VERSION "dbc-export 1 2025.20.8"

NS_ :

BS_:

BU_: ADSP APB APP APS APSB BB BMS CC CMP CMPD CP DAS DI DIF DIR DPB EPAS3P EPAS3S EPASTP EPASTS EPBL EPBR ESP EVSE FC GTW HCML HCMR HVP IBST ICR IDB LS OCS1P ODIN PARK PCS PLG PM PMF PMR PNCD PTC RADC RCM RCM2 RCM3 RCU SCCM SCM SCS SDCR TAS TCU TPMS TRCM UDS UI UIS UMC USM VC VCFRONT VCLEFT VCRIGHT VCSEC VEH

BO_ 1513 APP_alertLog: 8 APP
 SG_ APP_alertID M : 0|14@1+ (1,0) [0|16383] "" Vector__XXX
 SG_ APP_sw188_minTemperature m188 : 48|8@1+ (1,-60) [-60|194] "degC" Vector__XXX
 SG_ APP_sw188_maxTemperature m188 : 56|8@1+ (1,-60) [-60|194] "degC" Vector__XXX
 SG_ APP_sw189_exitStatus m189 : 16|1@1+ (1,0) [0|1] "" Vector__XXX
 SG_ APP_sw189_bufferError m189 : 17|1@1+ (1,0) [0|1] "" Vector__XXX
 SG_ APP_sw189_frameGrabFailure m189 : 18|1@1+ (1,0) [0|1] "" Vector__XXX
 SG_ APP_sw189_gainControlFailure m189 : 19|1@1+ (1,0) [0|1] "" Vector__XXX
 SG_ APP_sw189_tempMonitorFailure m189 : 20|2@1+ (1,0) [0|3] "" Vector__XXX
 SG_ APP_sw189_firstFrameGrabFailure m189 : 22|1@1+ (1,0) [0|1] "" Vector__XXX
 SG_ APP_sw189_deserParityError m189 : 23|1@1+ (1,0) [0|1] "" Vector__XXX
 SG_ APP_sw189_deserLockError m189 : 24|1@1+ (1,0) [0|1] "" Vector__XXX
 SG_ APP_sw189_deserCrcError m189 : 25|1@1+ (1,0) [0|1] "" Vector__XXX
 SG_ APP_sw189_imagerHeartbeat m189 : 26|2@1+ (1,0) [0|2] "" Vector__XXX
 SG_ APP_sw189_serializerCrcErrCount m189 : 28|8@1+ (1,0) [0|254] "" Vector__XXX
 SG_ APP_sw189_deserLineLengthError m189 : 36|1@1+ (1,0) [0|1] "" Vector__XXX
 SG_ APP_sw189_numCaptureRecoveries m189 : 37|3@1+ (1,0) [0|7] "" Vector__XXX
 SG_ APP_sw189_currentTemperature m189 : 40|8@1+ (1,-60) [-60|194] "degC" Vector__XXX
 SG_ APP_sw189_minTemperature m189 : 48|8@1+ (1,-60) [-60|194] "degC" Vector__XXX
 SG_ APP_sw189_maxTemperature m189 : 56|8@1+ (1,-60) [-60|194] "degC" Vector__XXX
 SG_ APP_sw190_exitStatus m190 : 16|1@1+ (1,0) [0|1] "" Vector__XXX
 SG_ APP_sw190_bufferError m190 : 17|1@1+ (1,0) [0|1] "" Vector__XXX
 SG_ APP_sw190_frameGrabFailure m190 : 18|1@1+ (1,0) [0|1] "" Vector__XXX
 SG_ APP_sw190_gainControlFailure m190 : 19|1@1+ (1,0) [0|1] "" Vector__XXX
 SG_ APP_sw190_tempMonitorFailure m190 : 20|2@1+ (1,0) [0|3] "" Vector__XXX
 SG_ APP_sw190_firstFrameGrabFailure m190 : 22|1@1+ (1,0) [0|1] "" Vector__XXX
 SG_ APP_sw190_deserParityError m190 : 23|1@1+ (1,0) [0|1] "" Vector__XXX
 SG_ APP_sw190_deserLockError m190 : 24|1@1+ (1,0) [0|1] "" Vector__XXX
 SG_ APP_sw190_deserCrcError m190 : 25|1@1+ (1,0) [0|1] "" Vector__XXX
 SG_ APP_sw190_imagerHeartbeat m190 : 26|2@1+ (1,0) [0|2] "" Vector__XXX
 SG_ APP_sw190_serializerCrcErrCount m190 : 28|8@1+ (1,0) [0|254] "" Vector__XXX
 SG_ APP_sw190_deserLineLengthError m190 : 36|1@1+ (1,0) [0|1] "" Vector__XXX
 SG_ APP_sw190_numCaptureRecoveries m190 : 37|3@1+ (1,0) [0|7] "" Vector__XXX
 SG_ APP_sw190_currentTemperature m190 : 40|8@1+ (1,-60) [-60|194] "degC" Vector__XXX
 SG_ APP_sw190_minTemperature m190 : 48|8@1+ (1,-60) [-60|194] "degC" Vector__XXX
 SG_ APP_sw190_maxTemperature m190 : 56|8@1+ (1,-60) [-60|194] "degC" Vector__XXX
 SG_ APP_sw191_abortReason m191 : 16|8@1+ (1,0) [0|255] "" Vector__XXX
 SG_ APP_sw191_handsOnState m191 : 24|4@1+ (1,0) [0|14] "" Vector__XXX
 SG_ APP_sw191_cruiseState m191 : 28|3@1+ (1,0) [0|7] "" Vector__XXX
 SG_ APP_sw191_epasErrorCode m191 : 32|4@1+ (1,0) [0|14] "" Vector__XXX
 SG_ APP_sw191_viewRange m191 : 40|8@1+ (1,0) [0|255] "m" Vector__XXX
 SG_ APP_sw191_roadClass m191 : 48|3@1+ (1,0) [1|7] "" Vector__XXX
 SG_ APP_sw191_referenceHealth m191 : 51|2@1+ (1,0) [0|3] "" Vector__XXX
 SG_ APP_sw191_solverHealth m191 : 53|2@1+ (1,0) [0|3] "" Vector__XXX
 SG_ APP_sw191_roadEstHealth m191 : 55|2@1+ (1,0) [0|3] "" Vector__XXX
 SG_ APP_sw191_roadEstMode m191 : 57|2@1+ (1,0) [0|3] "" Vector__XXX
 SG_ APP_sw191_radarFault m191 : 59|1@1+ (1,0) [0|1] "" Vector__XXX
 SG_ APP_sw191_radarBlind m191 : 60|1@1+ (1,0) [0|1] "" Vector__XXX
 SG_ APP_sw191_cameraFailsafes m191 : 61|3@1+ (1,0) [0|7] "" Vector__XXX
 SG_ APP_sw192_speakerFailureType m192 : 16|2@1+ (1,0) [0|3] "" Vector__XXX
 SG_ APP_sw192_chassisType m192 : 18|3@1+ (1,0) [0|7] "" Vector__XXX
 SG_ APP_sw192_hardwareType m192 : 21|2@1+ (1,0) [0|3] "" Vector__XXX
 SG_ APP_sw194_leadAx m194 : 16|6@1- (0.2,0) [-6.4|6.2] "m/s^2" Vector__XXX
 SG_ APP_sw194_leadDx m194 : 22|8@1+ (0.1,0) [0|25.5] "m" Vector__XXX
 SG_ APP_sw194_leadVx m194 : 30|6@1- (0.2,0) [-6.4|6.2] "m/s" Vector__XXX
 SG_ APP_sw194_numObstacles m194 : 36|4@1+ (1,0) [0|15] "" Vector__XXX
 SG_ APP_sw194_numPedstrian m194 : 40|4@1+ (1,0) [0|15] "" Vector__XXX
 SG_ APP_sw194_reasonForHold m194 : 44|4@1+ (1,0) [0|14] "" Vector__XXX
 SG_ APP_sw194_timeInHold m194 : 48|16@1+ (1,0) [0|65535] "" Vector__XXX
 SG_ APP_sw195_s1Blocked m195 : 16|1@1+ (1,0) [0|1] "" Vector__XXX
 SG_ APP_sw195_s6Blocked m195 : 17|1@1+ (1,0) [0|1] "" Vector__XXX
 SG_ APP_sw195_s7Blocked m195 : 18|1@1+ (1,0) [0|1] "" Vector__XXX
 SG_ APP_sw195_s8Blocked m195 : 19|1@1+ (1,0) [0|1] "" Vector__XXX
 SG_ APP_sw195_s11Blocked m195 : 20|1@1+ (1,0) [0|1] "" Vector__XXX
 SG_ APP_sw195_s12Blocked m195 : 21|1@1+ (1,0) [0|1] "" Vector__XXX
 SG_ APP_sw195_sdiFrontCC m195 : 24|5@1+ (1,0) [0|31] "" Vector__XXX
 SG_ APP_sw195_sdiRearCC m195 : 32|5@1+ (1,0) [0|31] "" Vector__XXX
 SG_ APP_sw195_sdiSystemNoise m195 : 37|2@1+ (1,0) [0|3] "" Vector__XXX
 SG_ APP_sw195_sdiSystemStatus m195 : 39|1@1+ (1,0) [0|1] "" Vector__XXX
 SG_ APP_sw195_vehicleSpeed m195 : 40|12@1+ (0.1,0) [0|409.5] "kph" Vector__XXX
 SG_ APP_sw199_abortCodeDas m199 : 16|6@1+ (1,0) [0|63] "" Vector__XXX
 SG_ APP_sw199_abortCodePARK m199 : 22|5@1+ (1,0) [0|30] "" Vector__XXX
 SG_ APP_sw199_currentSTW m199 : 27|14@1+ (0.1,-819.2) [-819.2|819.1] "deg" Vector__XXX
 SG_ APP_sw199_currentSpeed m199 : 41|8@1+ (0.1,-12.2) [-12.2|13.3] "mph" Vector__XXX
 SG_ APP_sw199_internalState m199 : 49|4@1+ (1,0) [0|15] "" Vector__XXX
 SG_ APP_sw199_maxSpeed m199 : 53|7@1+ (0.2,-12.2) [-12.2|13.2] "mph" Vector__XXX
 SG_ APP_sw199_numShifts m199 : 60|4@1+ (1,0) [0|15] "" Vector__XXX
 SG_ APP_sw203_controlType m203 : 16|4@1+ (1,0) [0|14] "" Vector__XXX
 SG_ APP_sw203_curbType m203 : 20|2@1+ (1,0) [0|3] "" Vector__XXX
 SG_ APP_sw203_roadClass m203 : 22|3@1+ (1,0) [0|7] "" Vector__XXX
 SG_ APP_sw203_slotSizeX m203 : 25|8@1+ (4,0) [0|1020] "cm" Vector__XXX
 SG_ APP_sw203_slotSizeY m203 : 33|8@1+ (4,0) [0|1020] "cm" Vector__XXX
 SG_ APP_sw203_startDistance m203 : 41|11@1+ (1,0) [0|2047] "cm" Vector__XXX
 SG_ APP_sw203_vehicleSkew m203 : 52|12@1+ (0.002,0) [0|8.19] "radians" Vector__XXX
 SG_ APP_sw204_frLeft m204 : 16|8@1+ (1,0) [0|255] "cm" Vector__XXX
 SG_ APP_sw204_frLeftMiddle m204 : 24|8@1+ (1,0) [0|255] "cm" Vector__XXX
 SG_ APP_sw204_frMiddle m204 : 32|8@1+ (1,0) [0|255] "cm" Vector__XXX
 SG_ APP_sw204_frRight m204 : 40|8@1+ (1,0) [0|255] "cm" Vector__XXX
 SG_ APP_sw204_frRightMiddle m204 : 48|8@1+ (1,0) [0|255] "cm" Vector__XXX
 SG_ APP_sw204_maxSpeed m204 : 56|8@1+ (0.1,-12.2) [-12.2|13.3] "mph" Vector__XXX
 SG_ APP_sw205_oocDistance m205 : 16|8@1+ (1,0) [0|255] "cm" Vector__XXX
 SG_ APP_sw205_rrLeft m205 : 24|8@1+ (1,0) [0|255] "cm" Vector__XXX
 SG_ APP_sw205_rrLeftMiddle m205 : 32|8@1+ (1,0) [0|255] "cm" Vector__XXX
 SG_ APP_sw205_rrMiddle m205 : 40|8@1+ (1,0) [0|255] "cm" Vector__XXX
 SG_ APP_sw205_rrRight m205 : 48|8@1+ (1,0) [0|255] "cm" Vector__XXX
 SG_ APP_sw205_rrRightMiddle m205 : 56|8@1+ (1,0) [0|255] "cm" Vector__XXX
 SG_ APP_sw207_appMobileyeStatus m207 : 16|8@1+ (1,0) [0|255] "" Vector__XXX
 SG_ APP_sw207_eyeq3MainState m207 : 24|8@1+ (1,0) [0|255] "" Vector__XXX
 SG_ APP_sw207_lcUnavailableReason m207 : 32|8@1+ (1,0) [0|255] "" Vector__XXX
 SG_ APP_sw213_autopilotIntState m213 : 16|4@1+ (1,0) [0|15] "" Vector__XXX
 SG_ APP_sw213_autopilotRestricted m213 : 20|1@1+ (1,0) [0|1] "" Vector__XXX
 SG_ APP_sw213_endSpeed m213 : 21|10@1+ (0.1,-10) [-10|92.3] "m/s" Vector__XXX
 SG_ APP_sw213_epasHandsOnDetected m213 : 31|1@1+ (1,0) [0|1] "" Vector__XXX
 SG_ APP_sw213_startSpeed m213 : 32|10@1+ (0.1,-10) [-10|92.3] "m/s" Vector__XXX
 SG_ APP_sw213_apIntStateAtTrigger m213 : 42|4@1+ (1,0) [0|15] "" Vector__XXX
 SG_ APP_sw213_takeoverDuration m213 : 48|8@1+ (0.5,0) [0|127.5] "s" Vector__XXX
 SG_ APP_sw218_cipvDist m218 : 16|8@1+ (0.2,0) [0|51] "m" Vector__XXX
 SG_ APP_sw218_drivingOnHighway m218 : 24|1@1+ (1,0) [0|1] "" Vector__XXX
 SG_ APP_sw218_handsOnState m218 : 25|4@1+ (1,0) [0|15] "" Vector__XXX
 SG_ APP_sw218_mcuAutosteerRestricted m218 : 29|1@1+ (1,0) [0|1] "" Vector__XXX
 SG_ APP_sw218_pedalPosition m218 : 32|7@1+ (1,0) [0|127] "%" Vector__XXX
 SG_ APP_sw219_controlledAccess m219 : 16|1@1+ (1,0) [0|1] "" Vector__XXX
 SG_ APP_sw219_roadClass m219 : 17|3@1+ (1,0) [0|7] "" Vector__XXX
 SG_ APP_sw219_vehicleSpeed m219 : 20|12@1+ (0.05,-25) [-25|179.75] "mph" Vector__XXX
 SG_ APP_sw230_sensor1Blocked m230 : 16|1@1+ (1,0) [0|1] "" Vector__XXX
 SG_ APP_sw230_sensor2Blocked m230 : 17|1@1+ (1,0) [0|1] "" Vector__XXX
 SG_ APP_sw230_sensor3Blocked m230 : 18|1@1+ (1,0) [0|1] "" Vector__XXX
 SG_ APP_sw230_sensor4Blocked m230 : 19|1@1+ (1,0) [0|1] "" Vector__XXX
 SG_ APP_sw230_sensor5Blocked m230 : 20|1@1+ (1,0) [0|1] "" Vector__XXX
 SG_ APP_sw230_sensor6Blocked m230 : 21|1@1+ (1,0) [0|1] "" Vector__XXX
 SG_ APP_sw230_sensor7Blocked m230 : 22|1@1+ (1,0) [0|1] "" Vector__XXX
 SG_ APP_sw230_sensor8Blocked m230 : 23|1@1+ (1,0) [0|1] "" Vector__XXX
 SG_ APP_sw230_sensor9Blocked m230 : 24|1@1+ (1,0) [0|1] "" Vector__XXX
 SG_ APP_sw230_sensor10Blocked m230 : 25|1@1+ (1,0) [0|1] "" Vector__XXX
 SG_ APP_sw230_sensor11Blocked m230 : 26|1@1+ (1,0) [0|1] "" Vector__XXX
 SG_ APP_sw230_sensor12Blocked m230 : 27|1@1+ (1,0) [0|1] "" Vector__XXX
 SG_ APP_sw260_target_dx m260 : 16|8@1+ (0.5,0) [0|127.5] "m" Vector__XXX
 SG_ APP_sw260_target_vx m260 : 24|8@1+ (0.2,-51) [-51|0] "m/s" Vector__XXX
 SG_ APP_sw260_target_ax m260 : 32|8@1+ (0.1,-15.5) [-15.5|10] "m/s2" Vector__XXX
 SG_ APP_sw260_ego_speed m260 : 40|8@1+ (0.2,0) [0|51] "m/s" Vector__XXX
 SG_ APP_sw260_driver_reaction_time m260 : 48|8@1+ (0.02,0) [0|5.1] "s" Vector__XXX
 SG_ APP_sw260_driver_reqd_accel m260 : 56|6@1+ (0.2,-12.6) [-12.6|1.7763568394e-15] "m/s2" Vector__XXX
 SG_ APP_sw260_user_sensitivity m260 : 62|2@1+ (1,0) [0|2] "" Vector__XXX
 SG_ APP_sw261_correctableErrors m261 : 16|8@1+ (1,0) [0|255] "" Vector__XXX
 SG_ APP_sw261_nonFatalUncorrErrors m261 : 24|8@1+ (1,0) [0|255] "" Vector__XXX
 SG_ APP_sw261_fatalUncorrErrors m261 : 32|8@1+ (1,0) [0|255] "" Vector__XXX
 SG_ APP_sw263_torsionThreshold m263 : 16|1@1+ (1,0) [0|1] "" Vector__XXX
 SG_ APP_sw263_eacStatusNotOk m263 : 17|1@1+ (1,0) [0|1] "" Vector__XXX
 SG_ APP_sw263_timerExpired m263 : 18|1@1+ (1,0) [0|1] "" Vector__XXX
 SG_ APP_sw263_notStableInLane m263 : 19|1@1+ (1,0) [0|1] "" Vector__XXX
 SG_ APP_sw263_outOfSpeedRegion m263 : 20|1@1+ (1,0) [0|1] "" Vector__XXX
 SG_ APP_sw263_laneTooNarrow m263 : 21|1@1+ (1,0) [0|1] "" Vector__XXX
 SG_ APP_sw263_elkConditionsMet m263 : 22|1@1+ (1,0) [0|1] "" Vector__XXX
 SG_ APP_sw263_lkaConditionsMet m263 : 23|1@1+ (1,0) [0|1] "" Vector__XXX
 SG_ APP_sw263_ldwConditionsMet m263 : 24|1@1+ (1,0) [0|1] "" Vector__XXX
 SG_ APP_sw263_multiLane m263 : 25|1@1+ (1,0) [0|1] "" Vector__XXX
 SG_ APP_sw263_noCollisionImminent m263 : 26|1@1+ (1,0) [0|1] "" Vector__XXX
 SG_ APP_sw263_blinkerActive m263 : 27|1@1+ (1,0) [0|1] "" Vector__XXX
 SG_ APP_sw263_notEncroaching m263 : 28|1@1+ (1,0) [0|1] "" Vector__XXX
 SG_ APP_sw263_dtleAboveThresholdLdw m263 : 29|1@1+ (1,0) [0|1] "" Vector__XXX
 SG_ APP_sw263_markerType m263 : 32|3@1+ (1,0) [0|7] "" Vector__XXX
 SG_ APP_sw263_side m263 : 35|1@1+ (1,0) [0|1] "" Vector__XXX
 SG_ APP_sw263_speed m263 : 36|8@1+ (1,0) [0|255] "m/s" Vector__XXX
 SG_ APP_sw263_laneWidth m263 : 44|7@1+ (0.05,0) [0|6.35] "m" Vector__XXX
 SG_ APP_sw263_vdcActive m263 : 51|1@1+ (1,0) [0|1] "" Vector__XXX
 SG_ APP_sw263_construction m263 : 52|1@1+ (1,0) [0|1] "" Vector__XXX
 SG_ APP_sw263_snowyRoad m263 : 53|1@1+ (1,0) [0|1] "" Vector__XXX
 SG_ APP_sw263_sideObstacle m263 : 54|1@1+ (1,0) [0|1] "" Vector__XXX
 SG_ APP_sw263_frontObstacle m263 : 55|1@1+ (1,0) [0|1] "" Vector__XXX
 SG_ APP_sw263_turnIndicatorOn m263 : 56|1@1+ (1,0) [0|1] "" Vector__XXX
 SG_ APP_sw263_vehicleMuLow m263 : 57|1@1+ (1,0) [0|1] "" Vector__XXX
 SG_ APP_sw263_lssAbortReason m263 : 58|5@1+ (1,0) [0|31] "" Vector__XXX
 SG_ APP_sw264_faultReason m264 : 16|5@1+ (1,0) [0|31] "" Vector__XXX
 SG_ APP_sw265_mpHasRoute m265 : 16|1@1+ (1,0) [0|1] "" Vector__XXX
 SG_ APP_sw265_mpLocalizedWay m265 : 17|1@1+ (1,0) [0|1] "" Vector__XXX
 SG_ APP_sw265_mmHasRoute m265 : 18|1@1+ (1,0) [0|1] "" Vector__XXX
 SG_ APP_sw265_mmLocalizedEdge m265 : 19|1@1+ (1,0) [0|1] "" Vector__XXX
 SG_ APP_sw265_surroundCameraStatus m265 : 20|2@1+ (1,0) [0|3] "" Vector__XXX
 SG_ APP_sw265_unavailableReason m265 : 24|5@1+ (1,0) [0|31] "" Vector__XXX
 SG_ APP_sw265_leftPillarBlocked m265 : 29|1@1+ (1,0) [0|1] "" Vector__XXX
 SG_ APP_sw265_rightPillarBlocked m265 : 30|1@1+ (1,0) [0|1] "" Vector__XXX
 SG_ APP_sw265_leftRepeaterBlocked m265 : 31|1@1+ (1,0) [0|1] "" Vector__XXX
 SG_ APP_sw265_rightRepeaterBlocked m265 : 32|1@1+ (1,0) [0|1] "" Vector__XXX
 SG_ APP_sw265_backupBlocked m265 : 33|1@1+ (1,0) [0|1] "" Vector__XXX
 SG_ APP_sw265_exceptionListInvalid m265 : 34|1@1+ (1,0) [0|1] "" Vector__XXX
 SG_ APP_sw265_lPillarLanesFailsafe m265 : 35|1@1+ (1,0) [0|1] "" Vector__XXX
 SG_ APP_sw265_rPillarLanesFailsafe m265 : 36|1@1+ (1,0) [0|1] "" Vector__XXX
 SG_ APP_sw265_lRepeaterLanesFailsafe m265 : 37|1@1+ (1,0) [0|1] "" Vector__XXX
 SG_ APP_sw265_rRepeaterLanesFailsafe m265 : 38|1@1+ (1,0) [0|1] "" Vector__XXX
 SG_ APP_sw266_lPillarStreamStatus m266 : 16|3@1+ (1,0) [0|7] "" Vector__XXX
 SG_ APP_sw266_rPillarStreamStatus m266 : 19|3@1+ (1,0) [0|7] "" Vector__XXX
 SG_ APP_sw266_lRepeaterStreamStatus m266 : 24|3@1+ (1,0) [0|7] "" Vector__XXX
 SG_ APP_sw266_rRepeaterStreamStatus m266 : 27|3@1+ (1,0) [0|7] "" Vector__XXX
 SG_ APP_sw266_backupStreamStatus m266 : 32|3@1+ (1,0) [0|7] "" Vector__XXX
 SG_ APP_sw269_mainStreamExit m269 : 16|1@1+ (1,0) [0|1] "" Vector__XXX
 SG_ APP_sw269_narrowStreamExit m269 : 17|1@1+ (1,0) [0|1] "" Vector__XXX
 SG_ APP_sw269_fisheyeStreamExit m269 : 18|1@1+ (1,0) [0|1] "" Vector__XXX
 SG_ APP_sw269_lPillarStreamExit m269 : 19|1@1+ (1,0) [0|1] "" Vector__XXX
 SG_ APP_sw269_rPillarStreamExit m269 : 20|1@1+ (1,0) [0|1] "" Vector__XXX
 SG_ APP_sw269_lRepeaterStreamExit m269 : 21|1@1+ (1,0) [0|1] "" Vector__XXX
 SG_ APP_sw269_rRepeaterStreamExit m269 : 22|1@1+ (1,0) [0|1] "" Vector__XXX
 SG_ APP_sw269_mainBlocked m269 : 23|1@1+ (1,0) [0|1] "" Vector__XXX
 SG_ APP_sw269_narrowBlocked m269 : 24|1@1+ (1,0) [0|1] "" Vector__XXX
 SG_ APP_sw269_fisheyeBlocked m269 : 25|1@1+ (1,0) [0|1] "" Vector__XXX
 SG_ APP_sw269_lPillarBlocked m269 : 26|1@1+ (1,0) [0|1] "" Vector__XXX
 SG_ APP_sw269_rPillarBlocked m269 : 27|1@1+ (1,0) [0|1] "" Vector__XXX
 SG_ APP_sw269_lRepeaterBlocked m269 : 28|1@1+ (1,0) [0|1] "" Vector__XXX
 SG_ APP_sw269_rRepeaterBlocked m269 : 29|1@1+ (1,0) [0|1] "" Vector__XXX
 SG_ APP_sw269_lPillarLanesFailsafe m269 : 30|1@1+ (1,0) [0|1] "" Vector__XXX
 SG_ APP_sw269_rPillarLanesFailsafe m269 : 31|1@1+ (1,0) [0|1] "" Vector__XXX
 SG_ APP_sw269_lRepeaterLanesFailsafe m269 : 32|1@1+ (1,0) [0|1] "" Vector__XXX
 SG_ APP_sw269_rRepeaterLanesFailsafe m269 : 33|1@1+ (1,0) [0|1] "" Vector__XXX
 SG_ APP_sw269_aebOffInOffRoadMode m269 : 34|1@1+ (1,0) [0|1] "" Vector__XXX
 SG_ APP_sw269_emergencyLaneKeep m269 : 35|5@1+ (1,0) [0|30] "" Vector__XXX
 SG_ APP_sw269_laneKeepAssist m269 : 40|5@1+ (1,0) [0|30] "" Vector__XXX
 SG_ APP_sw269_blindspot m269 : 48|5@1+ (1,0) [0|30] "" Vector__XXX
 SG_ APP_sw269_laneDepartureWarning m269 : 56|5@1+ (1,0) [0|30] "" Vector__XXX
 SG_ APP_sw270_mainStreamExit m270 : 16|1@1+ (1,0) [0|1] "" Vector__XXX
 SG_ APP_sw270_lPillarStreamExit m270 : 17|1@1+ (1,0) [0|1] "" Vector__XXX
 SG_ APP_sw270_rPillarStreamExit m270 : 18|1@1+ (1,0) [0|1] "" Vector__XXX
 SG_ APP_sw270_lRepeaterStreamExit m270 : 19|1@1+ (1,0) [0|1] "" Vector__XXX
 SG_ APP_sw270_rRepeaterStreamExit m270 : 20|1@1+ (1,0) [0|1] "" Vector__XXX
 SG_ APP_sw270_lPillarBlocked m270 : 21|1@1+ (1,0) [0|1] "" Vector__XXX
 SG_ APP_sw270_rPillarBlocked m270 : 22|1@1+ (1,0) [0|1] "" Vector__XXX
 SG_ APP_sw270_lRepeaterBlocked m270 : 23|1@1+ (1,0) [0|1] "" Vector__XXX
 SG_ APP_sw270_rRepeaterBlocked m270 : 24|1@1+ (1,0) [0|1] "" Vector__XXX
 SG_ APP_sw270_lPillarLanesFailsafe m270 : 25|1@1+ (1,0) [0|1] "" Vector__XXX
 SG_ APP_sw270_rPillarLanesFailsafe m270 : 26|1@1+ (1,0) [0|1] "" Vector__XXX
 SG_ APP_sw270_lRepeaterLanesFailsafe m270 : 27|1@1+ (1,0) [0|1] "" Vector__XXX
 SG_ APP_sw270_rRepeaterLanesFailsafe m270 : 28|1@1+ (1,0) [0|1] "" Vector__XXX
 SG_ APP_sw270_mainBlocked m270 : 29|1@1+ (1,0) [0|1] "" Vector__XXX
 SG_ APP_sw270_narrowBlocked m270 : 30|1@1+ (1,0) [0|1] "" Vector__XXX
 SG_ APP_sw270_fisheyeBlocked m270 : 31|1@1+ (1,0) [0|1] "" Vector__XXX
 SG_ APP_sw270_aebOffInOffRoadMode m270 : 32|1@1+ (1,0) [0|1] "" Vector__XXX
 SG_ APP_sw270_emergencyLaneKeep m270 : 33|5@1+ (1,0) [0|30] "" Vector__XXX
 SG_ APP_sw270_laneKeepAssist m270 : 40|5@1+ (1,0) [0|30] "" Vector__XXX
 SG_ APP_sw270_blindspot m270 : 48|5@1+ (1,0) [0|30] "" Vector__XXX
 SG_ APP_sw270_laneDepartureWarning m270 : 56|5@1+ (1,0) [0|30] "" Vector__XXX
 SG_ APP_sw271_abortReason m271 : 16|5@1+ (1,0) [0|31] "" Vector__XXX
 SG_ APP_sw271_direction m271 : 21|1@1+ (1,0) [0|1] "" Vector__XXX
 SG_ APP_sw271_progress m271 : 24|8@1+ (0.0039215,0) [0|0.9999825] "%" Vector__XXX
 SG_ APP_sw271_egoSpeed m271 : 32|8@1+ (0.2,0) [0|51] "m/s" Vector__XXX
 SG_ APP_sw272_unavailableReason m272 : 16|4@1+ (1,0) [0|15] "" Vector__XXX
 SG_ APP_sw272_lPillarStreamExit m272 : 20|1@1+ (1,0) [0|1] "" Vector__XXX
 SG_ APP_sw272_rPillarStreamExit m272 : 21|1@1+ (1,0) [0|1] "" Vector__XXX
 SG_ APP_sw272_lRepeaterStreamExit m272 : 22|1@1+ (1,0) [0|1] "" Vector__XXX
 SG_ APP_sw272_rRepeaterStreamExit m272 : 23|1@1+ (1,0) [0|1] "" Vector__XXX
 SG_ APP_sw272_lPillarBlocked m272 : 24|1@1+ (1,0) [0|1] "" Vector__XXX
 SG_ APP_sw272_rPillarBlocked m272 : 25|1@1+ (1,0) [0|1] "" Vector__XXX
 SG_ APP_sw272_lRepeaterBlocked m272 : 26|1@1+ (1,0) [0|1] "" Vector__XXX
 SG_ APP_sw272_rRepeaterBlocked m272 : 27|1@1+ (1,0) [0|1] "" Vector__XXX
 SG_ APP_sw273_eventType m273 : 16|1@1+ (1,0) [0|1] "" Vector__XXX
 SG_ APP_sw273_collisionType m273 : 17|3@1+ (1,0) [0|7] "" Vector__XXX
 SG_ APP_sw273_side m273 : 20|1@1+ (1,0) [0|1] "" Vector__XXX
 SG_ APP_sw273_alarmStrikes m273 : 21|3@1+ (1,0) [0|7] "" Vector__XXX
 SG_ APP_sw273_handsOn m273 : 24|1@1+ (1,0) [0|1] "" Vector__XXX
 SG_ APP_sw273_timeToCollision m273 : 25|8@1+ (0.02,0) [0|5.1] "seconds" Vector__XXX
 SG_ APP_sw273_lngDistanceToVehicle m273 : 33|8@1+ (0.02,0) [0|5.1] "meters" Vector__XXX
 SG_ APP_sw273_latDistanceToVehicle m273 : 41|8@1+ (0.02,0) [0|5.1] "meters" Vector__XXX
 SG_ APP_sw273_timeToLaneExit m273 : 49|7@1+ (0.02,0) [0|2.54] "seconds" Vector__XXX
 SG_ APP_sw273_distanceToLaneExit m273 : 56|8@1- (0.02,0) [-2.56|2.54] "meters" Vector__XXX
 SG_ APP_sw283_appAbortReason m283 : 16|5@1+ (1,0) [0|31] "" Vector__XXX
 SG_ APP_sw283_apsAbortReason m283 : 21|6@1+ (1,0) [0|63] "" Vector__XXX
 SG_ APP_sw283_distanceTravelled m283 : 27|10@1+ (0.1,0) [0|102.3] "m" Vector__XXX
 SG_ APP_sw283_phoneDistance m283 : 37|9@1+ (0.2,0) [0|102.2] "m" Vector__XXX
 SG_ APP_sw283_goalDistance m283 : 46|10@1+ (0.1,0) [0|102.3] "m" Vector__XXX
 SG_ APP_sw283_mainCam m283 : 56|1@1+ (1,0) [0|1] "" Vector__XXX
 SG_ APP_sw283_narrowCam m283 : 57|1@1+ (1,0) [0|1] "" Vector__XXX
 SG_ APP_sw283_fisheyeCam m283 : 58|1@1+ (1,0) [0|1] "" Vector__XXX
 SG_ APP_sw283_leftRepeaterCam m283 : 59|1@1+ (1,0) [0|1] "" Vector__XXX
 SG_ APP_sw283_rightRepeaterCam m283 : 60|1@1+ (1,0) [0|1] "" Vector__XXX
 SG_ APP_sw283_leftPillarCam m283 : 61|1@1+ (1,0) [0|1] "" Vector__XXX
 SG_ APP_sw283_rightPillarCam m283 : 62|1@1+ (1,0) [0|1] "" Vector__XXX
 SG_ APP_sw283_bucCam m283 : 63|1@1+ (1,0) [0|1] "" Vector__XXX
 SG_ APP_sw284_antennaDisconnected m284 : 16|1@1+ (1,0) [0|1] "" Vector__XXX
 SG_ APP_sw285_gpsCommMissing m285 : 16|1@1+ (1,0) [0|1] "" Vector__XXX
 SG_ APP_sw285_gpsJunkData m285 : 17|1@1+ (1,0) [0|1] "" Vector__XXX
 SG_ APP_sw285_gpsNMEAmissing m285 : 18|1@1+ (1,0) [0|1] "" Vector__XXX
 SG_ APP_sw285_gpsUBXmissing m285 : 19|1@1+ (1,0) [0|1] "" Vector__XXX
 SG_ APP_sw285_fusionModeDisabled m285 : 20|1@1+ (1,0) [0|1] "" Vector__XXX
 SG_ APP_sw285_gpsCfgFail m285 : 21|1@1+ (1,0) [0|1] "" Vector__XXX
 SG_ APP_sw285_esfStatusMsgMIA m285 : 22|1@1+ (1,0) [0|1] "" Vector__XXX
 SG_ APP_sw285_wheelTickCfgMissmatch m285 : 23|1@1+ (1,0) [0|1] "" Vector__XXX
 SG_ APP_sw285_exitTransportMode m285 : 24|1@1+ (1,0) [0|1] "" Vector__XXX
 SG_ APP_sw285_satRejectionTimeout m285 : 25|1@1+ (1,0) [0|1] "" Vector__XXX
 SG_ APP_sw285_gpsPPSMissing m285 : 26|1@1+ (1,0) [0|1] "" Vector__XXX
 SG_ APP_sw286_cfgBufNull m286 : 16|1@1+ (1,0) [0|1] "" Vector__XXX
 SG_ APP_sw286_invalidID m286 : 17|1@1+ (1,0) [0|1] "" Vector__XXX
 SG_ APP_sw286_gpsBufferOverflow m286 : 18|1@1+ (1,0) [0|1] "" Vector__XXX
 SG_ APP_sw286_navx5CfgFailed m286 : 19|1@1+ (1,0) [0|1] "" Vector__XXX
 SG_ APP_sw286_mcuNMEAmsgUDPinvalid m286 : 20|1@1+ (1,0) [0|1] "" Vector__XXX
 SG_ APP_sw286_mcuDbgMsgInvalid m286 : 21|1@1+ (1,0) [0|1] "" Vector__XXX
 SG_ APP_sw286_mcuDbgMsgTooBig m286 : 22|1@1+ (1,0) [0|1] "" Vector__XXX
 SG_ APP_sw286_mcuFwdNMEAfail m286 : 23|1@1+ (1,0) [0|1] "" Vector__XXX
 SG_ APP_sw286_NMEAinvalidChecksum m286 : 24|1@1+ (1,0) [0|1] "" Vector__XXX
 SG_ APP_sw286_unexpectedNMEAmsg m286 : 25|1@1+ (1,0) [0|1] "" Vector__XXX
 SG_ APP_sw286_UARTbusFull m286 : 26|1@1+ (1,0) [0|1] "" Vector__XXX
 SG_ APP_sw286_UARTframeError m286 : 27|1@1+ (1,0) [0|1] "" Vector__XXX
 SG_ APP_sw286_UBXrxFrameTooBig m286 : 28|1@1+ (1,0) [0|1] "" Vector__XXX
 SG_ APP_sw286_emptyValidNMEA m286 : 29|1@1+ (1,0) [0|1] "" Vector__XXX
 SG_ APP_sw286_invalidAsciiNMEA m286 : 30|1@1+ (1,0) [0|1] "" Vector__XXX
 SG_ APP_sw286_wheeltickUARTfault m286 : 31|1@1+ (1,0) [0|1] "" Vector__XXX
 SG_ APP_sw286_baudrateMismatch m286 : 32|1@1+ (1,0) [0|1] "" Vector__XXX
 SG_ APP_sw286_wheelTickInvalidSrc m286 : 33|1@1+ (1,0) [0|1] "" Vector__XXX
 SG_ APP_sw286_UARTparityError m286 : 34|1@1+ (1,0) [0|1] "" Vector__XXX
 SG_ APP_sw286_UARTrxFifoOverflow m286 : 35|1@1+ (1,0) [0|1] "" Vector__XXX
 SG_ APP_sw286_UARTrxFifoUnderflow m286 : 36|1@1+ (1,0) [0|1] "" Vector__XXX
 SG_ APP_sw286_UARTtxFifoOverflow m286 : 37|1@1+ (1,0) [0|1] "" Vector__XXX
 SG_ APP_sw286_esfWtMsgTimeout m286 : 38|1@1+ (1,0) [0|1] "" Vector__XXX
 SG_ APP_sw286_PFLASHReadError m286 : 39|1@1+ (1,0) [0|1] "" Vector__XXX
 SG_ APP_sw286_PFLASHWriteError m286 : 40|1@1+ (1,0) [0|1] "" Vector__XXX
 SG_ APP_sw286_gpsCfgNack m286 : 41|1@1+ (1,0) [0|1] "" Vector__XXX
 SG_ APP_sw286_gpsCfgIdFail m286 : 42|6@1+ (1,0) [0|63] "" Vector__XXX
 SG_ APP_sw286_gpsSetCfgNoAck m286 : 48|1@1+ (1,0) [0|1] "" Vector__XXX
 SG_ APP_sw286_gpsReadCfgNoResponse m286 : 49|1@1+ (1,0) [0|1] "" Vector__XXX
 SG_ APP_sw286_ubxErrorReported m286 : 50|1@1+ (1,0) [0|1] "" Vector__XXX
 SG_ APP_sw288_dist_to_stop m288 : 16|8@1+ (0.5,0) [0|127.5] "m" Vector__XXX
 SG_ APP_sw288_ego_speed m288 : 24|8@1+ (0.2,0) [0|51] "m/s" Vector__XXX
 SG_ APP_sw288_ego_acceleration m288 : 32|8@1+ (0.1,-15.5) [-15.5|10] "m/s2" Vector__XXX
 SG_ APP_sw291_dist_to_stop m291 : 16|8@1+ (0.5,0) [0|127.5] "m" Vector__XXX
 SG_ APP_sw291_ego_speed m291 : 24|8@1+ (0.2,0) [0|51] "m/s" Vector__XXX
 SG_ APP_sw291_ego_acceleration m291 : 32|8@1+ (0.1,-15.5) [-15.5|10] "m/s2" Vector__XXX
 SG_ APP_sw293_clockFrequencyDrift m293 : 16|16@1- (0.0005,0) [-16.384|16.3835] "%" Vector__XXX
 SG_ APP_sw294_clockFrequencyDrift m294 : 16|16@1- (0.0005,0) [-16.384|16.3835] "%" Vector__XXX
 SG_ APP_sw295_clockFrequencyDrift m295 : 16|16@1- (0.0005,0) [-16.384|16.3835] "%" Vector__XXX
 SG_ APP_sw296_clockFrequencyDrift m296 : 16|16@1- (0.0005,0) [-16.384|16.3835] "%" Vector__XXX
 SG_ APP_sw297_clockFrequencyDrift m297 : 16|16@1- (0.0005,0) [-16.384|16.3835] "%" Vector__XXX
 SG_ APP_sw298_clockFrequencyDrift m298 : 16|16@1- (0.0005,0) [-16.384|16.3835] "%" Vector__XXX
 SG_ APP_sw299_clockFrequencyDrift m299 : 16|16@1- (0.0005,0) [-16.384|16.3835] "%" Vector__XXX
 SG_ APP_sw300_clockFrequencyDrift m300 : 16|16@1- (0.0005,0) [-16.384|16.3835] "%" Vector__XXX
 SG_ APP_sw301_clockFrequencyDrift m301 : 16|16@1- (0.0005,0) [-16.384|16.3835] "%" Vector__XXX
 SG_ APP_sw302_AP_vehicleState10Hz m302 : 16|1@1+ (1,0) [0|1] "" Vector__XXX
 SG_ APP_sw304_lssLPillarBlocked m304 : 16|1@1+ (1,0) [0|1] "" Vector__XXX
 SG_ APP_sw304_lssRPillarBlocked m304 : 17|1@1+ (1,0) [0|1] "" Vector__XXX
 SG_ APP_sw304_lssLRepeaterBlocked m304 : 18|1@1+ (1,0) [0|1] "" Vector__XXX
 SG_ APP_sw304_lssRRepeaterBlocked m304 : 19|1@1+ (1,0) [0|1] "" Vector__XXX
 SG_ APP_sw304_lssMainBlocked m304 : 20|1@1+ (1,0) [0|1] "" Vector__XXX
 SG_ APP_sw305_lssLPillarStreamExit m305 : 16|1@1+ (1,0) [0|1] "" Vector__XXX
 SG_ APP_sw305_lssRPillarStreamExit m305 : 17|1@1+ (1,0) [0|1] "" Vector__XXX
 SG_ APP_sw305_lssLRepeaterStreamExit m305 : 18|1@1+ (1,0) [0|1] "" Vector__XXX
 SG_ APP_sw305_lssRRepeaterStreamExit m305 : 19|1@1+ (1,0) [0|1] "" Vector__XXX
 SG_ APP_sw306_lssUssS1Blocked m306 : 16|1@1+ (1,0) [0|1] "" Vector__XXX
 SG_ APP_sw306_lssUssS2Blocked m306 : 17|1@1+ (1,0) [0|1] "" Vector__XXX
 SG_ APP_sw306_lssUssS3Blocked m306 : 18|1@1+ (1,0) [0|1] "" Vector__XXX
 SG_ APP_sw306_lssUssS4Blocked m306 : 19|1@1+ (1,0) [0|1] "" Vector__XXX
 SG_ APP_sw306_lssUssS5Blocked m306 : 20|1@1+ (1,0) [0|1] "" Vector__XXX
 SG_ APP_sw306_lssUssS6Blocked m306 : 21|1@1+ (1,0) [0|1] "" Vector__XXX
 SG_ APP_sw306_lssUssS7Blocked m306 : 22|1@1+ (1,0) [0|1] "" Vector__XXX
 SG_ APP_sw306_lssUssS8Blocked m306 : 23|1@1+ (1,0) [0|1] "" Vector__XXX
 SG_ APP_sw306_lssUssS9Blocked m306 : 24|1@1+ (1,0) [0|1] "" Vector__XXX
 SG_ APP_sw306_lssUssS10Blocked m306 : 25|1@1+ (1,0) [0|1] "" Vector__XXX
 SG_ APP_sw306_lssUssS11Blocked m306 : 26|1@1+ (1,0) [0|1] "" Vector__XXX
 SG_ APP_sw306_lssUssS12Blocked m306 : 27|1@1+ (1,0) [0|1] "" Vector__XXX
 SG_ APP_sw307_lssTurnSignalFLFault m307 : 16|1@1+ (1,0) [0|1] "" Vector__XXX
 SG_ APP_sw307_lssTurnSignalFRFault m307 : 17|1@1+ (1,0) [0|1] "" Vector__XXX
 SG_ APP_sw307_lssTurnSignalRLFault m307 : 18|1@1+ (1,0) [0|1] "" Vector__XXX
 SG_ APP_sw307_lssTurnSignalRRFault m307 : 19|1@1+ (1,0) [0|1] "" Vector__XXX
 SG_ APP_sw308_IBST_status m308 : 16|1@1+ (1,0) [0|1] "" Vector__XXX
 SG_ APP_sw321_energyStatus m321 : 16|1@1+ (1,0) [0|1] "" Vector__XXX
 SG_ APP_sw321_status m321 : 17|1@1+ (1,0) [0|1] "" Vector__XXX
 SG_ APP_sw322_sunGlare m322 : 16|1@1+ (1,0) [0|1] "" Vector__XXX
 SG_ APP_sw322_blinded m322 : 17|1@1+ (1,0) [0|1] "" Vector__XXX
 SG_ APP_sw322_falseWipe m322 : 18|1@1+ (1,0) [0|1] "" Vector__XXX
 SG_ APP_sw323_confidence m323 : 16|8@1+ (0.004,0) [0|1.02] "-" Vector__XXX
 SG_ APP_sw323_distance m323 : 24|8@1+ (0.5,0) [0|127.5] "m" Vector__XXX
 SG_ APP_sw323_ttc m323 : 32|8@1+ (0.02,0) [0|5.1] "s" Vector__XXX
 SG_ APP_sw324_state m324 : 16|1@1+ (1,0) [0|1] "" Vector__XXX
 SG_ APP_sw325_taskId m325 : 16|7@1+ (1,0) [0|127] "" Vector__XXX
 SG_ APP_sw325_issue m325 : 24|5@1+ (1,0) [0|31] "" Vector__XXX
 SG_ APP_sw327_driveHandSideMismatch m327 : 16|1@1+ (1,0) [0|1] "" Vector__XXX
 SG_ APP_sw327_hardwareTypeMismatch m327 : 17|1@1+ (1,0) [0|1] "" Vector__XXX
 SG_ APP_sw327_turboTypeMismatch m327 : 18|1@1+ (1,0) [0|1] "" Vector__XXX
 SG_ APP_sw327_epasTypeMismatch m327 : 19|1@1+ (1,0) [0|1] "" Vector__XXX
 SG_ APP_sw327_radarTypeMismatch m327 : 20|1@1+ (1,0) [0|1] "" Vector__XXX
 SG_ APP_sw327_chassisTypeMismatch m327 : 21|1@1+ (1,0) [0|1] "" Vector__XXX
 SG_ APP_sw327_displayTypeMismatch m327 : 22|1@1+ (1,0) [0|1] "" Vector__XXX
 SG_ APP_sw327_cameraTypeMismatch m327 : 23|1@1+ (1,0) [0|1] "" Vector__XXX
 SG_ APP_sw327_parkAssistTypeMismatch m327 : 24|1@1+ (1,0) [0|1] "" Vector__XXX
 SG_ APP_sw327_selfieCamTypeMismatch m327 : 25|1@1+ (1,0) [0|1] "" Vector__XXX
 SG_ APP_sw328_ussS1Unavailable m328 : 16|1@1+ (1,0) [0|1] "" Vector__XXX
 SG_ APP_sw328_ussS2Unavailable m328 : 17|1@1+ (1,0) [0|1] "" Vector__XXX
 SG_ APP_sw328_ussS3Unavailable m328 : 18|1@1+ (1,0) [0|1] "" Vector__XXX
 SG_ APP_sw328_ussS4Unavailable m328 : 19|1@1+ (1,0) [0|1] "" Vector__XXX
 SG_ APP_sw328_ussS5Unavailable m328 : 20|1@1+ (1,0) [0|1] "" Vector__XXX
 SG_ APP_sw328_ussS6Unavailable m328 : 21|1@1+ (1,0) [0|1] "" Vector__XXX
 SG_ APP_sw328_ussS7Unavailable m328 : 22|1@1+ (1,0) [0|1] "" Vector__XXX
 SG_ APP_sw328_ussS8Unavailable m328 : 23|1@1+ (1,0) [0|1] "" Vector__XXX
 SG_ APP_sw328_ussS9Unavailable m328 : 24|1@1+ (1,0) [0|1] "" Vector__XXX
 SG_ APP_sw328_ussS10Unavailable m328 : 25|1@1+ (1,0) [0|1] "" Vector__XXX
 SG_ APP_sw328_ussS11Unavailable m328 : 26|1@1+ (1,0) [0|1] "" Vector__XXX
 SG_ APP_sw328_ussS12Unavailable m328 : 27|1@1+ (1,0) [0|1] "" Vector__XXX
 SG_ APP_sw328_fisheyeStreamExit m328 : 28|1@1+ (1,0) [0|1] "" Vector__XXX
 SG_ APP_sw328_lPillarStreamExit m328 : 29|1@1+ (1,0) [0|1] "" Vector__XXX
 SG_ APP_sw328_rPillarStreamExit m328 : 30|1@1+ (1,0) [0|1] "" Vector__XXX
 SG_ APP_sw328_lRepeaterStreamExit m328 : 31|1@1+ (1,0) [0|1] "" Vector__XXX
 SG_ APP_sw328_rRepeaterStreamExit m328 : 32|1@1+ (1,0) [0|1] "" Vector__XXX
 SG_ APP_sw328_backupStreamExit m328 : 33|1@1+ (1,0) [0|1] "" Vector__XXX
 SG_ APP_sw328_fisheyeCal m328 : 34|1@1+ (1,0) [0|1] "" Vector__XXX
 SG_ APP_sw328_lPillarCal m328 : 35|1@1+ (1,0) [0|1] "" Vector__XXX
 SG_ APP_sw328_rPillarCal m328 : 36|1@1+ (1,0) [0|1] "" Vector__XXX
 SG_ APP_sw328_lRepeaterCal m328 : 37|1@1+ (1,0) [0|1] "" Vector__XXX
 SG_ APP_sw328_rRepeaterCal m328 : 38|1@1+ (1,0) [0|1] "" Vector__XXX
 SG_ APP_sw328_backupCal m328 : 39|1@1+ (1,0) [0|1] "" Vector__XXX
 SG_ APP_sw328_epasMia m328 : 40|1@1+ (1,0) [0|1] "" Vector__XXX
 SG_ APP_sw328_espMia m328 : 41|1@1+ (1,0) [0|1] "" Vector__XXX
 SG_ APP_sw328_parkMia m328 : 42|1@1+ (1,0) [0|1] "" Vector__XXX
 SG_ APP_sw328_sccmMia m328 : 43|1@1+ (1,0) [0|1] "" Vector__XXX
 SG_ APP_sw328_scMia m328 : 44|1@1+ (1,0) [0|1] "" Vector__XXX
 SG_ APP_sw328_ussOLONotEnabled m328 : 45|1@1+ (1,0) [0|1] "" Vector__XXX
 SG_ APP_sw328_ussPASNotEnabled m328 : 46|1@1+ (1,0) [0|1] "" Vector__XXX
 SG_ APP_sw328_ussOOCNotEnabled m328 : 47|1@1+ (1,0) [0|1] "" Vector__XXX
 SG_ APP_sw328_ussTemporaryFault m328 : 48|1@1+ (1,0) [0|1] "" Vector__XXX
 SG_ APP_sw328_ussSystemError m328 : 49|1@1+ (1,0) [0|1] "" Vector__XXX
 SG_ APP_sw328_ussFault m328 : 50|1@1+ (1,0) [0|1] "" Vector__XXX
 SG_ APP_sw328_ussStatusOutOfDate m328 : 51|1@1+ (1,0) [0|1] "" Vector__XXX
 SG_ APP_sw328_perceptionUnhealthy m328 : 52|1@1+ (1,0) [0|1] "" Vector__XXX
 SG_ APP_sw328_drivableSpaceUnhealthy m328 : 53|1@1+ (1,0) [0|1] "" Vector__XXX
 SG_ APP_sw328_uiDisplayNotOk m328 : 54|1@1+ (1,0) [0|1] "" Vector__XXX
 SG_ APP_sw328_externalLightsOff m328 : 55|1@1+ (1,0) [0|1] "" Vector__XXX
 SG_ APP_sw328_forwardCamerasBlinded m328 : 56|1@1+ (1,0) [0|1] "" Vector__XXX
 SG_ APP_sw328_backupCameraBlinded m328 : 57|1@1+ (1,0) [0|1] "" Vector__XXX
 SG_ APP_sw328_extComputeNotActive m328 : 58|1@1+ (1,0) [0|1] "" Vector__XXX
 SG_ APP_sw329_cipvSysReqAccel m329 : 16|7@1+ (0.15625,-10) [-10|9.84375] "m/s^2" Vector__XXX
 SG_ APP_sw329_leftLaneReqAccel m329 : 24|7@1+ (0.15625,-10) [-10|9.84375] "m/s^2" Vector__XXX
 SG_ APP_sw329_rightLaneReqAccel m329 : 32|7@1+ (0.15625,-10) [-10|9.84375] "m/s^2" Vector__XXX
 SG_ APP_sw329_leftLaneAvailable m329 : 39|1@1+ (1,0) [0|1] "" Vector__XXX
 SG_ APP_sw329_rightLaneAvailable m329 : 40|1@1+ (1,0) [0|1] "" Vector__XXX
 SG_ APP_sw329_laneChangeLeft m329 : 41|1@1+ (1,0) [0|1] "" Vector__XXX
 SG_ APP_sw329_laneChangeRight m329 : 42|1@1+ (1,0) [0|1] "" Vector__XXX
 SG_ APP_sw329_leftLaneChngBehStatus m329 : 43|5@1+ (1,0) [0|31] "" Vector__XXX
 SG_ APP_sw329_rightLaneChngBehStatus m329 : 48|5@1+ (1,0) [0|31] "" Vector__XXX
 SG_ APP_sw330_initFailure m330 : 16|1@1+ (1,0) [0|1] "" Vector__XXX
 SG_ APP_sw330_streamExit m330 : 17|1@1+ (1,0) [0|1] "" Vector__XXX
 SG_ APP_sw330_ledFault m330 : 18|1@1+ (1,0) [0|1] "" Vector__XXX
 SG_ APP_sw331_lPillarOccluded m331 : 16|1@1+ (1,0) [0|1] "" Vector__XXX
 SG_ APP_sw331_rPillarOccluded m331 : 17|1@1+ (1,0) [0|1] "" Vector__XXX
 SG_ APP_sw331_lRepeaterOccluded m331 : 18|1@1+ (1,0) [0|1] "" Vector__XXX
 SG_ APP_sw331_rRepeaterOccluded m331 : 19|1@1+ (1,0) [0|1] "" Vector__XXX
 SG_ APP_sw331_gpsDegraded m331 : 20|1@1+ (1,0) [0|1] "" Vector__XXX
 SG_ APP_sw331_poorWeather m331 : 21|1@1+ (1,0) [0|1] "" Vector__XXX
 SG_ APP_sw331_invalidMap m331 : 22|1@1+ (1,0) [0|1] "" Vector__XXX
 SG_ APP_sw331_adverseRoadConditions m331 : 23|1@1+ (1,0) [0|1] "" Vector__XXX
 SG_ APP_sw332_narrowWithFisheye m332 : 16|1@1+ (1,0) [0|1] "" Vector__XXX
 SG_ APP_sw332_pillars m332 : 17|1@1+ (1,0) [0|1] "" Vector__XXX
 SG_ APP_sw348_main m348 : 16|1@1+ (1,0) [0|1] "" Vector__XXX
 SG_ APP_sw348_narrow m348 : 17|1@1+ (1,0) [0|1] "" Vector__XXX
 SG_ APP_sw348_fisheye m348 : 18|1@1+ (1,0) [0|1] "" Vector__XXX
 SG_ APP_sw348_leftPillar m348 : 19|1@1+ (1,0) [0|1] "" Vector__XXX
 SG_ APP_sw348_rightPillar m348 : 20|1@1+ (1,0) [0|1] "" Vector__XXX
 SG_ APP_sw348_leftRepeater m348 : 21|1@1+ (1,0) [0|1] "" Vector__XXX
 SG_ APP_sw348_rightRepeater m348 : 22|1@1+ (1,0) [0|1] "" Vector__XXX
 SG_ APP_sw348_backup m348 : 23|1@1+ (1,0) [0|1] "" Vector__XXX
 SG_ APP_sw348_selfie m348 : 24|1@1+ (1,0) [0|1] "" Vector__XXX
 SG_ APP_sw348_fascia m348 : 25|1@1+ (1,0) [0|1] "" Vector__XXX
 SG_ APP_sw351_errorCode m351 : 16|32@1+ (1,0) [0|4294967295] "" Vector__XXX
 SG_ APP_sw352_errorCode m352 : 16|32@1+ (1,0) [0|4294967295] "" Vector__XXX
 SG_ APP_sw353_errorCode m353 : 16|32@1+ (1,0) [0|4294967295] "" Vector__XXX
 SG_ APP_sw355_quad1 m355 : 16|1@1+ (1,0) [0|1] "" Vector__XXX
 SG_ APP_sw355_quad2 m355 : 17|1@1+ (1,0) [0|1] "" Vector__XXX
 SG_ APP_sw355_quad3 m355 : 18|1@1+ (1,0) [0|1] "" Vector__XXX
 SG_ APP_sw355_quad1FailureRate m355 : 24|8@1+ (0.392156869173,0) [0|100.000001639] "percent" Vector__XXX
 SG_ APP_sw355_quad2FailureRate m355 : 32|8@1+ (0.392156869173,0) [0|100.000001639] "percent" Vector__XXX
 SG_ APP_sw355_quad3FailureRate m355 : 40|8@1+ (0.392156869173,0) [0|100.000001639] "percent" Vector__XXX
 SG_ APP_sw357_cabinCameraFailsafeAct m357 : 16|1@1+ (1,0) [0|1] "" Vector__XXX
 SG_ APP_sw357_cameraDisabled m357 : 17|1@1+ (1,0) [0|1] "" Vector__XXX
 SG_ APP_sw357_cameraNotStreaming m357 : 18|1@1+ (1,0) [0|1] "" Vector__XXX
 SG_ APP_sw357_disableByBuildCfg m357 : 19|1@1+ (1,0) [0|1] "" Vector__XXX
 SG_ APP_sw357_invalidCameraFailsafe m357 : 20|1@1+ (1,0) [0|1] "" Vector__XXX
 SG_ APP_sw357_invalidDrowsinessPredi m357 : 21|1@1+ (1,0) [0|1] "" Vector__XXX
 SG_ APP_sw357_invalidSccmSteeringAng m357 : 22|1@1+ (1,0) [0|1] "" Vector__XXX
 SG_ APP_sw357_invalidSccmSteeri_0001 m357 : 23|1@1+ (1,0) [0|1] "" Vector__XXX
 SG_ APP_sw357_noVisionOutput m357 : 24|1@1+ (1,0) [0|1] "" Vector__XXX
 SG_ APP_sw357_poorFrontCameraVisibil m357 : 25|1@1+ (1,0) [0|1] "" Vector__XXX
 SG_ APP_sw357_staleVisionDv m357 : 26|1@1+ (1,0) [0|1] "" Vector__XXX
 SG_ APP_sw357_staleVisionOutput m357 : 27|1@1+ (1,0) [0|1] "" Vector__XXX
 SG_ APP_sw357_sccmMia m357 : 28|1@1+ (1,0) [0|1] "" Vector__XXX
 SG_ APP_sw357_electricalFaultForSccm m357 : 29|1@1+ (1,0) [0|1] "" Vector__XXX
 SG_ APP_sw357_electricalFaultForMain m357 : 30|1@1+ (1,0) [0|1] "" Vector__XXX
 SG_ APP_sw357_electricalFaultForCabi m357 : 31|1@1+ (1,0) [0|1] "" Vector__XXX
 SG_ APP_sw357_mainCameraFailsafeActi m357 : 32|1@1+ (1,0) [0|1] "" Vector__XXX
 SG_ APP_sw357_electricalFaultForFish m357 : 33|1@1+ (1,0) [0|1] "" Vector__XXX
 SG_ APP_sw357_fisheyeCameraFailsafeA m357 : 34|1@1+ (1,0) [0|1] "" Vector__XXX
 SG_ APP_sw357_camCalibOutOfBounds m357 : 35|1@1+ (1,0) [0|1] "" Vector__XXX
 SG_ APP_sw358_noSpeedLimitSource m358 : 16|1@1+ (1,0) [0|1] "" Vector__XXX
 SG_ APP_sw358_mainCameraBlinded m358 : 17|1@1+ (1,0) [0|1] "" Vector__XXX
 SG_ APP_sw358_fisheyeCameraBlinded m358 : 18|1@1+ (1,0) [0|1] "" Vector__XXX
 SG_ APP_sw358_mainCameraStreamUnavai m358 : 19|1@1+ (1,0) [0|1] "" Vector__XXX
 SG_ APP_sw358_fisheyeCameraStreamUna m358 : 20|1@1+ (1,0) [0|1] "" Vector__XXX
 SG_ APP_sw358_camCalibOutOfBounds m358 : 21|1@1+ (1,0) [0|1] "" Vector__XXX
 SG_ APP_sw359_mainCameraBlinded m359 : 16|1@1+ (1,0) [0|1] "" Vector__XXX
 SG_ APP_sw359_narrowCameraBlinded m359 : 17|1@1+ (1,0) [0|1] "" Vector__XXX
 SG_ APP_sw359_fisheyeCameraBlinded m359 : 18|1@1+ (1,0) [0|1] "" Vector__XXX
 SG_ APP_sw362_fasciaCamDeserFault m362 : 16|3@1+ (1,0) [0|7] "" Vector__XXX
 SG_ APP_sw362_fasciaCamI2CbusFault m362 : 19|1@1+ (1,0) [0|1] "" Vector__XXX
 SG_ APP_sw362_fasciaCamSensorFault m362 : 20|3@1+ (1,0) [0|7] "" Vector__XXX
 SG_ APP_sw362_fasciaCamSerFault m362 : 24|3@1+ (1,0) [0|7] "" Vector__XXX
 SG_ APP_sw363_exitStatus m363 : 16|1@1+ (1,0) [0|1] "" Vector__XXX
 SG_ APP_sw363_bufferError m363 : 17|1@1+ (1,0) [0|1] "" Vector__XXX
 SG_ APP_sw363_frameGrabFailure m363 : 18|1@1+ (1,0) [0|1] "" Vector__XXX
 SG_ APP_sw363_gainControlFailure m363 : 19|1@1+ (1,0) [0|1] "" Vector__XXX
 SG_ APP_sw363_tempMonitorFailure m363 : 20|2@1+ (1,0) [0|3] "" Vector__XXX
 SG_ APP_sw363_firstFrameGrabFailure m363 : 22|1@1+ (1,0) [0|1] "" Vector__XXX
 SG_ APP_sw363_deserParityError m363 : 23|1@1+ (1,0) [0|1] "" Vector__XXX
 SG_ APP_sw363_deserLockError m363 : 24|1@1+ (1,0) [0|1] "" Vector__XXX
 SG_ APP_sw363_deserCrcError m363 : 25|1@1+ (1,0) [0|1] "" Vector__XXX
 SG_ APP_sw363_imagerHeartbeat m363 : 26|2@1+ (1,0) [0|2] "" Vector__XXX
 SG_ APP_sw363_serializerCrcErrCount m363 : 28|8@1+ (1,0) [0|254] "" Vector__XXX
 SG_ APP_sw363_deserLineLengthError m363 : 36|1@1+ (1,0) [0|1] "" Vector__XXX
 SG_ APP_sw363_numCaptureRecoveries m363 : 37|3@1+ (1,0) [0|7] "" Vector__XXX
 SG_ APP_sw363_currentTemperature m363 : 40|8@1+ (1,-60) [-60|194] "degC" Vector__XXX
 SG_ APP_sw363_minTemperature m363 : 48|8@1+ (1,-60) [-60|194] "degC" Vector__XXX
 SG_ APP_sw363_maxTemperature m363 : 56|8@1+ (1,-60) [-60|194] "degC" Vector__XXX
 SG_ APP_sw364_colorFilterMismatch m364 : 16|1@1+ (1,0) [0|1] "" Vector__XXX
 SG_ APP_sw364_detectedColorFilter m364 : 17|2@1+ (1,0) [0|3] "" Vector__XXX
 SG_ APP_sw364_expectedColorFilter m364 : 19|2@1+ (1,0) [0|3] "" Vector__XXX
 SG_ APP_sw364_cameraPositionMismatch m364 : 21|1@1+ (1,0) [0|1] "" Vector__XXX
 SG_ APP_sw364_blacklistedFuseID m364 : 22|1@1+ (1,0) [0|1] "" Vector__XXX
 SG_ APP_sw364_uuidMismatch m364 : 23|1@1+ (1,0) [0|1] "" Vector__XXX
 SG_ APP_sw364_detectedPosition m364 : 24|4@1+ (1,0) [0|15] "" Vector__XXX
 SG_ APP_sw365_fasciaCamExtNoCalFile m365 : 16|1@1+ (1,0) [0|1] "" Vector__XXX
 SG_ APP_sw366_clockFrequencyDrift m366 : 16|16@1- (0.0005,0) [-16.384|16.3835] "%" Vector__XXX
 SG_ APP_sw371_decryptionFailed m371 : 16|1@1+ (1,0) [0|1] "" Vector__XXX
 SG_ APP_sw389_frontCamResidue m389 : 16|1@1+ (1,0) [0|1] "" Vector__XXX
 SG_ APP_sw389_leftPillarCamResidue m389 : 17|1@1+ (1,0) [0|1] "" Vector__XXX
 SG_ APP_sw389_rightPillarCamResidue m389 : 18|1@1+ (1,0) [0|1] "" Vector__XXX
 SG_ APP_sw397_apImuNoise m397 : 16|1@1+ (1,0) [0|1] "" Vector__XXX
 SG_ APP_sw399_status m399 : 16|1@1+ (1,0) [0|1] "" Vector__XXX

BO_ 1045 APP_backupDashCamStatus: 1 APP
 SG_ APP_backupDashCamFeedGood : 0|1@1+ (1,0) [0|1] "" Vector__XXX
 SG_ APP_backupDashCamFrameRate : 1|7@1+ (1,0) [0|127] "" Vector__XXX

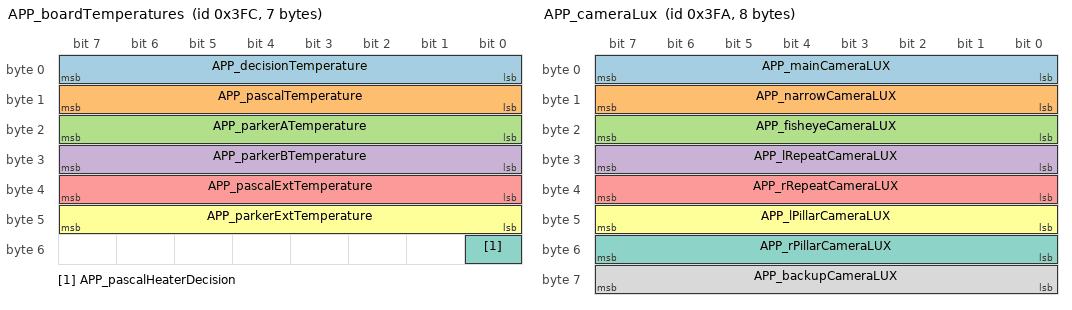
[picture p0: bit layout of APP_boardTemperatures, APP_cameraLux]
BO_ 1020 APP_boardTemperatures: 7 APP
 SG_ APP_decisionTemperature : 0|8@1+ (1,-128) [-128|127] "C" Vector__XXX
 SG_ APP_pascalTemperature : 8|8@1+ (1,-128) [-128|127] "C" Vector__XXX
 SG_ APP_parkerATemperature : 16|8@1+ (1,-128) [-128|127] "C" Vector__XXX
 SG_ APP_parkerBTemperature : 24|8@1+ (1,-128) [-128|127] "C" Vector__XXX
 SG_ APP_pascalExtTemperature : 32|8@1+ (1,-128) [-128|127] "C" Vector__XXX
 SG_ APP_parkerExtTemperature : 40|8@1+ (1,-128) [-128|127] "C" Vector__XXX
 SG_ APP_pascalHeaterDecision : 48|1@1+ (1,0) [0|1] "" Vector__XXX

BO_ 2046 APP_camCalibrationStatus: 6 APP
 SG_ APP_cameraPosition M : 0|4@1+ (1,0) [0|15] "" Vector__XXX
 SG_ APP_mainCamExtPitchCal m1 : 8|9@1+ (0.05,-12.5) [-12.5|12.5] "deg" Vector__XXX
 SG_ APP_mainCamExtYawCal m1 : 17|9@1+ (0.05,-12.5) [-12.5|12.5] "deg" Vector__XXX
 SG_ APP_mainCalibTime m1 : 26|7@1+ (1,0) [0|126] "min" Vector__XXX
 SG_ APP_mainCalibProgress m1 : 33|7@1+ (1,0) [0|100] "percent" Vector__XXX
 SG_ APP_mainCalibrated m1 : 40|1@1+ (1,0) [0|1] "" Vector__XXX
 SG_ APP_narrowCamExtPitchCal m2 : 8|9@1+ (0.05,-12.5) [-12.5|12.5] "deg" Vector__XXX
 SG_ APP_narrowCamExtYawCal m2 : 17|9@1+ (0.05,-12.5) [-12.5|12.5] "deg" Vector__XXX
 SG_ APP_narrowCalibTime m2 : 26|7@1+ (1,0) [0|126] "min" Vector__XXX
 SG_ APP_narrowCalibProgress m2 : 33|7@1+ (1,0) [0|100] "percent" Vector__XXX
 SG_ APP_narrowCalibrated m2 : 40|1@1+ (1,0) [0|1] "" Vector__XXX
 SG_ APP_fisheyeCamExtPitchCal m3 : 8|9@1+ (0.05,-12.5) [-12.5|12.5] "deg" Vector__XXX
 SG_ APP_fisheyeCamExtYawCal m3 : 17|9@1+ (0.05,-12.5) [-12.5|12.5] "deg" Vector__XXX
 SG_ APP_fisheyeCalibTime m3 : 26|7@1+ (1,0) [0|126] "min" Vector__XXX
 SG_ APP_fisheyeCalibProgress m3 : 33|7@1+ (1,0) [0|100] "percent" Vector__XXX
 SG_ APP_fisheyeCalibrated m3 : 40|1@1+ (1,0) [0|1] "" Vector__XXX
 SG_ APP_lPillarCamExtPitchCal m4 : 8|9@1+ (0.05,-12.5) [-12.5|12.5] "deg" Vector__XXX
 SG_ APP_lPillarCamExtYawCal m4 : 17|9@1+ (0.05,-12.5) [-12.5|12.5] "deg" Vector__XXX
 SG_ APP_lPillarCalibTime m4 : 26|7@1+ (1,0) [0|126] "min" Vector__XXX
 SG_ APP_lPillarCalibProgress m4 : 33|7@1+ (1,0) [0|100] "percent" Vector__XXX
 SG_ APP_lPillarCalibrated m4 : 40|1@1+ (1,0) [0|1] "" Vector__XXX
 SG_ APP_rPillarCamExtPitchCal m5 : 8|9@1+ (0.05,-12.5) [-12.5|12.5] "deg" Vector__XXX
 SG_ APP_rPillarCamExtYawCal m5 : 17|9@1+ (0.05,-12.5) [-12.5|12.5] "deg" Vector__XXX
 SG_ APP_rPillarCalibTime m5 : 26|7@1+ (1,0) [0|126] "min" Vector__XXX
 SG_ APP_rPillarCalibProgress m5 : 33|7@1+ (1,0) [0|100] "percent" Vector__XXX
 SG_ APP_rPillarCalibrated m5 : 40|1@1+ (1,0) [0|1] "" Vector__XXX
 SG_ APP_lRepeatCamExtPitchCal m6 : 8|9@1+ (0.05,-12.5) [-12.5|12.5] "deg" Vector__XXX
 SG_ APP_lRepeatCamExtYawCal m6 : 17|9@1+ (0.05,-12.5) [-12.5|12.5] "deg" Vector__XXX
 SG_ APP_lRepeatCalibTime m6 : 26|7@1+ (1,0) [0|126] "min" Vector__XXX
 SG_ APP_lRepeatCalibProgress m6 : 33|7@1+ (1,0) [0|100] "percent" Vector__XXX
 SG_ APP_lRepeatCalibrated m6 : 40|1@1+ (1,0) [0|1] "" Vector__XXX
 SG_ APP_rRepeatCamExtPitchCal m7 : 8|9@1+ (0.05,-12.5) [-12.5|12.5] "deg" Vector__XXX
 SG_ APP_rRepeatCamExtYawCal m7 : 17|9@1+ (0.05,-12.5) [-12.5|12.5] "deg" Vector__XXX
 SG_ APP_rRepeatCalibTime m7 : 26|7@1+ (1,0) [0|126] "min" Vector__XXX
 SG_ APP_rRepeatCalibProgress m7 : 33|7@1+ (1,0) [0|100] "percent" Vector__XXX
 SG_ APP_rRepeatCalibrated m7 : 40|1@1+ (1,0) [0|1] "" Vector__XXX
 SG_ APP_backupCamExtPitchCal m8 : 8|9@1+ (0.05,-12.5) [-12.5|12.5] "deg" Vector__XXX
 SG_ APP_backupCamExtYawCal m8 : 17|9@1+ (0.05,-12.5) [-12.5|12.5] "deg" Vector__XXX
 SG_ APP_backupCalibTime m8 : 26|7@1+ (1,0) [0|126] "min" Vector__XXX
 SG_ APP_backupCalibProgress m8 : 33|7@1+ (1,0) [0|100] "percent" Vector__XXX
 SG_ APP_backupCalibrated m8 : 40|1@1+ (1,0) [0|1] "" Vector__XXX

BO_ 1018 APP_cameraLux: 8 APP
 SG_ APP_mainCameraLUX : 0|8@1+ (0.5,0) [0|127] "lux^0.5" Vector__XXX
 SG_ APP_narrowCameraLUX : 8|8@1+ (0.5,0) [0|127] "lux^0.5" Vector__XXX
 SG_ APP_fisheyeCameraLUX : 16|8@1+ (0.5,0) [0|127] "lux^0.5" Vector__XXX
 SG_ APP_lRepeatCameraLUX : 24|8@1+ (0.5,0) [0|127] "lux^0.5" Vector__XXX
 SG_ APP_rRepeatCameraLUX : 32|8@1+ (0.5,0) [0|127] "lux^0.5" Vector__XXX
 SG_ APP_lPillarCameraLUX : 40|8@1+ (0.5,0) [0|127] "lux^0.5" Vector__XXX
 SG_ APP_rPillarCameraLUX : 48|8@1+ (0.5,0) [0|127] "lux^0.5" Vector__XXX
 SG_ APP_backupCameraLUX : 56|8@1+ (0.5,0) [0|127] "lux^0.5" Vector__XXX

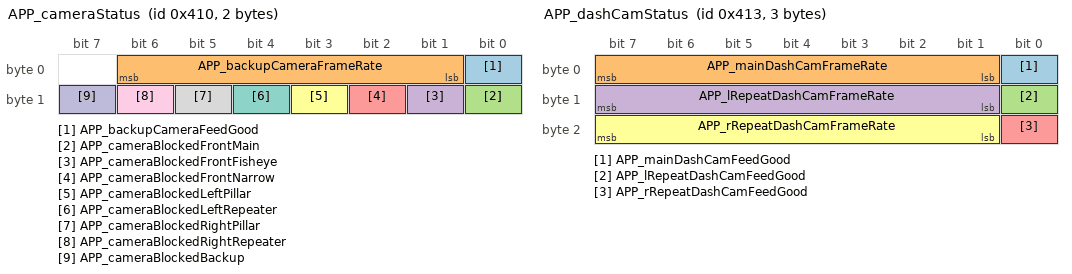
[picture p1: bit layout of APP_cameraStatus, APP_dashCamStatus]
BO_ 1040 APP_cameraStatus: 2 APP
 SG_ APP_backupCameraFeedGood : 0|1@1+ (1,0) [0|1] "" Vector__XXX
 SG_ APP_backupCameraFrameRate : 1|6@1+ (1,0) [0|63] "" Vector__XXX
 SG_ APP_cameraBlockedFrontMain : 8|1@1+ (1,0) [0|1] "" Vector__XXX
 SG_ APP_cameraBlockedFrontFisheye : 9|1@1+ (1,0) [0|1] "" Vector__XXX
 SG_ APP_cameraBlockedFrontNarrow : 10|1@1+ (1,0) [0|1] "" Vector__XXX
 SG_ APP_cameraBlockedLeftPillar : 11|1@1+ (1,0) [0|1] "" Vector__XXX
 SG_ APP_cameraBlockedLeftRepeater : 12|1@1+ (1,0) [0|1] "" Vector__XXX
 SG_ APP_cameraBlockedRightPillar : 13|1@1+ (1,0) [0|1] "" Vector__XXX
 SG_ APP_cameraBlockedRightRepeater : 14|1@1+ (1,0) [0|1] "" Vector__XXX
 SG_ APP_cameraBlockedBackup : 15|1@1+ (1,0) [0|1] "" Vector__XXX

BO_ 1177 APP_cameraTemperatures: 8 APP
 SG_ APP_rRepeaterCameraTemperature : 24|8@1+ (1,-60) [-60|195] "C" Vector__XXX
 SG_ APP_lRepeaterCameraTemperature : 32|8@1+ (1,-60) [-60|195] "C" Vector__XXX

BO_ 1043 APP_dashCamStatus: 3 APP
 SG_ APP_mainDashCamFeedGood : 0|1@1+ (1,0) [0|1] "" Vector__XXX
 SG_ APP_mainDashCamFrameRate : 1|7@1+ (1,0) [0|127] "" Vector__XXX
 SG_ APP_lRepeatDashCamFeedGood : 8|1@1+ (1,0) [0|1] "" Vector__XXX
 SG_ APP_lRepeatDashCamFrameRate : 9|7@1+ (1,0) [0|127] "" Vector__XXX
 SG_ APP_rRepeatDashCamFeedGood : 16|1@1+ (1,0) [0|1] "" Vector__XXX
 SG_ APP_rRepeatDashCamFrameRate : 17|7@1+ (1,0) [0|127] "" Vector__XXX

BO_ 603 APP_environment: 1 APP
 SG_ APP_environmentRainy : 0|1@1+ (1,0) [0|1] "" Vector__XXX
 SG_ APP_environmentSnowy : 1|1@1+ (1,0) [0|1] "" Vector__XXX

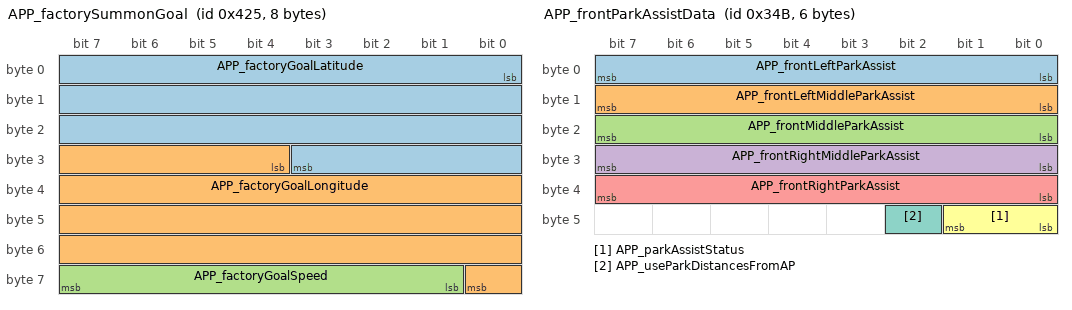
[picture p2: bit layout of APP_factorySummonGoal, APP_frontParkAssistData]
BO_ 1061 APP_factorySummonGoal: 8 APP
 SG_ APP_factoryGoalLatitude : 0|28@1- (1.0e-06,0) [-134.217728|134.217727] "deg" Vector__XXX
 SG_ APP_factoryGoalLongitude : 28|29@1- (1.0e-06,0) [-268.435456|268.435454] "deg" Vector__XXX
 SG_ APP_factoryGoalSpeed : 57|7@1+ (1,0) [0|100] "mph" Vector__XXX

BO_ 843 APP_frontParkAssistData: 6 APP
 SG_ APP_frontLeftParkAssist : 0|8@1+ (1,0) [0|254] "cm" Vector__XXX
 SG_ APP_frontLeftMiddleParkAssist : 8|8@1+ (1,0) [0|254] "cm" Vector__XXX
 SG_ APP_frontMiddleParkAssist : 16|8@1+ (1,0) [0|254] "cm" Vector__XXX
 SG_ APP_frontRightMiddleParkAssist : 24|8@1+ (1,0) [0|254] "cm" Vector__XXX
 SG_ APP_frontRightParkAssist : 32|8@1+ (1,0) [0|254] "cm" Vector__XXX
 SG_ APP_parkAssistStatus : 40|2@1+ (1,0) [0|2] "" Vector__XXX
 SG_ APP_useParkDistancesFromAP : 42|1@1+ (1,0) [0|1] "" Vector__XXX

BO_ 1353 APP_info: 8 APP
 SG_ APP_infoIndex M : 0|8@1+ (1,0) [0|255] "" Vector__XXX
 SG_ APP_buildType m0 : 8|8@1+ (1,0) [0|255] "" Vector__XXX

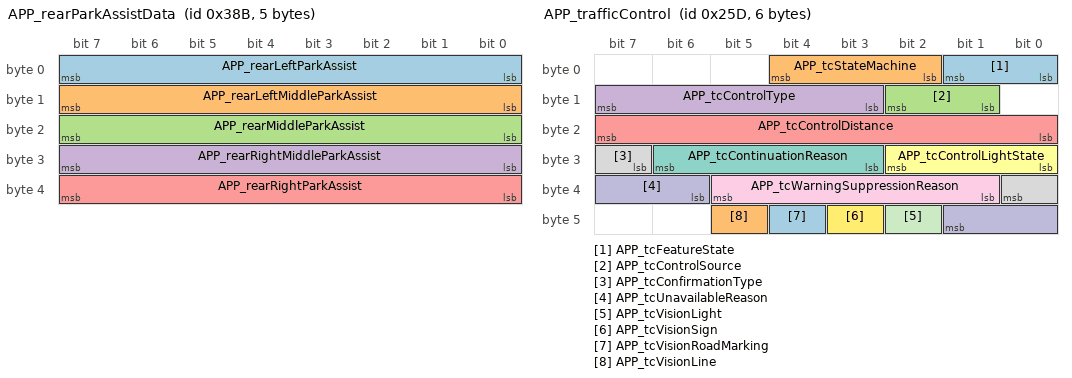
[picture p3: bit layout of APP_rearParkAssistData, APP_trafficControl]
BO_ 907 APP_rearParkAssistData: 5 APP
 SG_ APP_rearLeftParkAssist : 0|8@1+ (1,0) [0|254] "cm" Vector__XXX
 SG_ APP_rearLeftMiddleParkAssist : 8|8@1+ (1,0) [0|254] "cm" Vector__XXX
 SG_ APP_rearMiddleParkAssist : 16|8@1+ (1,0) [0|254] "cm" Vector__XXX
 SG_ APP_rearRightMiddleParkAssist : 24|8@1+ (1,0) [0|254] "cm" Vector__XXX
 SG_ APP_rearRightParkAssist : 32|8@1+ (1,0) [0|254] "cm" Vector__XXX

BO_ 601 APP_status: 8 APP
 SG_ APP_watchdogState : 0|3@1+ (1,0) [0|6] "" Vector__XXX
 SG_ APP_fusedState : 3|2@1+ (1,0) [0|2] "" Vector__XXX
 SG_ APP_cameraHeaterRequest : 5|1@1+ (1,0) [0|1] "" Vector__XXX
 SG_ APP_factorySummonStatus : 6|4@1+ (1,0) [1|15] "" Vector__XXX
 SG_ APP_clipRecordingStatus : 10|3@1+ (1,0) [0|7] "" Vector__XXX
 SG_ APP_allowApActivationWithBrake : 13|1@1+ (1,0) [0|1] "" Vector__XXX
 SG_ APP_summonUnavailableReason : 14|5@1+ (1,0) [0|31] "" Vector__XXX
 SG_ APP_fsdSuspendState : 19|2@1+ (1,0) [0|2] "" Vector__XXX
 SG_ APP_fsdRevokeStrikeoutCount : 21|3@1+ (1,0) [0|6] "" Vector__XXX
 SG_ APP_teslaVisionSupported : 24|2@1+ (1,0) [0|2] "" Vector__XXX
 SG_ APP_teslaVisionUnsupportedReason : 26|3@1+ (1,0) [0|7] "" Vector__XXX
 SG_ APP_fsdRevokeCount : 29|3@1+ (1,0) [0|6] "" Vector__XXX
 SG_ APP_excessiveAccelPedalWarning : 32|1@1+ (1,0) [0|1] "" Vector__XXX
 SG_ APP_unifiedObjectStackSupported : 33|2@1+ (1,0) [0|2] "" Vector__XXX
 SG_ APP_unifiedObjsUnsupportedReason : 35|3@1+ (1,0) [0|7] "" Vector__XXX
 SG_ APP_DDAWSystemStatus : 38|3@1+ (1,0) [0|7] "" Vector__XXX
 SG_ APP_socOperatingMode : 41|2@1+ (1,0) [0|3] "" Vector__XXX
 SG_ APP_summonVersionIdentifier : 43|1@1+ (1,0) [0|1] "" Vector__XXX
 SG_ APP_sentryState : 44|3@1+ (1,0) [0|7] "" Vector__XXX
 SG_ APP_autoparkVersionIdentifier : 47|2@1+ (1,0) [0|3] "" Vector__XXX
 SG_ APP_setSpeedMode : 49|2@1+ (1,0) [0|3] "" Vector__XXX
 SG_ APP_suspendResumeAvailable : 51|1@1+ (1,0) [0|1] "" Vector__XXX
 SG_ APP_statusCounter : 52|4@1+ (1,0) [0|15] "" Vector__XXX
 SG_ APP_statusChecksum : 56|8@1+ (1,0) [0|255] "" Vector__XXX

BO_ 605 APP_trafficControl: 6 APP
 SG_ APP_tcFeatureState : 0|2@1+ (1,0) [0|3] "" Vector__XXX
 SG_ APP_tcStateMachine : 2|3@1+ (1,0) [0|7] "" Vector__XXX
 SG_ APP_tcControlSource : 9|2@1+ (1,0) [0|3] "" Vector__XXX
 SG_ APP_tcControlType : 11|5@1+ (1,0) [0|31] "" Vector__XXX
 SG_ APP_tcControlDistance : 16|8@1+ (1,0) [0|254] "m" Vector__XXX
 SG_ APP_tcControlLightState : 24|3@1+ (1,0) [0|7] "" Vector__XXX
 SG_ APP_tcContinuationReason : 27|4@1+ (1,0) [0|15] "" Vector__XXX
 SG_ APP_tcConfirmationType : 31|2@1+ (1,0) [0|3] "" Vector__XXX
 SG_ APP_tcWarningSuppressionReason : 33|5@1+ (1,0) [0|31] "" Vector__XXX
 SG_ APP_tcUnavailableReason : 38|4@1+ (1,0) [0|15] "" Vector__XXX
 SG_ APP_tcVisionLight : 42|1@1+ (1,0) [0|1] "" Vector__XXX
 SG_ APP_tcVisionSign : 43|1@1+ (1,0) [0|1] "" Vector__XXX
 SG_ APP_tcVisionRoadMarking : 44|1@1+ (1,0) [0|1] "" Vector__XXX
 SG_ APP_tcVisionLine : 45|1@1+ (1,0) [0|1] "" Vector__XXX

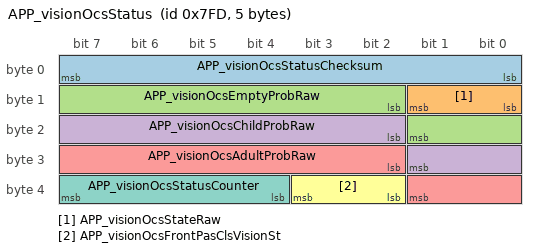
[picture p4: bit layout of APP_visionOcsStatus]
BO_ 2045 APP_visionOcsStatus: 5 APP
 SG_ APP_visionOcsStatusChecksum : 0|8@1+ (1,0) [0|255] "" Vector__XXX
 SG_ APP_visionOcsStateRaw : 8|2@1+ (1,0) [0|3] "" Vector__XXX
 SG_ APP_visionOcsEmptyProbRaw : 10|8@1+ (0.004,0) [0|1.016] "points" Vector__XXX
 SG_ APP_visionOcsChildProbRaw : 18|8@1+ (0.004,0) [0|1.016] "points" Vector__XXX
 SG_ APP_visionOcsAdultProbRaw : 26|8@1+ (0.004,0) [0|1.016] "points" Vector__XXX
 SG_ APP_visionOcsFrontPasClsVisionSt : 34|2@1+ (1,0) [0|3] "" Vector__XXX
 SG_ APP_visionOcsStatusCounter : 36|4@1+ (1,0) [0|15] "" Vector__XXX

BO_ 809 APP_warningMatrix0: 8 APP
 SG_ APP_w001_DEPRECATED : 0|1@1+ (1,0) [0|1] "" Vector__XXX
 SG_ APP_w002_ldwDisabled : 1|1@1+ (1,0) [0|1] "" Vector__XXX
 SG_ APP_w003_isaDisabled : 2|1@1+ (1,0) [0|1] "" Vector__XXX
 SG_ APP_w004_accDisabled : 3|1@1+ (1,0) [0|1] "" Vector__XXX
 SG_ APP_w005_fcwCancelled : 4|1@1+ (1,0) [0|1] "" Vector__XXX
 SG_ APP_w006_aebCancelled : 5|1@1+ (1,0) [0|1] "" Vector__XXX
 SG_ APP_w007_ahlbDisabled : 6|1@1+ (1,0) [0|1] "" Vector__XXX
 SG_ APP_w008_parkDisabled : 7|1@1+ (1,0) [0|1] "" Vector__XXX
 SG_ APP_w009_aebFault : 8|1@1+ (1,0) [0|1] "" Vector__XXX
 SG_ APP_w010_radcCalibIssue : 9|1@1+ (1,0) [0|1] "" Vector__XXX
 SG_ APP_w011_scaEvent : 10|1@1+ (1,0) [0|1] "" Vector__XXX
 SG_ APP_w012_Cam_BootFailure : 11|1@1+ (1,0) [0|1] "" Vector__XXX
 SG_ APP_w013_Cam_Watchdog : 12|1@1+ (1,0) [0|1] "" Vector__XXX
 SG_ APP_w014_swAssert : 13|1@1+ (1,0) [0|1] "" Vector__XXX
 SG_ APP_w015_Camera_Failsafes : 14|1@1+ (1,0) [0|1] "" Vector__XXX
 SG_ APP_w016_aeb_e_event : 15|1@1+ (1,0) [0|1] "" Vector__XXX
 SG_ APP_w017_Cam_Msg_MIA : 16|1@1+ (1,0) [0|1] "" Vector__XXX
 SG_ APP_w018_ECU_Power_Issue : 17|1@1+ (1,0) [0|1] "" Vector__XXX
 SG_ APP_w019_ECU_Stack_Overflow : 18|1@1+ (1,0) [0|1] "" Vector__XXX
 SG_ APP_w020_ECU_checkstopError : 19|1@1+ (1,0) [0|1] "" Vector__XXX
 SG_ APP_w021_ECU_Temperature_Issue : 20|1@1+ (1,0) [0|1] "" Vector__XXX
 SG_ APP_w022_ECU_EEPROM_Failure : 21|1@1+ (1,0) [0|1] "" Vector__XXX
 SG_ APP_w023_ECU_Cam_Statemismatc : 22|1@1+ (1,0) [0|1] "" Vector__XXX
 SG_ APP_w024_ECU_Watchdog_Reset : 23|1@1+ (1,0) [0|1] "" Vector__XXX
 SG_ APP_w025_LC_Steering_Override : 24|1@1+ (1,0) [0|1] "" Vector__XXX
 SG_ APP_w026_ECU_timingIssue : 25|1@1+ (1,0) [0|1] "" Vector__XXX
 SG_ APP_w027_ECU_Reset_Fault : 26|1@1+ (1,0) [0|1] "" Vector__XXX
 SG_ APP_w028_spi_rx_error : 27|1@1+ (1,0) [0|1] "" Vector__XXX
 SG_ APP_w029_spi_tx_error : 28|1@1+ (1,0) [0|1] "" Vector__XXX
 SG_ APP_w030_Heater_Issue : 29|1@1+ (1,0) [0|1] "" Vector__XXX
 SG_ APP_w031_canRxError : 30|1@1+ (1,0) [0|1] "" Vector__XXX
 SG_ APP_w032_canTxError : 31|1@1+ (1,0) [0|1] "" Vector__XXX
 SG_ APP_w033_gtwMia : 32|1@1+ (1,0) [0|1] "" Vector__XXX
 SG_ APP_w034_sccmMia : 33|1@1+ (1,0) [0|1] "" Vector__XXX
 SG_ APP_w035_espMia : 34|1@1+ (1,0) [0|1] "" Vector__XXX
 SG_ APP_w036_bdyMia : 35|1@1+ (1,0) [0|1] "" Vector__XXX
 SG_ APP_w037_camTacIssue : 36|1@1+ (1,0) [0|1] "" Vector__XXX
 SG_ APP_w038_camFailure : 37|1@1+ (1,0) [0|1] "" Vector__XXX
 SG_ APP_w039_sdm_rcm_Mia : 38|1@1+ (1,0) [0|1] "" Vector__XXX
 SG_ APP_w040_autopilotAngleSaturated : 39|1@1+ (1,0) [0|1] "" Vector__XXX
 SG_ APP_w041_autopilotRateSaturated : 40|1@1+ (1,0) [0|1] "" Vector__XXX
 SG_ APP_w042_autopilotAborting : 41|1@1+ (1,0) [0|1] "" Vector__XXX
 SG_ APP_w043_camLongRunTime : 42|1@1+ (1,0) [0|1] "" Vector__XXX
 SG_ APP_w044_appMobileyeFailure : 43|1@1+ (1,0) [0|1] "" Vector__XXX
 SG_ APP_w045_radMia : 44|1@1+ (1,0) [0|1] "" Vector__XXX
 SG_ APP_w046_eepromRecordAbsent : 45|1@1+ (1,0) [0|1] "" Vector__XXX
 SG_ APP_w047_edrEvent : 46|1@1+ (1,0) [0|1] "" Vector__XXX
 SG_ APP_w048_APP_Features_Disabled : 47|1@1+ (1,0) [0|1] "" Vector__XXX
 SG_ APP_w049_eyeqVersionMismatch : 48|1@1+ (1,0) [0|1] "" Vector__XXX
 SG_ APP_w050_aeb_event : 49|1@1+ (1,0) [0|1] "" Vector__XXX
 SG_ APP_w051_radcEcuIssue : 50|1@1+ (1,0) [0|1] "" Vector__XXX
 SG_ APP_w052_radcSensorIssue : 51|1@1+ (1,0) [0|1] "" Vector__XXX
 SG_ APP_w053_radcCommIssue : 52|1@1+ (1,0) [0|1] "" Vector__XXX
 SG_ APP_w054_camAutofix : 53|1@1+ (1,0) [0|1] "" Vector__XXX
 SG_ APP_w055_radcVersionMismatch : 54|1@1+ (1,0) [0|1] "" Vector__XXX
 SG_ APP_w056_diMia : 55|1@1+ (1,0) [0|1] "" Vector__XXX
 SG_ APP_w057_mcuMia : 56|1@1+ (1,0) [0|1] "" Vector__XXX
 SG_ APP_w058_epbMia : 57|1@1+ (1,0) [0|1] "" Vector__XXX
 SG_ APP_w059_parkMia : 58|1@1+ (1,0) [0|1] "" Vector__XXX
 SG_ APP_w060_fcw_event : 59|1@1+ (1,0) [0|1] "" Vector__XXX
 SG_ APP_w061_airSuspensionMia : 60|1@1+ (1,0) [0|1] "" Vector__XXX
 SG_ APP_w062_radcAlignment : 61|1@1+ (1,0) [0|1] "" Vector__XXX
 SG_ APP_w063_parkVersionMismatch : 62|1@1+ (1,0) [0|1] "" Vector__XXX
 SG_ APP_w064_epasMia : 63|1@1+ (1,0) [0|1] "" Vector__XXX

BO_TX_BU_ 1045 : APP;
BO_TX_BU_ 1020 : APP;
BO_TX_BU_ 2046 : APP;
BO_TX_BU_ 1018 : APP;
BO_TX_BU_ 1040 : APP;
BO_TX_BU_ 1177 : APP;
BO_TX_BU_ 1043 : APP;
BO_TX_BU_ 603 : APP;
BO_TX_BU_ 1061 : APP;
BO_TX_BU_ 843 : APP;
BO_TX_BU_ 1353 : APP;
BO_TX_BU_ 907 : APP;
BO_TX_BU_ 601 : APP;
BO_TX_BU_ 605 : APP;
BO_TX_BU_ 2045 : APP;
BO_TX_BU_ 809 : APP;
CM_ SG_ 1513 APP_sw188_minTemperature "Driver assistance computer (primary): sw188 min temperature; raw 255 = signal not available (SNA)";
CM_ SG_ 1513 APP_sw188_maxTemperature "Driver assistance computer (primary): sw188 max temperature; raw 255 = signal not available (SNA)";
CM_ SG_ 1513 APP_sw189_exitStatus "Driver assistance computer (primary): sw189 exit status";
CM_ SG_ 1513 APP_sw189_bufferError "Driver assistance computer (primary): sw189 buffer error";
CM_ SG_ 1513 APP_sw189_frameGrabFailure "Driver assistance computer (primary): sw189 frame grab failure";
CM_ SG_ 1513 APP_sw189_gainControlFailure "Driver assistance computer (primary): sw189 gain control failure";
CM_ SG_ 1513 APP_sw189_tempMonitorFailure "Driver assistance computer (primary): sw189 temp monitor failure";
CM_ SG_ 1513 APP_sw189_firstFrameGrabFailure "Driver assistance computer (primary): sw189 first frame grab failure";
CM_ SG_ 1513 APP_sw189_deserParityError "Driver assistance computer (primary): sw189 deser parity error";
CM_ SG_ 1513 APP_sw189_deserLockError "Driver assistance computer (primary): sw189 deser lock error";
CM_ SG_ 1513 APP_sw189_deserCrcError "Driver assistance computer (primary): sw189 deser crc error";
CM_ SG_ 1513 APP_sw189_imagerHeartbeat "Driver assistance computer (primary): sw189 imager heartbeat; raw 3 = signal not available (SNA)";
CM_ SG_ 1513 APP_sw189_serializerCrcErrCount "Driver assistance computer (primary): sw189 serializer crc err count; raw 255 = signal not available (SNA)";
CM_ SG_ 1513 APP_sw189_deserLineLengthError "Driver assistance computer (primary): sw189 deser line length error";
CM_ SG_ 1513 APP_sw189_numCaptureRecoveries "Driver assistance computer (primary): sw189 num capture recoveries";
CM_ SG_ 1513 APP_sw189_currentTemperature "Driver assistance computer (primary): sw189 current temperature; raw 255 = signal not available (SNA)";
CM_ SG_ 1513 APP_sw189_minTemperature "Driver assistance computer (primary): sw189 min temperature; raw 255 = signal not available (SNA)";
CM_ SG_ 1513 APP_sw189_maxTemperature "Driver assistance computer (primary): sw189 max temperature; raw 255 = signal not available (SNA)";
CM_ SG_ 1513 APP_sw190_exitStatus "Driver assistance computer (primary): sw190 exit status";
CM_ SG_ 1513 APP_sw190_bufferError "Driver assistance computer (primary): sw190 buffer error";
CM_ SG_ 1513 APP_sw190_frameGrabFailure "Driver assistance computer (primary): sw190 frame grab failure";
CM_ SG_ 1513 APP_sw190_gainControlFailure "Driver assistance computer (primary): sw190 gain control failure";
CM_ SG_ 1513 APP_sw190_tempMonitorFailure "Driver assistance computer (primary): sw190 temp monitor failure";
CM_ SG_ 1513 APP_sw190_firstFrameGrabFailure "Driver assistance computer (primary): sw190 first frame grab failure";
CM_ SG_ 1513 APP_sw190_deserParityError "Driver assistance computer (primary): sw190 deser parity error";
CM_ SG_ 1513 APP_sw190_deserLockError "Driver assistance computer (primary): sw190 deser lock error";
CM_ SG_ 1513 APP_sw190_deserCrcError "Driver assistance computer (primary): sw190 deser crc error";
CM_ SG_ 1513 APP_sw190_imagerHeartbeat "Driver assistance computer (primary): sw190 imager heartbeat; raw 3 = signal not available (SNA)";
CM_ SG_ 1513 APP_sw190_serializerCrcErrCount "Driver assistance computer (primary): sw190 serializer crc err count; raw 255 = signal not available (SNA)";
CM_ SG_ 1513 APP_sw190_deserLineLengthError "Driver assistance computer (primary): sw190 deser line length error";
CM_ SG_ 1513 APP_sw190_numCaptureRecoveries "Driver assistance computer (primary): sw190 num capture recoveries";
CM_ SG_ 1513 APP_sw190_currentTemperature "Driver assistance computer (primary): sw190 current temperature; raw 255 = signal not available (SNA)";
CM_ SG_ 1513 APP_sw190_minTemperature "Driver assistance computer (primary): sw190 min temperature; raw 255 = signal not available (SNA)";
CM_ SG_ 1513 APP_sw190_maxTemperature "Driver assistance computer (primary): sw190 max temperature; raw 255 = signal not available (SNA)";
CM_ SG_ 1513 APP_sw191_abortReason "Driver assistance computer (primary): sw191 abort reason";
CM_ SG_ 1513 APP_sw191_handsOnState "Driver assistance computer (primary): sw191 hands on state; raw 15 = signal not available (SNA)";
CM_ SG_ 1513 APP_sw191_cruiseState "Driver assistance computer (primary): sw191 cruise state";
CM_ SG_ 1513 APP_sw191_epasErrorCode "Driver assistance computer (primary): sw191 epas error code; raw 15 = signal not available (SNA)";
CM_ SG_ 1513 APP_sw191_viewRange "Driver assistance computer (primary): sw191 view range";
CM_ SG_ 1513 APP_sw191_roadClass "Driver assistance computer (primary): sw191 road class; raw 0 = signal not available (SNA)";
CM_ SG_ 1513 APP_sw191_referenceHealth "Driver assistance computer (primary): sw191 reference health";
CM_ SG_ 1513 APP_sw191_solverHealth "Driver assistance computer (primary): sw191 solver health";
CM_ SG_ 1513 APP_sw191_roadEstHealth "Driver assistance computer (primary): sw191 road est health";
CM_ SG_ 1513 APP_sw191_roadEstMode "Driver assistance computer (primary): sw191 road est mode";
CM_ SG_ 1513 APP_sw191_radarFault "Driver assistance computer (primary): sw191 radar fault";
CM_ SG_ 1513 APP_sw191_radarBlind "Driver assistance computer (primary): sw191 radar blind";
CM_ SG_ 1513 APP_sw191_cameraFailsafes "Driver assistance computer (primary): sw191 camera failsafes";
CM_ SG_ 1513 APP_sw192_speakerFailureType "Driver assistance computer (primary): sw192 speaker failure type";
CM_ SG_ 1513 APP_sw192_chassisType "Driver assistance computer (primary): sw192 chassis type";
CM_ SG_ 1513 APP_sw192_hardwareType "Driver assistance computer (primary): sw192 hardware type";
CM_ SG_ 1513 APP_sw194_leadAx "Driver assistance computer (primary): sw194 lead ax";
CM_ SG_ 1513 APP_sw194_leadDx "Driver assistance computer (primary): sw194 lead dx";
CM_ SG_ 1513 APP_sw194_leadVx "Driver assistance computer (primary): sw194 lead vx";
CM_ SG_ 1513 APP_sw194_numObstacles "Driver assistance computer (primary): sw194 num obstacles";
CM_ SG_ 1513 APP_sw194_numPedstrian "Driver assistance computer (primary): sw194 num pedstrian";
CM_ SG_ 1513 APP_sw194_reasonForHold "Driver assistance computer (primary): sw194 reason for hold; raw 15 = signal not available (SNA)";
CM_ SG_ 1513 APP_sw194_timeInHold "Driver assistance computer (primary): sw194 time in hold";
CM_ SG_ 1513 APP_sw195_s1Blocked "Driver assistance computer (primary): sw195 s1 blocked";
CM_ SG_ 1513 APP_sw195_s6Blocked "Driver assistance computer (primary): sw195 s6 blocked";
CM_ SG_ 1513 APP_sw195_s7Blocked "Driver assistance computer (primary): sw195 s7 blocked";
CM_ SG_ 1513 APP_sw195_s8Blocked "Driver assistance computer (primary): sw195 s8 blocked";
CM_ SG_ 1513 APP_sw195_s11Blocked "Driver assistance computer (primary): sw195 s11 blocked";
CM_ SG_ 1513 APP_sw195_s12Blocked "Driver assistance computer (primary): sw195 s12 blocked";
CM_ SG_ 1513 APP_sw195_sdiFrontCC "Driver assistance computer (primary): sw195 sdi front CC";
CM_ SG_ 1513 APP_sw195_sdiRearCC "Driver assistance computer (primary): sw195 sdi rear CC";
CM_ SG_ 1513 APP_sw195_sdiSystemNoise "Driver assistance computer (primary): sw195 sdi system noise";
CM_ SG_ 1513 APP_sw195_sdiSystemStatus "Driver assistance computer (primary): sw195 sdi system status";
CM_ SG_ 1513 APP_sw195_vehicleSpeed "Driver assistance computer (primary): sw195 vehicle speed";
CM_ SG_ 1513 APP_sw199_abortCodeDas "Driver assistance computer (primary): sw199 abort code das";
CM_ SG_ 1513 APP_sw199_abortCodePARK "Driver assistance computer (primary): sw199 abort code PARK; raw 31 = signal not available (SNA)";
CM_ SG_ 1513 APP_sw199_currentSTW "Driver assistance computer (primary): sw199 current STW";
CM_ SG_ 1513 APP_sw199_currentSpeed "Driver assistance computer (primary): sw199 current speed";
CM_ SG_ 1513 APP_sw199_internalState "Driver assistance computer (primary): sw199 internal state";
CM_ SG_ 1513 APP_sw199_maxSpeed "Driver assistance computer (primary): sw199 max speed";
CM_ SG_ 1513 APP_sw199_numShifts "Driver assistance computer (primary): sw199 num shifts";
CM_ SG_ 1513 APP_sw203_controlType "Driver assistance computer (primary): sw203 control type; raw 15 = signal not available (SNA)";
CM_ SG_ 1513 APP_sw203_curbType "Driver assistance computer (primary): sw203 curb type";
CM_ SG_ 1513 APP_sw203_roadClass "Driver assistance computer (primary): sw203 road class";
CM_ SG_ 1513 APP_sw203_slotSizeX "Driver assistance computer (primary): sw203 slot size x";
CM_ SG_ 1513 APP_sw203_slotSizeY "Driver assistance computer (primary): sw203 slot size y";
CM_ SG_ 1513 APP_sw203_startDistance "Driver assistance computer (primary): sw203 start distance";
CM_ SG_ 1513 APP_sw203_vehicleSkew "Driver assistance computer (primary): sw203 vehicle skew";
CM_ SG_ 1513 APP_sw204_frLeft "Driver assistance computer (primary): sw204 fr left";
CM_ SG_ 1513 APP_sw204_frLeftMiddle "Driver assistance computer (primary): sw204 fr left middle";
CM_ SG_ 1513 APP_sw204_frMiddle "Driver assistance computer (primary): sw204 fr middle";
CM_ SG_ 1513 APP_sw204_frRight "Driver assistance computer (primary): sw204 fr right";
CM_ SG_ 1513 APP_sw204_frRightMiddle "Driver assistance computer (primary): sw204 fr right middle";
CM_ SG_ 1513 APP_sw204_maxSpeed "Driver assistance computer (primary): sw204 max speed";
CM_ SG_ 1513 APP_sw205_oocDistance "Driver assistance computer (primary): sw205 ooc distance";
CM_ SG_ 1513 APP_sw205_rrLeft "Driver assistance computer (primary): sw205 rr left";
CM_ SG_ 1513 APP_sw205_rrLeftMiddle "Driver assistance computer (primary): sw205 rr left middle";
CM_ SG_ 1513 APP_sw205_rrMiddle "Driver assistance computer (primary): sw205 rr middle";
CM_ SG_ 1513 APP_sw205_rrRight "Driver assistance computer (primary): sw205 rr right";
CM_ SG_ 1513 APP_sw205_rrRightMiddle "Driver assistance computer (primary): sw205 rr right middle";
CM_ SG_ 1513 APP_sw207_appMobileyeStatus "Driver assistance computer (primary): sw207 app mobileye status";
CM_ SG_ 1513 APP_sw207_eyeq3MainState "Driver assistance computer (primary): sw207 eyeq3 main state";
CM_ SG_ 1513 APP_sw207_lcUnavailableReason "Driver assistance computer (primary): sw207 lc unavailable reason";
CM_ SG_ 1513 APP_sw213_autopilotIntState "Driver assistance computer (primary): sw213 autopilot int state";
CM_ SG_ 1513 APP_sw213_autopilotRestricted "Driver assistance computer (primary): sw213 autopilot restricted";
CM_ SG_ 1513 APP_sw213_endSpeed "Driver assistance computer (primary): sw213 end speed";
CM_ SG_ 1513 APP_sw213_epasHandsOnDetected "Driver assistance computer (primary): sw213 epas hands on detected";
CM_ SG_ 1513 APP_sw213_startSpeed "Driver assistance computer (primary): sw213 start speed";
CM_ SG_ 1513 APP_sw213_apIntStateAtTrigger "Driver assistance computer (primary): sw213 ap int state at trigger";
CM_ SG_ 1513 APP_sw213_takeoverDuration "Driver assistance computer (primary): sw213 takeover duration";
CM_ SG_ 1513 APP_sw218_cipvDist "Driver assistance computer (primary): sw218 cipv dist";
CM_ SG_ 1513 APP_sw218_drivingOnHighway "Driver assistance computer (primary): sw218 driving on highway";
CM_ SG_ 1513 APP_sw218_handsOnState "Driver assistance computer (primary): sw218 hands on state";
CM_ SG_ 1513 APP_sw218_mcuAutosteerRestricted "Driver assistance computer (primary): sw218 mcu autosteer restricted";
CM_ SG_ 1513 APP_sw218_pedalPosition "Driver assistance computer (primary): sw218 pedal position";
CM_ SG_ 1513 APP_sw219_controlledAccess "Driver assistance computer (primary): sw219 controlled access";
CM_ SG_ 1513 APP_sw219_roadClass "Driver assistance computer (primary): sw219 road class";
CM_ SG_ 1513 APP_sw219_vehicleSpeed "Driver assistance computer (primary): sw219 vehicle speed";
CM_ SG_ 1513 APP_sw230_sensor1Blocked "Driver assistance computer (primary): sw230 sensor1 blocked";
CM_ SG_ 1513 APP_sw230_sensor2Blocked "Driver assistance computer (primary): sw230 sensor2 blocked";
CM_ SG_ 1513 APP_sw230_sensor3Blocked "Driver assistance computer (primary): sw230 sensor3 blocked";
CM_ SG_ 1513 APP_sw230_sensor4Blocked "Driver assistance computer (primary): sw230 sensor4 blocked";
CM_ SG_ 1513 APP_sw230_sensor5Blocked "Driver assistance computer (primary): sw230 sensor5 blocked";
CM_ SG_ 1513 APP_sw230_sensor6Blocked "Driver assistance computer (primary): sw230 sensor6 blocked";
CM_ SG_ 1513 APP_sw230_sensor7Blocked "Driver assistance computer (primary): sw230 sensor7 blocked";
CM_ SG_ 1513 APP_sw230_sensor8Blocked "Driver assistance computer (primary): sw230 sensor8 blocked";
CM_ SG_ 1513 APP_sw230_sensor9Blocked "Driver assistance computer (primary): sw230 sensor9 blocked";
CM_ SG_ 1513 APP_sw230_sensor10Blocked "Driver assistance computer (primary): sw230 sensor10 blocked";
CM_ SG_ 1513 APP_sw230_sensor11Blocked "Driver assistance computer (primary): sw230 sensor11 blocked";
CM_ SG_ 1513 APP_sw230_sensor12Blocked "Driver assistance computer (primary): sw230 sensor12 blocked";
CM_ SG_ 1513 APP_sw260_target_dx "Driver assistance computer (primary): sw260 target dx";
CM_ SG_ 1513 APP_sw260_target_vx "Driver assistance computer (primary): sw260 target vx";
CM_ SG_ 1513 APP_sw260_target_ax "Driver assistance computer (primary): sw260 target ax";
CM_ SG_ 1513 APP_sw260_ego_speed "Driver assistance computer (primary): sw260 ego speed";
CM_ SG_ 1513 APP_sw260_driver_reaction_time "Driver assistance computer (primary): sw260 driver reaction time";
CM_ SG_ 1513 APP_sw260_driver_reqd_accel "Driver assistance computer (primary): sw260 driver reqd accel";
CM_ SG_ 1513 APP_sw260_user_sensitivity "Driver assistance computer (primary): sw260 user sensitivity; raw 3 = signal not available (SNA)";
CM_ SG_ 1513 APP_sw261_correctableErrors "Driver assistance computer (primary): sw261 correctable errors";
CM_ SG_ 1513 APP_sw261_nonFatalUncorrErrors "Driver assistance computer (primary): sw261 non fatal uncorr errors";
CM_ SG_ 1513 APP_sw261_fatalUncorrErrors "Driver assistance computer (primary): sw261 fatal uncorr errors";
CM_ SG_ 1513 APP_sw263_torsionThreshold "Driver assistance computer (primary): sw263 torsion threshold";
CM_ SG_ 1513 APP_sw263_eacStatusNotOk "Driver assistance computer (primary): sw263 eac status not ok";
CM_ SG_ 1513 APP_sw263_timerExpired "Driver assistance computer (primary): sw263 timer expired";
CM_ SG_ 1513 APP_sw263_notStableInLane "Driver assistance computer (primary): sw263 not stable in lane";
CM_ SG_ 1513 APP_sw263_outOfSpeedRegion "Driver assistance computer (primary): sw263 out of speed region";
CM_ SG_ 1513 APP_sw263_laneTooNarrow "Driver assistance computer (primary): sw263 lane too narrow";
CM_ SG_ 1513 APP_sw263_elkConditionsMet "Driver assistance computer (primary): sw263 elk conditions met";
CM_ SG_ 1513 APP_sw263_lkaConditionsMet "Driver assistance computer (primary): sw263 lka conditions met";
CM_ SG_ 1513 APP_sw263_ldwConditionsMet "Driver assistance computer (primary): sw263 ldw conditions met";
CM_ SG_ 1513 APP_sw263_multiLane "Driver assistance computer (primary): sw263 multi lane";
CM_ SG_ 1513 APP_sw263_noCollisionImminent "Driver assistance computer (primary): sw263 no collision imminent";
CM_ SG_ 1513 APP_sw263_blinkerActive "Driver assistance computer (primary): sw263 blinker active";
CM_ SG_ 1513 APP_sw263_notEncroaching "Driver assistance computer (primary): sw263 not encroaching";
CM_ SG_ 1513 APP_sw263_dtleAboveThresholdLdw "Driver assistance computer (primary): sw263 dtle above threshold ldw";
CM_ SG_ 1513 APP_sw263_markerType "Driver assistance computer (primary): sw263 marker type";
CM_ SG_ 1513 APP_sw263_side "Driver assistance computer (primary): sw263 side";
CM_ SG_ 1513 APP_sw263_speed "Driver assistance computer (primary): sw263 speed";
CM_ SG_ 1513 APP_sw263_laneWidth "Driver assistance computer (primary): sw263 lane width";
CM_ SG_ 1513 APP_sw263_vdcActive "Driver assistance computer (primary): sw263 vdc active";
CM_ SG_ 1513 APP_sw263_construction "Driver assistance computer (primary): sw263 construction";
CM_ SG_ 1513 APP_sw263_snowyRoad "Driver assistance computer (primary): sw263 snowy road";
CM_ SG_ 1513 APP_sw263_sideObstacle "Driver assistance computer (primary): sw263 side obstacle";
CM_ SG_ 1513 APP_sw263_frontObstacle "Driver assistance computer (primary): sw263 front obstacle";
CM_ SG_ 1513 APP_sw263_turnIndicatorOn "Driver assistance computer (primary): sw263 turn indicator on";
CM_ SG_ 1513 APP_sw263_vehicleMuLow "Driver assistance computer (primary): sw263 vehicle mu low";
CM_ SG_ 1513 APP_sw263_lssAbortReason "Driver assistance computer (primary): sw263 lss abort reason";
CM_ SG_ 1513 APP_sw264_faultReason "Driver assistance computer (primary): sw264 fault reason";
CM_ SG_ 1513 APP_sw265_mpHasRoute "Driver assistance computer (primary): sw265 mp has route";
CM_ SG_ 1513 APP_sw265_mpLocalizedWay "Driver assistance computer (primary): sw265 mp localized way";
CM_ SG_ 1513 APP_sw265_mmHasRoute "Driver assistance computer (primary): sw265 mm has route";
CM_ SG_ 1513 APP_sw265_mmLocalizedEdge "Driver assistance computer (primary): sw265 mm localized edge";
CM_ SG_ 1513 APP_sw265_surroundCameraStatus "Driver assistance computer (primary): sw265 surround camera status";
CM_ SG_ 1513 APP_sw265_unavailableReason "Driver assistance computer (primary): sw265 unavailable reason";
CM_ SG_ 1513 APP_sw265_leftPillarBlocked "Driver assistance computer (primary): sw265 left pillar blocked";
CM_ SG_ 1513 APP_sw265_rightPillarBlocked "Driver assistance computer (primary): sw265 right pillar blocked";
CM_ SG_ 1513 APP_sw265_leftRepeaterBlocked "Driver assistance computer (primary): sw265 left repeater blocked";
CM_ SG_ 1513 APP_sw265_rightRepeaterBlocked "Driver assistance computer (primary): sw265 right repeater blocked";
CM_ SG_ 1513 APP_sw265_backupBlocked "Driver assistance computer (primary): sw265 backup blocked";
CM_ SG_ 1513 APP_sw265_exceptionListInvalid "Driver assistance computer (primary): sw265 exception list invalid";
CM_ SG_ 1513 APP_sw265_lPillarLanesFailsafe "Driver assistance computer (primary): sw265 l pillar lanes failsafe";
CM_ SG_ 1513 APP_sw265_rPillarLanesFailsafe "Driver assistance computer (primary): sw265 r pillar lanes failsafe";
CM_ SG_ 1513 APP_sw265_lRepeaterLanesFailsafe "Driver assistance computer (primary): sw265 l repeater lanes failsafe";
CM_ SG_ 1513 APP_sw265_rRepeaterLanesFailsafe "Driver assistance computer (primary): sw265 r repeater lanes failsafe";
CM_ SG_ 1513 APP_sw266_lPillarStreamStatus "Driver assistance computer (primary): sw266 l pillar stream status";
CM_ SG_ 1513 APP_sw266_rPillarStreamStatus "Driver assistance computer (primary): sw266 r pillar stream status";
CM_ SG_ 1513 APP_sw266_lRepeaterStreamStatus "Driver assistance computer (primary): sw266 l repeater stream status";
CM_ SG_ 1513 APP_sw266_rRepeaterStreamStatus "Driver assistance computer (primary): sw266 r repeater stream status";
CM_ SG_ 1513 APP_sw266_backupStreamStatus "Driver assistance computer (primary): sw266 backup stream status";
CM_ SG_ 1513 APP_sw269_mainStreamExit "Driver assistance computer (primary): sw269 main stream exit";
CM_ SG_ 1513 APP_sw269_narrowStreamExit "Driver assistance computer (primary): sw269 narrow stream exit";
CM_ SG_ 1513 APP_sw269_fisheyeStreamExit "Driver assistance computer (primary): sw269 fisheye stream exit";
CM_ SG_ 1513 APP_sw269_lPillarStreamExit "Driver assistance computer (primary): sw269 l pillar stream exit";
CM_ SG_ 1513 APP_sw269_rPillarStreamExit "Driver assistance computer (primary): sw269 r pillar stream exit";
CM_ SG_ 1513 APP_sw269_lRepeaterStreamExit "Driver assistance computer (primary): sw269 l repeater stream exit";
CM_ SG_ 1513 APP_sw269_rRepeaterStreamExit "Driver assistance computer (primary): sw269 r repeater stream exit";
CM_ SG_ 1513 APP_sw269_mainBlocked "Driver assistance computer (primary): sw269 main blocked";
CM_ SG_ 1513 APP_sw269_narrowBlocked "Driver assistance computer (primary): sw269 narrow blocked";
CM_ SG_ 1513 APP_sw269_fisheyeBlocked "Driver assistance computer (primary): sw269 fisheye blocked";
CM_ SG_ 1513 APP_sw269_lPillarBlocked "Driver assistance computer (primary): sw269 l pillar blocked";
CM_ SG_ 1513 APP_sw269_rPillarBlocked "Driver assistance computer (primary): sw269 r pillar blocked";
CM_ SG_ 1513 APP_sw269_lRepeaterBlocked "Driver assistance computer (primary): sw269 l repeater blocked";
CM_ SG_ 1513 APP_sw269_rRepeaterBlocked "Driver assistance computer (primary): sw269 r repeater blocked";
CM_ SG_ 1513 APP_sw269_lPillarLanesFailsafe "Driver assistance computer (primary): sw269 l pillar lanes failsafe";
CM_ SG_ 1513 APP_sw269_rPillarLanesFailsafe "Driver assistance computer (primary): sw269 r pillar lanes failsafe";
CM_ SG_ 1513 APP_sw269_lRepeaterLanesFailsafe "Driver assistance computer (primary): sw269 l repeater lanes failsafe";
CM_ SG_ 1513 APP_sw269_rRepeaterLanesFailsafe "Driver assistance computer (primary): sw269 r repeater lanes failsafe";
CM_ SG_ 1513 APP_sw269_aebOffInOffRoadMode "Driver assistance computer (primary): sw269 aeb off in off road mode";
CM_ SG_ 1513 APP_sw269_emergencyLaneKeep "Driver assistance computer (primary): sw269 emergency lane keep; raw 31 = signal not available (SNA)";
CM_ SG_ 1513 APP_sw269_laneKeepAssist "Driver assistance computer (primary): sw269 lane keep assist; raw 31 = signal not available (SNA)";
CM_ SG_ 1513 APP_sw269_blindspot "Driver assistance computer (primary): sw269 blindspot; raw 31 = signal not available (SNA)";
CM_ SG_ 1513 APP_sw269_laneDepartureWarning "Driver assistance computer (primary): sw269 lane departure warning; raw 31 = signal not available (SNA)";
CM_ SG_ 1513 APP_sw270_mainStreamExit "Driver assistance computer (primary): sw270 main stream exit";
CM_ SG_ 1513 APP_sw270_lPillarStreamExit "Driver assistance computer (primary): sw270 l pillar stream exit";
CM_ SG_ 1513 APP_sw270_rPillarStreamExit "Driver assistance computer (primary): sw270 r pillar stream exit";
CM_ SG_ 1513 APP_sw270_lRepeaterStreamExit "Driver assistance computer (primary): sw270 l repeater stream exit";
CM_ SG_ 1513 APP_sw270_rRepeaterStreamExit "Driver assistance computer (primary): sw270 r repeater stream exit";
CM_ SG_ 1513 APP_sw270_lPillarBlocked "Driver assistance computer (primary): sw270 l pillar blocked";
CM_ SG_ 1513 APP_sw270_rPillarBlocked "Driver assistance computer (primary): sw270 r pillar blocked";
CM_ SG_ 1513 APP_sw270_lRepeaterBlocked "Driver assistance computer (primary): sw270 l repeater blocked";
CM_ SG_ 1513 APP_sw270_rRepeaterBlocked "Driver assistance computer (primary): sw270 r repeater blocked";
CM_ SG_ 1513 APP_sw270_lPillarLanesFailsafe "Driver assistance computer (primary): sw270 l pillar lanes failsafe";
CM_ SG_ 1513 APP_sw270_rPillarLanesFailsafe "Driver assistance computer (primary): sw270 r pillar lanes failsafe";
CM_ SG_ 1513 APP_sw270_lRepeaterLanesFailsafe "Driver assistance computer (primary): sw270 l repeater lanes failsafe";
CM_ SG_ 1513 APP_sw270_rRepeaterLanesFailsafe "Driver assistance computer (primary): sw270 r repeater lanes failsafe";
CM_ SG_ 1513 APP_sw270_mainBlocked "Driver assistance computer (primary): sw270 main blocked";
CM_ SG_ 1513 APP_sw270_narrowBlocked "Driver assistance computer (primary): sw270 narrow blocked";
CM_ SG_ 1513 APP_sw270_fisheyeBlocked "Driver assistance computer (primary): sw270 fisheye blocked";
CM_ SG_ 1513 APP_sw270_aebOffInOffRoadMode "Driver assistance computer (primary): sw270 aeb off in off road mode";
CM_ SG_ 1513 APP_sw270_emergencyLaneKeep "Driver assistance computer (primary): sw270 emergency lane keep; raw 31 = signal not available (SNA)";
CM_ SG_ 1513 APP_sw270_laneKeepAssist "Driver assistance computer (primary): sw270 lane keep assist; raw 31 = signal not available (SNA)";
CM_ SG_ 1513 APP_sw270_blindspot "Driver assistance computer (primary): sw270 blindspot; raw 31 = signal not available (SNA)";
CM_ SG_ 1513 APP_sw270_laneDepartureWarning "Driver assistance computer (primary): sw270 lane departure warning; raw 31 = signal not available (SNA)";
CM_ SG_ 1513 APP_sw271_abortReason "Driver assistance computer (primary): sw271 abort reason";
CM_ SG_ 1513 APP_sw271_direction "Driver assistance computer (primary): sw271 direction";
CM_ SG_ 1513 APP_sw271_progress "Driver assistance computer (primary): sw271 progress";
CM_ SG_ 1513 APP_sw271_egoSpeed "Driver assistance computer (primary): sw271 ego speed";
CM_ SG_ 1513 APP_sw272_unavailableReason "Driver assistance computer (primary): sw272 unavailable reason";
CM_ SG_ 1513 APP_sw272_lPillarStreamExit "Driver assistance computer (primary): sw272 l pillar stream exit";
CM_ SG_ 1513 APP_sw272_rPillarStreamExit "Driver assistance computer (primary): sw272 r pillar stream exit";
CM_ SG_ 1513 APP_sw272_lRepeaterStreamExit "Driver assistance computer (primary): sw272 l repeater stream exit";
CM_ SG_ 1513 APP_sw272_rRepeaterStreamExit "Driver assistance computer (primary): sw272 r repeater stream exit";
CM_ SG_ 1513 APP_sw272_lPillarBlocked "Driver assistance computer (primary): sw272 l pillar blocked";
CM_ SG_ 1513 APP_sw272_rPillarBlocked "Driver assistance computer (primary): sw272 r pillar blocked";
CM_ SG_ 1513 APP_sw272_lRepeaterBlocked "Driver assistance computer (primary): sw272 l repeater blocked";
CM_ SG_ 1513 APP_sw272_rRepeaterBlocked "Driver assistance computer (primary): sw272 r repeater blocked";
CM_ SG_ 1513 APP_sw273_eventType "Driver assistance computer (primary): sw273 event type";
CM_ SG_ 1513 APP_sw273_collisionType "Driver assistance computer (primary): sw273 collision type";
CM_ SG_ 1513 APP_sw273_side "Driver assistance computer (primary): sw273 side";
CM_ SG_ 1513 APP_sw273_alarmStrikes "Driver assistance computer (primary): sw273 alarm strikes";
CM_ SG_ 1513 APP_sw273_handsOn "Driver assistance computer (primary): sw273 hands on";
CM_ SG_ 1513 APP_sw273_timeToCollision "Driver assistance computer (primary): sw273 time to collision";
CM_ SG_ 1513 APP_sw273_lngDistanceToVehicle "Driver assistance computer (primary): sw273 lng distance to vehicle";
CM_ SG_ 1513 APP_sw273_latDistanceToVehicle "Driver assistance computer (primary): sw273 lat distance to vehicle";
CM_ SG_ 1513 APP_sw273_timeToLaneExit "Driver assistance computer (primary): sw273 time to lane exit";
CM_ SG_ 1513 APP_sw273_distanceToLaneExit "Driver assistance computer (primary): sw273 distance to lane exit";
CM_ SG_ 1513 APP_sw283_appAbortReason "Driver assistance computer (primary): sw283 app abort reason";
CM_ SG_ 1513 APP_sw283_apsAbortReason "Driver assistance computer (primary): sw283 aps abort reason";
CM_ SG_ 1513 APP_sw283_distanceTravelled "Driver assistance computer (primary): sw283 distance travelled";
CM_ SG_ 1513 APP_sw283_phoneDistance "Driver assistance computer (primary): sw283 phone distance";
CM_ SG_ 1513 APP_sw283_goalDistance "Driver assistance computer (primary): sw283 goal distance";
CM_ SG_ 1513 APP_sw283_mainCam "Driver assistance computer (primary): sw283 main cam";
CM_ SG_ 1513 APP_sw283_narrowCam "Driver assistance computer (primary): sw283 narrow cam";
CM_ SG_ 1513 APP_sw283_fisheyeCam "Driver assistance computer (primary): sw283 fisheye cam";
CM_ SG_ 1513 APP_sw283_leftRepeaterCam "Driver assistance computer (primary): sw283 left repeater cam";
CM_ SG_ 1513 APP_sw283_rightRepeaterCam "Driver assistance computer (primary): sw283 right repeater cam";
CM_ SG_ 1513 APP_sw283_leftPillarCam "Driver assistance computer (primary): sw283 left pillar cam";
CM_ SG_ 1513 APP_sw283_rightPillarCam "Driver assistance computer (primary): sw283 right pillar cam";
CM_ SG_ 1513 APP_sw283_bucCam "Driver assistance computer (primary): sw283 buc cam";
CM_ SG_ 1513 APP_sw284_antennaDisconnected "Driver assistance computer (primary): sw284 antenna disconnected";
CM_ SG_ 1513 APP_sw285_gpsCommMissing "Driver assistance computer (primary): sw285 gps comm missing";
CM_ SG_ 1513 APP_sw285_gpsJunkData "Driver assistance computer (primary): sw285 gps junk data";
CM_ SG_ 1513 APP_sw285_gpsNMEAmissing "Driver assistance computer (primary): sw285 gps NME amissing";
CM_ SG_ 1513 APP_sw285_gpsUBXmissing "Driver assistance computer (primary): sw285 gps UB xmissing";
CM_ SG_ 1513 APP_sw285_fusionModeDisabled "Driver assistance computer (primary): sw285 fusion mode disabled";
CM_ SG_ 1513 APP_sw285_gpsCfgFail "Driver assistance computer (primary): sw285 gps cfg fail";
CM_ SG_ 1513 APP_sw285_esfStatusMsgMIA "Driver assistance computer (primary): sw285 esf status msg MIA";
CM_ SG_ 1513 APP_sw285_wheelTickCfgMissmatch "Driver assistance computer (primary): sw285 wheel tick cfg missmatch";
CM_ SG_ 1513 APP_sw285_exitTransportMode "Driver assistance computer (primary): sw285 exit transport mode";
CM_ SG_ 1513 APP_sw285_satRejectionTimeout "Driver assistance computer (primary): sw285 sat rejection timeout";
CM_ SG_ 1513 APP_sw285_gpsPPSMissing "Driver assistance computer (primary): sw285 gps PPS missing";
CM_ SG_ 1513 APP_sw286_cfgBufNull "Driver assistance computer (primary): sw286 cfg buf null";
CM_ SG_ 1513 APP_sw286_invalidID "Driver assistance computer (primary): sw286 invalid ID";
CM_ SG_ 1513 APP_sw286_gpsBufferOverflow "Driver assistance computer (primary): sw286 gps buffer overflow";
CM_ SG_ 1513 APP_sw286_navx5CfgFailed "Driver assistance computer (primary): sw286 navx5 cfg failed";
CM_ SG_ 1513 APP_sw286_mcuNMEAmsgUDPinvalid "Driver assistance computer (primary): sw286 mcu NME amsg UD pinvalid";
CM_ SG_ 1513 APP_sw286_mcuDbgMsgInvalid "Driver assistance computer (primary): sw286 mcu dbg msg invalid";
CM_ SG_ 1513 APP_sw286_mcuDbgMsgTooBig "Driver assistance computer (primary): sw286 mcu dbg msg too big";
CM_ SG_ 1513 APP_sw286_mcuFwdNMEAfail "Driver assistance computer (primary): sw286 mcu fwd NME afail";
CM_ SG_ 1513 APP_sw286_NMEAinvalidChecksum "Driver assistance computer (primary): sw286 NME ainvalid checksum";
CM_ SG_ 1513 APP_sw286_unexpectedNMEAmsg "Driver assistance computer (primary): sw286 unexpected NME amsg";
CM_ SG_ 1513 APP_sw286_UARTbusFull "Driver assistance computer (primary): sw286 UAR tbus full";
CM_ SG_ 1513 APP_sw286_UARTframeError "Driver assistance computer (primary): sw286 UAR tframe error";
CM_ SG_ 1513 APP_sw286_UBXrxFrameTooBig "Driver assistance computer (primary): sw286 UB xrx frame too big";
CM_ SG_ 1513 APP_sw286_emptyValidNMEA "Driver assistance computer (primary): sw286 empty valid NMEA";
CM_ SG_ 1513 APP_sw286_invalidAsciiNMEA "Driver assistance computer (primary): sw286 invalid ascii NMEA";
CM_ SG_ 1513 APP_sw286_wheeltickUARTfault "Driver assistance computer (primary): sw286 wheeltick UAR tfault";
CM_ SG_ 1513 APP_sw286_baudrateMismatch "Driver assistance computer (primary): sw286 baudrate mismatch";
CM_ SG_ 1513 APP_sw286_wheelTickInvalidSrc "Driver assistance computer (primary): sw286 wheel tick invalid src";
CM_ SG_ 1513 APP_sw286_UARTparityError "Driver assistance computer (primary): sw286 UAR tparity error";
CM_ SG_ 1513 APP_sw286_UARTrxFifoOverflow "Driver assistance computer (primary): sw286 UAR trx fifo overflow";
CM_ SG_ 1513 APP_sw286_UARTrxFifoUnderflow "Driver assistance computer (primary): sw286 UAR trx fifo underflow";
CM_ SG_ 1513 APP_sw286_UARTtxFifoOverflow "Driver assistance computer (primary): sw286 UAR ttx fifo overflow";
CM_ SG_ 1513 APP_sw286_esfWtMsgTimeout "Driver assistance computer (primary): sw286 esf wt msg timeout";
CM_ SG_ 1513 APP_sw286_PFLASHReadError "Driver assistance computer (primary): sw286 PFLASH read error";
CM_ SG_ 1513 APP_sw286_PFLASHWriteError "Driver assistance computer (primary): sw286 PFLASH write error";
CM_ SG_ 1513 APP_sw286_gpsCfgNack "Driver assistance computer (primary): sw286 gps cfg nack";
CM_ SG_ 1513 APP_sw286_gpsCfgIdFail "Driver assistance computer (primary): sw286 gps cfg id fail";
CM_ SG_ 1513 APP_sw286_gpsSetCfgNoAck "Driver assistance computer (primary): sw286 gps set cfg no ack";
CM_ SG_ 1513 APP_sw286_gpsReadCfgNoResponse "Driver assistance computer (primary): sw286 gps read cfg no response";
CM_ SG_ 1513 APP_sw286_ubxErrorReported "Driver assistance computer (primary): sw286 ubx error reported";
CM_ SG_ 1513 APP_sw288_dist_to_stop "Driver assistance computer (primary): sw288 dist to stop";
CM_ SG_ 1513 APP_sw288_ego_speed "Driver assistance computer (primary): sw288 ego speed";
CM_ SG_ 1513 APP_sw288_ego_acceleration "Driver assistance computer (primary): sw288 ego acceleration";
CM_ SG_ 1513 APP_sw291_dist_to_stop "Driver assistance computer (primary): sw291 dist to stop";
CM_ SG_ 1513 APP_sw291_ego_speed "Driver assistance computer (primary): sw291 ego speed";
CM_ SG_ 1513 APP_sw291_ego_acceleration "Driver assistance computer (primary): sw291 ego acceleration";
CM_ SG_ 1513 APP_sw293_clockFrequencyDrift "Driver assistance computer (primary): sw293 clock frequency drift";
CM_ SG_ 1513 APP_sw294_clockFrequencyDrift "Driver assistance computer (primary): sw294 clock frequency drift";
CM_ SG_ 1513 APP_sw295_clockFrequencyDrift "Driver assistance computer (primary): sw295 clock frequency drift";
CM_ SG_ 1513 APP_sw296_clockFrequencyDrift "Driver assistance computer (primary): sw296 clock frequency drift";
CM_ SG_ 1513 APP_sw297_clockFrequencyDrift "Driver assistance computer (primary): sw297 clock frequency drift";
CM_ SG_ 1513 APP_sw298_clockFrequencyDrift "Driver assistance computer (primary): sw298 clock frequency drift";
CM_ SG_ 1513 APP_sw299_clockFrequencyDrift "Driver assistance computer (primary): sw299 clock frequency drift";
CM_ SG_ 1513 APP_sw300_clockFrequencyDrift "Driver assistance computer (primary): sw300 clock frequency drift";
CM_ SG_ 1513 APP_sw301_clockFrequencyDrift "Driver assistance computer (primary): sw301 clock frequency drift";
CM_ SG_ 1513 APP_sw302_AP_vehicleState10Hz "Driver assistance computer (primary): sw302 AP vehicle state10 hz";
CM_ SG_ 1513 APP_sw304_lssLPillarBlocked "Driver assistance computer (primary): sw304 lss l pillar blocked";
CM_ SG_ 1513 APP_sw304_lssRPillarBlocked "Driver assistance computer (primary): sw304 lss r pillar blocked";
CM_ SG_ 1513 APP_sw304_lssLRepeaterBlocked "Driver assistance computer (primary): sw304 lss l repeater blocked";
CM_ SG_ 1513 APP_sw304_lssRRepeaterBlocked "Driver assistance computer (primary): sw304 lss r repeater blocked";
CM_ SG_ 1513 APP_sw304_lssMainBlocked "Driver assistance computer (primary): sw304 lss main blocked";
CM_ SG_ 1513 APP_sw305_lssLPillarStreamExit "Driver assistance computer (primary): sw305 lss l pillar stream exit";
CM_ SG_ 1513 APP_sw305_lssRPillarStreamExit "Driver assistance computer (primary): sw305 lss r pillar stream exit";
CM_ SG_ 1513 APP_sw305_lssLRepeaterStreamExit "Driver assistance computer (primary): sw305 lss l repeater stream exit";
CM_ SG_ 1513 APP_sw305_lssRRepeaterStreamExit "Driver assistance computer (primary): sw305 lss r repeater stream exit";
CM_ SG_ 1513 APP_sw306_lssUssS1Blocked "Driver assistance computer (primary): sw306 lss uss S1 blocked";
CM_ SG_ 1513 APP_sw306_lssUssS2Blocked "Driver assistance computer (primary): sw306 lss uss S2 blocked";
CM_ SG_ 1513 APP_sw306_lssUssS3Blocked "Driver assistance computer (primary): sw306 lss uss S3 blocked";
CM_ SG_ 1513 APP_sw306_lssUssS4Blocked "Driver assistance computer (primary): sw306 lss uss S4 blocked";
CM_ SG_ 1513 APP_sw306_lssUssS5Blocked "Driver assistance computer (primary): sw306 lss uss S5 blocked";
CM_ SG_ 1513 APP_sw306_lssUssS6Blocked "Driver assistance computer (primary): sw306 lss uss S6 blocked";
CM_ SG_ 1513 APP_sw306_lssUssS7Blocked "Driver assistance computer (primary): sw306 lss uss S7 blocked";
CM_ SG_ 1513 APP_sw306_lssUssS8Blocked "Driver assistance computer (primary): sw306 lss uss S8 blocked";
CM_ SG_ 1513 APP_sw306_lssUssS9Blocked "Driver assistance computer (primary): sw306 lss uss S9 blocked";
CM_ SG_ 1513 APP_sw306_lssUssS10Blocked "Driver assistance computer (primary): sw306 lss uss S10 blocked";
CM_ SG_ 1513 APP_sw306_lssUssS11Blocked "Driver assistance computer (primary): sw306 lss uss S11 blocked";
CM_ SG_ 1513 APP_sw306_lssUssS12Blocked "Driver assistance computer (primary): sw306 lss uss S12 blocked";
CM_ SG_ 1513 APP_sw307_lssTurnSignalFLFault "Driver assistance computer (primary): sw307 lss turn signal FL fault";
CM_ SG_ 1513 APP_sw307_lssTurnSignalFRFault "Driver assistance computer (primary): sw307 lss turn signal FR fault";
CM_ SG_ 1513 APP_sw307_lssTurnSignalRLFault "Driver assistance computer (primary): sw307 lss turn signal RL fault";
CM_ SG_ 1513 APP_sw307_lssTurnSignalRRFault "Driver assistance computer (primary): sw307 lss turn signal RR fault";
CM_ SG_ 1513 APP_sw308_IBST_status "Driver assistance computer (primary): sw308 IBST status";
CM_ SG_ 1513 APP_sw321_energyStatus "Driver assistance computer (primary): sw321 energy status";
CM_ SG_ 1513 APP_sw321_status "Driver assistance computer (primary): sw321 status";
CM_ SG_ 1513 APP_sw322_sunGlare "Driver assistance computer (primary): sw322 sun glare";
CM_ SG_ 1513 APP_sw322_blinded "Driver assistance computer (primary): sw322 blinded";
CM_ SG_ 1513 APP_sw322_falseWipe "Driver assistance computer (primary): sw322 false wipe";
CM_ SG_ 1513 APP_sw323_confidence "Driver assistance computer (primary): sw323 confidence";
CM_ SG_ 1513 APP_sw323_distance "Driver assistance computer (primary): sw323 distance";
CM_ SG_ 1513 APP_sw323_ttc "Driver assistance computer (primary): sw323 ttc";
CM_ SG_ 1513 APP_sw324_state "Driver assistance computer (primary): sw324 state";
CM_ SG_ 1513 APP_sw325_taskId "Driver assistance computer (primary): sw325 task id";
CM_ SG_ 1513 APP_sw325_issue "Driver assistance computer (primary): sw325 issue";
CM_ SG_ 1513 APP_sw327_driveHandSideMismatch "Driver assistance computer (primary): sw327 drive hand side mismatch";
CM_ SG_ 1513 APP_sw327_hardwareTypeMismatch "Driver assistance computer (primary): sw327 hardware type mismatch";
CM_ SG_ 1513 APP_sw327_turboTypeMismatch "Driver assistance computer (primary): sw327 turbo type mismatch";
CM_ SG_ 1513 APP_sw327_epasTypeMismatch "Driver assistance computer (primary): sw327 epas type mismatch";
CM_ SG_ 1513 APP_sw327_radarTypeMismatch "Driver assistance computer (primary): sw327 radar type mismatch";
CM_ SG_ 1513 APP_sw327_chassisTypeMismatch "Driver assistance computer (primary): sw327 chassis type mismatch";
CM_ SG_ 1513 APP_sw327_displayTypeMismatch "Driver assistance computer (primary): sw327 display type mismatch";
CM_ SG_ 1513 APP_sw327_cameraTypeMismatch "Driver assistance computer (primary): sw327 camera type mismatch";
CM_ SG_ 1513 APP_sw327_parkAssistTypeMismatch "Driver assistance computer (primary): sw327 park assist type mismatch";
CM_ SG_ 1513 APP_sw327_selfieCamTypeMismatch "Driver assistance computer (primary): sw327 selfie cam type mismatch";
CM_ SG_ 1513 APP_sw328_ussS1Unavailable "Driver assistance computer (primary): sw328 uss S1 unavailable";
CM_ SG_ 1513 APP_sw328_ussS2Unavailable "Driver assistance computer (primary): sw328 uss S2 unavailable";
CM_ SG_ 1513 APP_sw328_ussS3Unavailable "Driver assistance computer (primary): sw328 uss S3 unavailable";
CM_ SG_ 1513 APP_sw328_ussS4Unavailable "Driver assistance computer (primary): sw328 uss S4 unavailable";
CM_ SG_ 1513 APP_sw328_ussS5Unavailable "Driver assistance computer (primary): sw328 uss S5 unavailable";
CM_ SG_ 1513 APP_sw328_ussS6Unavailable "Driver assistance computer (primary): sw328 uss S6 unavailable";
CM_ SG_ 1513 APP_sw328_ussS7Unavailable "Driver assistance computer (primary): sw328 uss S7 unavailable";
CM_ SG_ 1513 APP_sw328_ussS8Unavailable "Driver assistance computer (primary): sw328 uss S8 unavailable";
CM_ SG_ 1513 APP_sw328_ussS9Unavailable "Driver assistance computer (primary): sw328 uss S9 unavailable";
CM_ SG_ 1513 APP_sw328_ussS10Unavailable "Driver assistance computer (primary): sw328 uss S10 unavailable";
CM_ SG_ 1513 APP_sw328_ussS11Unavailable "Driver assistance computer (primary): sw328 uss S11 unavailable";
CM_ SG_ 1513 APP_sw328_ussS12Unavailable "Driver assistance computer (primary): sw328 uss S12 unavailable";
CM_ SG_ 1513 APP_sw328_fisheyeStreamExit "Driver assistance computer (primary): sw328 fisheye stream exit";
CM_ SG_ 1513 APP_sw328_lPillarStreamExit "Driver assistance computer (primary): sw328 l pillar stream exit";
CM_ SG_ 1513 APP_sw328_rPillarStreamExit "Driver assistance computer (primary): sw328 r pillar stream exit";
CM_ SG_ 1513 APP_sw328_lRepeaterStreamExit "Driver assistance computer (primary): sw328 l repeater stream exit";
CM_ SG_ 1513 APP_sw328_rRepeaterStreamExit "Driver assistance computer (primary): sw328 r repeater stream exit";
CM_ SG_ 1513 APP_sw328_backupStreamExit "Driver assistance computer (primary): sw328 backup stream exit";
CM_ SG_ 1513 APP_sw328_fisheyeCal "Driver assistance computer (primary): sw328 fisheye cal";
CM_ SG_ 1513 APP_sw328_lPillarCal "Driver assistance computer (primary): sw328 l pillar cal";
CM_ SG_ 1513 APP_sw328_rPillarCal "Driver assistance computer (primary): sw328 r pillar cal";
CM_ SG_ 1513 APP_sw328_lRepeaterCal "Driver assistance computer (primary): sw328 l repeater cal";
CM_ SG_ 1513 APP_sw328_rRepeaterCal "Driver assistance computer (primary): sw328 r repeater cal";
CM_ SG_ 1513 APP_sw328_backupCal "Driver assistance computer (primary): sw328 backup cal";
CM_ SG_ 1513 APP_sw328_epasMia "Driver assistance computer (primary): sw328 epas mia";
CM_ SG_ 1513 APP_sw328_espMia "Driver assistance computer (primary): sw328 esp mia";
CM_ SG_ 1513 APP_sw328_parkMia "Driver assistance computer (primary): sw328 park mia";
CM_ SG_ 1513 APP_sw328_sccmMia "Driver assistance computer (primary): sw328 sccm mia";
CM_ SG_ 1513 APP_sw328_scMia "Driver assistance computer (primary): sw328 sc mia";
CM_ SG_ 1513 APP_sw328_ussOLONotEnabled "Driver assistance computer (primary): sw328 uss OLO not enabled";
CM_ SG_ 1513 APP_sw328_ussPASNotEnabled "Driver assistance computer (primary): sw328 uss PAS not enabled";
CM_ SG_ 1513 APP_sw328_ussOOCNotEnabled "Driver assistance computer (primary): sw328 uss OOC not enabled";
CM_ SG_ 1513 APP_sw328_ussTemporaryFault "Driver assistance computer (primary): sw328 uss temporary fault";
CM_ SG_ 1513 APP_sw328_ussSystemError "Driver assistance computer (primary): sw328 uss system error";
CM_ SG_ 1513 APP_sw328_ussFault "Driver assistance computer (primary): sw328 uss fault";
CM_ SG_ 1513 APP_sw328_ussStatusOutOfDate "Driver assistance computer (primary): sw328 uss status out of date";
CM_ SG_ 1513 APP_sw328_perceptionUnhealthy "Driver assistance computer (primary): sw328 perception unhealthy";
CM_ SG_ 1513 APP_sw328_drivableSpaceUnhealthy "Driver assistance computer (primary): sw328 drivable space unhealthy";
CM_ SG_ 1513 APP_sw328_uiDisplayNotOk "Driver assistance computer (primary): sw328 ui display not ok";
CM_ SG_ 1513 APP_sw328_externalLightsOff "Driver assistance computer (primary): sw328 external lights off";
CM_ SG_ 1513 APP_sw328_forwardCamerasBlinded "Driver assistance computer (primary): sw328 forward cameras blinded";
CM_ SG_ 1513 APP_sw328_backupCameraBlinded "Driver assistance computer (primary): sw328 backup camera blinded";
CM_ SG_ 1513 APP_sw328_extComputeNotActive "Driver assistance computer (primary): sw328 ext compute not active";
CM_ SG_ 1513 APP_sw329_cipvSysReqAccel "Driver assistance computer (primary): sw329 cipv sys req accel";
CM_ SG_ 1513 APP_sw329_leftLaneReqAccel "Driver assistance computer (primary): sw329 left lane req accel";
CM_ SG_ 1513 APP_sw329_rightLaneReqAccel "Driver assistance computer (primary): sw329 right lane req accel";
CM_ SG_ 1513 APP_sw329_leftLaneAvailable "Driver assistance computer (primary): sw329 left lane available";
CM_ SG_ 1513 APP_sw329_rightLaneAvailable "Driver assistance computer (primary): sw329 right lane available";
CM_ SG_ 1513 APP_sw329_laneChangeLeft "Driver assistance computer (primary): sw329 lane change left";
CM_ SG_ 1513 APP_sw329_laneChangeRight "Driver assistance computer (primary): sw329 lane change right";
CM_ SG_ 1513 APP_sw329_leftLaneChngBehStatus "Driver assistance computer (primary): sw329 left lane chng beh status";
CM_ SG_ 1513 APP_sw329_rightLaneChngBehStatus "Driver assistance computer (primary): sw329 right lane chng beh status";
CM_ SG_ 1513 APP_sw330_initFailure "Driver assistance computer (primary): sw330 init failure";
CM_ SG_ 1513 APP_sw330_streamExit "Driver assistance computer (primary): sw330 stream exit";
CM_ SG_ 1513 APP_sw330_ledFault "Driver assistance computer (primary): sw330 led fault";
CM_ SG_ 1513 APP_sw331_lPillarOccluded "Driver assistance computer (primary): sw331 l pillar occluded";
CM_ SG_ 1513 APP_sw331_rPillarOccluded "Driver assistance computer (primary): sw331 r pillar occluded";
CM_ SG_ 1513 APP_sw331_lRepeaterOccluded "Driver assistance computer (primary): sw331 l repeater occluded";
CM_ SG_ 1513 APP_sw331_rRepeaterOccluded "Driver assistance computer (primary): sw331 r repeater occluded";
CM_ SG_ 1513 APP_sw331_gpsDegraded "Driver assistance computer (primary): sw331 gps degraded";
CM_ SG_ 1513 APP_sw331_poorWeather "Driver assistance computer (primary): sw331 poor weather";
CM_ SG_ 1513 APP_sw331_invalidMap "Driver assistance computer (primary): sw331 invalid map";
CM_ SG_ 1513 APP_sw331_adverseRoadConditions "Driver assistance computer (primary): sw331 adverse road conditions";
CM_ SG_ 1513 APP_sw332_narrowWithFisheye "Driver assistance computer (primary): sw332 narrow with fisheye";
CM_ SG_ 1513 APP_sw332_pillars "Driver assistance computer (primary): sw332 pillars";
CM_ SG_ 1513 APP_sw348_main "Driver assistance computer (primary): sw348 main";
CM_ SG_ 1513 APP_sw348_narrow "Driver assistance computer (primary): sw348 narrow";
CM_ SG_ 1513 APP_sw348_fisheye "Driver assistance computer (primary): sw348 fisheye";
CM_ SG_ 1513 APP_sw348_leftPillar "Driver assistance computer (primary): sw348 left pillar";
CM_ SG_ 1513 APP_sw348_rightPillar "Driver assistance computer (primary): sw348 right pillar";
CM_ SG_ 1513 APP_sw348_leftRepeater "Driver assistance computer (primary): sw348 left repeater";
CM_ SG_ 1513 APP_sw348_rightRepeater "Driver assistance computer (primary): sw348 right repeater";
CM_ SG_ 1513 APP_sw348_backup "Driver assistance computer (primary): sw348 backup";
CM_ SG_ 1513 APP_sw348_selfie "Driver assistance computer (primary): sw348 selfie";
CM_ SG_ 1513 APP_sw348_fascia "Driver assistance computer (primary): sw348 fascia";
CM_ SG_ 1513 APP_sw351_errorCode "Driver assistance computer (primary): sw351 error code";
CM_ SG_ 1513 APP_sw352_errorCode "Driver assistance computer (primary): sw352 error code";
CM_ SG_ 1513 APP_sw353_errorCode "Driver assistance computer (primary): sw353 error code";
CM_ SG_ 1513 APP_sw355_quad1 "Driver assistance computer (primary): sw355 quad1";
CM_ SG_ 1513 APP_sw355_quad2 "Driver assistance computer (primary): sw355 quad2";
CM_ SG_ 1513 APP_sw355_quad3 "Driver assistance computer (primary): sw355 quad3";
CM_ SG_ 1513 APP_sw355_quad1FailureRate "Driver assistance computer (primary): sw355 quad1 failure rate";
CM_ SG_ 1513 APP_sw355_quad2FailureRate "Driver assistance computer (primary): sw355 quad2 failure rate";
CM_ SG_ 1513 APP_sw355_quad3FailureRate "Driver assistance computer (primary): sw355 quad3 failure rate";
CM_ SG_ 1513 APP_sw357_cabinCameraFailsafeAct "Driver assistance computer (primary): sw357 cabin camera failsafe active";
CM_ SG_ 1513 APP_sw357_cameraDisabled "Driver assistance computer (primary): sw357 camera disabled";
CM_ SG_ 1513 APP_sw357_cameraNotStreaming "Driver assistance computer (primary): sw357 camera not streaming";
CM_ SG_ 1513 APP_sw357_disableByBuildCfg "Driver assistance computer (primary): sw357 disable by build cfg";
CM_ SG_ 1513 APP_sw357_invalidCameraFailsafe "Driver assistance computer (primary): sw357 invalid camera failsafe";
CM_ SG_ 1513 APP_sw357_invalidDrowsinessPredi "Driver assistance computer (primary): sw357 invalid drowsiness predictions";
CM_ SG_ 1513 APP_sw357_invalidSccmSteeringAng "Driver assistance computer (primary): sw357 invalid sccm steering angle";
CM_ SG_ 1513 APP_sw357_invalidSccmSteeri_0001 "Driver assistance computer (primary): sw357 invalid sccm steering angle rate";
CM_ SG_ 1513 APP_sw357_noVisionOutput "Driver assistance computer (primary): sw357 no vision output";
CM_ SG_ 1513 APP_sw357_poorFrontCameraVisibil "Driver assistance computer (primary): sw357 poor front camera visibility";
CM_ SG_ 1513 APP_sw357_staleVisionDv "Driver assistance computer (primary): sw357 stale vision dv";
CM_ SG_ 1513 APP_sw357_staleVisionOutput "Driver assistance computer (primary): sw357 stale vision output";
CM_ SG_ 1513 APP_sw357_sccmMia "Driver assistance computer (primary): sw357 sccm mia";
CM_ SG_ 1513 APP_sw357_electricalFaultForSccm "Driver assistance computer (primary): sw357 electrical fault for sccm";
CM_ SG_ 1513 APP_sw357_electricalFaultForMain "Driver assistance computer (primary): sw357 electrical fault for main cam";
CM_ SG_ 1513 APP_sw357_electricalFaultForCabi "Driver assistance computer (primary): sw357 electrical fault for cabin cam";
CM_ SG_ 1513 APP_sw357_mainCameraFailsafeActi "Driver assistance computer (primary): sw357 main camera failsafe active";
CM_ SG_ 1513 APP_sw357_electricalFaultForFish "Driver assistance computer (primary): sw357 electrical fault for fisheye cam";
CM_ SG_ 1513 APP_sw357_fisheyeCameraFailsafeA "Driver assistance computer (primary): sw357 fisheye camera failsafe active";
CM_ SG_ 1513 APP_sw357_camCalibOutOfBounds "Driver assistance computer (primary): sw357 cam calib out of bounds";
CM_ SG_ 1513 APP_sw358_noSpeedLimitSource "Driver assistance computer (primary): sw358 no speed limit source";
CM_ SG_ 1513 APP_sw358_mainCameraBlinded "Driver assistance computer (primary): sw358 main camera blinded";
CM_ SG_ 1513 APP_sw358_fisheyeCameraBlinded "Driver assistance computer (primary): sw358 fisheye camera blinded";
CM_ SG_ 1513 APP_sw358_mainCameraStreamUnavai "Driver assistance computer (primary): sw358 main camera stream unavailable";
CM_ SG_ 1513 APP_sw358_fisheyeCameraStreamUna "Driver assistance computer (primary): sw358 fisheye camera stream unavailable";
CM_ SG_ 1513 APP_sw358_camCalibOutOfBounds "Driver assistance computer (primary): sw358 cam calib out of bounds";
CM_ SG_ 1513 APP_sw359_mainCameraBlinded "Driver assistance computer (primary): sw359 main camera blinded";
CM_ SG_ 1513 APP_sw359_narrowCameraBlinded "Driver assistance computer (primary): sw359 narrow camera blinded";
CM_ SG_ 1513 APP_sw359_fisheyeCameraBlinded "Driver assistance computer (primary): sw359 fisheye camera blinded";
CM_ SG_ 1513 APP_sw362_fasciaCamDeserFault "Driver assistance computer (primary): sw362 fascia cam deser fault";
CM_ SG_ 1513 APP_sw362_fasciaCamI2CbusFault "Driver assistance computer (primary): sw362 fascia cam I2 cbus fault";
CM_ SG_ 1513 APP_sw362_fasciaCamSensorFault "Driver assistance computer (primary): sw362 fascia cam sensor fault";
CM_ SG_ 1513 APP_sw362_fasciaCamSerFault "Driver assistance computer (primary): sw362 fascia cam ser fault";
CM_ SG_ 1513 APP_sw363_exitStatus "Driver assistance computer (primary): sw363 exit status";
CM_ SG_ 1513 APP_sw363_bufferError "Driver assistance computer (primary): sw363 buffer error";
CM_ SG_ 1513 APP_sw363_frameGrabFailure "Driver assistance computer (primary): sw363 frame grab failure";
CM_ SG_ 1513 APP_sw363_gainControlFailure "Driver assistance computer (primary): sw363 gain control failure";
CM_ SG_ 1513 APP_sw363_tempMonitorFailure "Driver assistance computer (primary): sw363 temp monitor failure";
CM_ SG_ 1513 APP_sw363_firstFrameGrabFailure "Driver assistance computer (primary): sw363 first frame grab failure";
CM_ SG_ 1513 APP_sw363_deserParityError "Driver assistance computer (primary): sw363 deser parity error";
CM_ SG_ 1513 APP_sw363_deserLockError "Driver assistance computer (primary): sw363 deser lock error";
CM_ SG_ 1513 APP_sw363_deserCrcError "Driver assistance computer (primary): sw363 deser crc error";
CM_ SG_ 1513 APP_sw363_imagerHeartbeat "Driver assistance computer (primary): sw363 imager heartbeat; raw 3 = signal not available (SNA)";
CM_ SG_ 1513 APP_sw363_serializerCrcErrCount "Driver assistance computer (primary): sw363 serializer crc err count; raw 255 = signal not available (SNA)";
CM_ SG_ 1513 APP_sw363_deserLineLengthError "Driver assistance computer (primary): sw363 deser line length error";
CM_ SG_ 1513 APP_sw363_numCaptureRecoveries "Driver assistance computer (primary): sw363 num capture recoveries";
CM_ SG_ 1513 APP_sw363_currentTemperature "Driver assistance computer (primary): sw363 current temperature; raw 255 = signal not available (SNA)";
CM_ SG_ 1513 APP_sw363_minTemperature "Driver assistance computer (primary): sw363 min temperature; raw 255 = signal not available (SNA)";
CM_ SG_ 1513 APP_sw363_maxTemperature "Driver assistance computer (primary): sw363 max temperature; raw 255 = signal not available (SNA)";
CM_ SG_ 1513 APP_sw364_colorFilterMismatch "Driver assistance computer (primary): sw364 color filter mismatch";
CM_ SG_ 1513 APP_sw364_detectedColorFilter "Driver assistance computer (primary): sw364 detected color filter";
CM_ SG_ 1513 APP_sw364_expectedColorFilter "Driver assistance computer (primary): sw364 expected color filter";
CM_ SG_ 1513 APP_sw364_cameraPositionMismatch "Driver assistance computer (primary): sw364 camera position mismatch";
CM_ SG_ 1513 APP_sw364_blacklistedFuseID "Driver assistance computer (primary): sw364 blacklisted fuse ID";
CM_ SG_ 1513 APP_sw364_uuidMismatch "Driver assistance computer (primary): sw364 uuid mismatch";
CM_ SG_ 1513 APP_sw364_detectedPosition "Driver assistance computer (primary): sw364 detected position";
CM_ SG_ 1513 APP_sw365_fasciaCamExtNoCalFile "Driver assistance computer (primary): sw365 fascia cam ext no cal file";
CM_ SG_ 1513 APP_sw366_clockFrequencyDrift "Driver assistance computer (primary): sw366 clock frequency drift";
CM_ SG_ 1513 APP_sw371_decryptionFailed "Driver assistance computer (primary): sw371 decryption failed";
CM_ SG_ 1513 APP_sw389_frontCamResidue "Driver assistance computer (primary): sw389 front cam residue";
CM_ SG_ 1513 APP_sw389_leftPillarCamResidue "Driver assistance computer (primary): sw389 left pillar cam residue";
CM_ SG_ 1513 APP_sw389_rightPillarCamResidue "Driver assistance computer (primary): sw389 right pillar cam residue";
CM_ SG_ 1513 APP_sw397_apImuNoise "Driver assistance computer (primary): sw397 ap imu noise";
CM_ SG_ 1513 APP_sw399_status "Driver assistance computer (primary): sw399 status";
CM_ BO_ 1045 "Driver assistance computer (primary) message: backup dash cam status";
CM_ SG_ 1045 APP_backupDashCamFeedGood "Indicates if the backup dash cam stream is healthy.";
CM_ SG_ 1045 APP_backupDashCamFrameRate "The backup dash cam frame rate.";
CM_ BO_ 1020 "Driver assistance computer (primary) message: board temperatures";
CM_ SG_ 1020 APP_decisionTemperature "Rolling average of Parker and Pascal temperature.";
CM_ SG_ 1020 APP_pascalTemperature "Temperature of Autopilot GPU";
CM_ SG_ 1020 APP_parkerATemperature "Temperature of Autopilot CPU(1)";
CM_ SG_ 1020 APP_parkerBTemperature "Temperature of Autopilot CPU(1)";
CM_ SG_ 1020 APP_pascalExtTemperature "External temperature of Autopilot GPU";
CM_ SG_ 1020 APP_parkerExtTemperature "External temperature of Parker";
CM_ SG_ 1020 APP_pascalHeaterDecision "Pascal heater descision on/off";
CM_ BO_ 2046 "Driver assistance computer (primary) message: cam calibration status";
CM_ SG_ 2046 APP_cameraPosition "Driver assistance computer (primary): camera position";
CM_ SG_ 2046 APP_mainCamExtPitchCal "The calibration, pitch or yaw offset of a camera; raw 511 = signal not available (SNA)";
CM_ SG_ 2046 APP_mainCamExtYawCal "The calibration, pitch or yaw offset of a camera; raw 511 = signal not available (SNA)";
CM_ SG_ 2046 APP_mainCalibTime "Driver assistance computer (primary): main calib time; raw 127 = signal not available (SNA)";
CM_ SG_ 2046 APP_mainCalibProgress "The percent progress of the main camera calibration; raw 127 = signal not available (SNA)";
CM_ SG_ 2046 APP_mainCalibrated "Whether or not the main camera is calibrated.";
CM_ SG_ 2046 APP_narrowCamExtPitchCal "The calibration, pitch or yaw offset of a camera; raw 511 = signal not available (SNA)";
CM_ SG_ 2046 APP_narrowCamExtYawCal "The calibration, pitch or yaw offset of a camera; raw 511 = signal not available (SNA)";
CM_ SG_ 2046 APP_narrowCalibTime "Driver assistance computer (primary): narrow calib time; raw 127 = signal not available (SNA)";
CM_ SG_ 2046 APP_narrowCalibProgress "The percent progress of the narrow camera calibration; raw 127 = signal not available (SNA)";
CM_ SG_ 2046 APP_narrowCalibrated "Whether or not the narrow camera is calibrated.";
CM_ SG_ 2046 APP_fisheyeCamExtPitchCal "The calibration, pitch or yaw offset of a camera; raw 511 = signal not available (SNA)";
CM_ SG_ 2046 APP_fisheyeCamExtYawCal "The calibration, pitch or yaw offset of a camera; raw 511 = signal not available (SNA)";
CM_ SG_ 2046 APP_fisheyeCalibTime "Driver assistance computer (primary): fisheye calib time; raw 127 = signal not available (SNA)";
CM_ SG_ 2046 APP_fisheyeCalibProgress "The percent progress of the fisheye camera calibration; raw 127 = signal not available (SNA)";
CM_ SG_ 2046 APP_fisheyeCalibrated "Whether or not the fisheye camera is calibrated.";
CM_ SG_ 2046 APP_lPillarCamExtPitchCal "The calibration, pitch or yaw offset of a camera; raw 511 = signal not available (SNA)";
CM_ SG_ 2046 APP_lPillarCamExtYawCal "The calibration, pitch or yaw offset of a camera; raw 511 = signal not available (SNA)";
CM_ SG_ 2046 APP_lPillarCalibTime "Driver assistance computer (primary): l pillar calib time; raw 127 = signal not available (SNA)";
CM_ SG_ 2046 APP_lPillarCalibProgress "The percent progress of the left pillar camera calibration; raw 127 = signal not available (SNA)";
CM_ SG_ 2046 APP_lPillarCalibrated "Whether or not the left pillar camera is calibrated.";
CM_ SG_ 2046 APP_rPillarCamExtPitchCal "The calibration, pitch or yaw offset of a camera; raw 511 = signal not available (SNA)";
CM_ SG_ 2046 APP_rPillarCamExtYawCal "The calibration, pitch or yaw offset of a camera; raw 511 = signal not available (SNA)";
CM_ SG_ 2046 APP_rPillarCalibTime "Driver assistance computer (primary): r pillar calib time; raw 127 = signal not available (SNA)";
CM_ SG_ 2046 APP_rPillarCalibProgress "The percent progress of the right pillar camera calibration; raw 127 = signal not available (SNA)";
CM_ SG_ 2046 APP_rPillarCalibrated "Whether or not the right pillar camera is calibrated.";
CM_ SG_ 2046 APP_lRepeatCamExtPitchCal "The calibration, pitch or yaw offset of a camera; raw 511 = signal not available (SNA)";
CM_ SG_ 2046 APP_lRepeatCamExtYawCal "The calibration, pitch or yaw offset of a camera; raw 511 = signal not available (SNA)";
CM_ SG_ 2046 APP_lRepeatCalibTime "Driver assistance computer (primary): l repeat calib time; raw 127 = signal not available (SNA)";
CM_ SG_ 2046 APP_lRepeatCalibProgress "The percent progress of the left repeater camera calibration; raw 127 = signal not available (SNA)";
CM_ SG_ 2046 APP_lRepeatCalibrated "Whether or not the left repeater camera is calibrated.";
CM_ SG_ 2046 APP_rRepeatCamExtPitchCal "The calibration, pitch or yaw offset of a camera; raw 511 = signal not available (SNA)";
CM_ SG_ 2046 APP_rRepeatCamExtYawCal "The calibration, pitch or yaw offset of a camera; raw 511 = signal not available (SNA)";
CM_ SG_ 2046 APP_rRepeatCalibTime "Driver assistance computer (primary): r repeat calib time; raw 127 = signal not available (SNA)";
CM_ SG_ 2046 APP_rRepeatCalibProgress "The percent progress of the right repeater camera calibration; raw 127 = signal not available (SNA)";
CM_ SG_ 2046 APP_rRepeatCalibrated "Whether or not the right repeater camera is calibrated.";
CM_ SG_ 2046 APP_backupCamExtPitchCal "The calibration, pitch or yaw offset of a camera; raw 511 = signal not available (SNA)";
CM_ SG_ 2046 APP_backupCamExtYawCal "The calibration, pitch or yaw offset of a camera; raw 511 = signal not available (SNA)";
CM_ SG_ 2046 APP_backupCalibTime "Driver assistance computer (primary): backup calib time; raw 127 = signal not available (SNA)";
CM_ SG_ 2046 APP_backupCalibProgress "The percent progress of the backup calibration; raw 127 = signal not available (SNA)";
CM_ SG_ 2046 APP_backupCalibrated "Whether or not the backup camera is calibrated.";
CM_ BO_ 1018 "Driver assistance computer (primary) message: camera lux";
CM_ SG_ 1018 APP_mainCameraLUX "Amount of illuminance seen by the main camera; raw 255 = signal not available (SNA)";
CM_ SG_ 1018 APP_narrowCameraLUX "Driver assistance computer (primary): narrow camera LUX; raw 255 = signal not available (SNA)";
CM_ SG_ 1018 APP_fisheyeCameraLUX "Driver assistance computer (primary): fisheye camera LUX; raw 255 = signal not available (SNA)";
CM_ SG_ 1018 APP_lRepeatCameraLUX "Driver assistance computer (primary): l repeat camera LUX; raw 255 = signal not available (SNA)";
CM_ SG_ 1018 APP_rRepeatCameraLUX "Driver assistance computer (primary): r repeat camera LUX; raw 255 = signal not available (SNA)";
CM_ SG_ 1018 APP_lPillarCameraLUX "Driver assistance computer (primary): l pillar camera LUX; raw 255 = signal not available (SNA)";
CM_ SG_ 1018 APP_rPillarCameraLUX "Driver assistance computer (primary): r pillar camera LUX; raw 255 = signal not available (SNA)";
CM_ SG_ 1018 APP_backupCameraLUX "Driver assistance computer (primary): backup camera LUX; raw 255 = signal not available (SNA)";
CM_ BO_ 1040 "Driver assistance computer (primary) message: camera status";
CM_ SG_ 1040 APP_backupCameraFeedGood "Indicates if the backup camera stream is healthy.";
CM_ SG_ 1040 APP_backupCameraFrameRate "The backup camera frame rate.";
CM_ SG_ 1040 APP_cameraBlockedFrontMain "Indicates that a blockage was detected by the main forward camera.";
CM_ SG_ 1040 APP_cameraBlockedFrontFisheye "Indicates that a blockage was detected by the fisheye camera.";
CM_ SG_ 1040 APP_cameraBlockedFrontNarrow "Indicates that a blockage was detected by the narrow camera.";
CM_ SG_ 1040 APP_cameraBlockedLeftPillar "Indicates that a blockage was detected by the left pillar camera.";
CM_ SG_ 1040 APP_cameraBlockedLeftRepeater "Indicates that a blockage was detected by the left repeater camera.";
CM_ SG_ 1040 APP_cameraBlockedRightPillar "Indicates that a blockage was detected by the right pillar camera.";
CM_ SG_ 1040 APP_cameraBlockedRightRepeater "Indicates that a blockage was detected by the right repeater camera.";
CM_ SG_ 1040 APP_cameraBlockedBackup "Indicates that a blockage was detected by the backup camera.";
CM_ BO_ 1177 "Driver assistance computer (primary) message: camera temperatures";
CM_ SG_ 1177 APP_rRepeaterCameraTemperature "Driver assistance computer (primary): r repeater camera temperature";
CM_ SG_ 1177 APP_lRepeaterCameraTemperature "Driver assistance computer (primary): l repeater camera temperature";
CM_ BO_ 1043 "Driver assistance computer (primary) message: dash cam status";
CM_ SG_ 1043 APP_mainDashCamFeedGood "Indicates if the main dash cam stream is healthy.";
CM_ SG_ 1043 APP_mainDashCamFrameRate "The main dash cam frame rate.";
CM_ SG_ 1043 APP_lRepeatDashCamFeedGood "Indicates if the left repeater dash cam stream is healthy.";
CM_ SG_ 1043 APP_lRepeatDashCamFrameRate "The left repeater dash cam frame rate.";
CM_ SG_ 1043 APP_rRepeatDashCamFeedGood "Indicates if the right repeater dash cam stream is healthy.";
CM_ SG_ 1043 APP_rRepeatDashCamFrameRate "The right repeater dash cam frame rate.";
CM_ BO_ 603 "Driver assistance computer (primary) message: environment";
CM_ SG_ 603 APP_environmentRainy "Driver assistance computer (primary): environment rainy";
CM_ SG_ 603 APP_environmentSnowy "Driver assistance computer (primary): environment snowy";
CM_ BO_ 1061 "Driver assistance computer (primary) message: factory summon goal";
CM_ SG_ 1061 APP_factoryGoalLatitude "Driver assistance computer (primary): factory goal latitude";
CM_ SG_ 1061 APP_factoryGoalLongitude "Driver assistance computer (primary): factory goal longitude";
CM_ SG_ 1061 APP_factoryGoalSpeed "Driver assistance computer (primary): factory goal speed";
CM_ BO_ 843 "Driver assistance computer (primary) message: front park assist data";
CM_ SG_ 843 APP_frontLeftParkAssist "Driver assistance computer (primary): front left park assist; raw 255 = signal not available (SNA)";
CM_ SG_ 843 APP_frontLeftMiddleParkAssist "Driver assistance computer (primary): front left middle park assist; raw 255 = signal not available (SNA)";
CM_ SG_ 843 APP_frontMiddleParkAssist "Driver assistance computer (primary): front middle park assist; raw 255 = signal not available (SNA)";
CM_ SG_ 843 APP_frontRightMiddleParkAssist "Driver assistance computer (primary): front right middle park assist; raw 255 = signal not available (SNA)";
CM_ SG_ 843 APP_frontRightParkAssist "Driver assistance computer (primary): front right park assist; raw 255 = signal not available (SNA)";
CM_ SG_ 843 APP_parkAssistStatus "Driver assistance computer (primary): park assist status; raw 3 = signal not available (SNA)";
CM_ SG_ 843 APP_useParkDistancesFromAP "Driver assistance computer (primary): use park distances from AP";
CM_ BO_ 1353 "Driver assistance computer (primary) message: info";
CM_ SG_ 1353 APP_infoIndex "Driver assistance computer (primary): info index";
CM_ SG_ 1353 APP_buildType "Driver assistance computer (primary): build type";
CM_ BO_ 907 "Driver assistance computer (primary) message: rear park assist data";
CM_ SG_ 907 APP_rearLeftParkAssist "Driver assistance computer (primary): rear left park assist; raw 255 = signal not available (SNA)";
CM_ SG_ 907 APP_rearLeftMiddleParkAssist "Driver assistance computer (primary): rear left middle park assist; raw 255 = signal not available (SNA)";
CM_ SG_ 907 APP_rearMiddleParkAssist "Driver assistance computer (primary): rear middle park assist; raw 255 = signal not available (SNA)";
CM_ SG_ 907 APP_rearRightMiddleParkAssist "Driver assistance computer (primary): rear right middle park assist; raw 255 = signal not available (SNA)";
CM_ SG_ 907 APP_rearRightParkAssist "Driver assistance computer (primary): rear right park assist; raw 255 = signal not available (SNA)";
CM_ BO_ 601 "Driver assistance computer (primary) message: status";
CM_ SG_ 601 APP_watchdogState "State of system watchdog on ParkerB; raw 7 = signal not available (SNA)";
CM_ SG_ 601 APP_fusedState "Driver assistance computer (primary): fused state; raw 3 = signal not available (SNA)";
CM_ SG_ 601 APP_cameraHeaterRequest "Indicates if heater grid is active because of request from AP cameras.";
CM_ SG_ 601 APP_factorySummonStatus "Driver assistance computer (primary): factory summon status; raw 0 = signal not available (SNA)";
CM_ SG_ 601 APP_clipRecordingStatus "Driver assistance computer (primary): clip recording status";
CM_ SG_ 601 APP_allowApActivationWithBrake "Indicates whether Autopilot (AP) activation while brake pressed is allowed.";
CM_ SG_ 601 APP_summonUnavailableReason "The reason why smart summon is currently unavailable.";
CM_ SG_ 601 APP_fsdSuspendState "If FSD feature is suspended on this car; raw 3 = signal not available (SNA)";
CM_ SG_ 601 APP_fsdRevokeStrikeoutCount "Reports the number of strikeouts counted towards revoking Full Self-Driving (FSD) feature; raw 7 = signal not available (SNA)";
CM_ SG_ 601 APP_teslaVisionSupported "Whether autopilot can support tesla vision; raw 3 = signal not available (SNA)";
CM_ SG_ 601 APP_teslaVisionUnsupportedReason "Reason for vehicle not supporting tesla vision";
CM_ SG_ 601 APP_fsdRevokeCount "Reports the number of times the car has had Full Self-Driving (FSD) revoked; raw 7 = signal not available (SNA)";
CM_ SG_ 601 APP_excessiveAccelPedalWarning "Indicates that driver is using acceleration pedal continously and excessively";
CM_ SG_ 601 APP_unifiedObjectStackSupported "Whether autopilot can support unified objects stack for tesla vision; raw 3 = signal not available (SNA)";
CM_ SG_ 601 APP_unifiedObjsUnsupportedReason "Driver assistance computer (primary): unified objs unsupported reason";
CM_ SG_ 601 APP_DDAWSystemStatus "DDAW system status; raw 4 = signal not available (SNA)";
CM_ SG_ 601 APP_socOperatingMode "Operating Mode of the SOC";
CM_ SG_ 601 APP_summonVersionIdentifier "Driver assistance computer (primary): summon version identifier";
CM_ SG_ 601 APP_sentryState "Reports the Sentry mode state on Gen. 4 Hardware (HW4) and later vehicles; raw 6 = signal not available (SNA)";
CM_ SG_ 601 APP_autoparkVersionIdentifier "Driver assistance computer (primary): autopark version identifier";
CM_ SG_ 601 APP_setSpeedMode "Driver assistance computer (primary): set speed mode";
CM_ SG_ 601 APP_suspendResumeAvailable "Driver assistance computer (primary): suspend resume available";
CM_ SG_ 601 APP_statusCounter "Driver assistance computer (primary): status counter";
CM_ SG_ 601 APP_statusChecksum "Driver assistance computer (primary): status checksum";
CM_ BO_ 605 "Driver assistance computer (primary) message: traffic control";
CM_ SG_ 605 APP_tcFeatureState "The feature level state of stopping for traffic controls";
CM_ SG_ 605 APP_tcStateMachine "The traffic control state machine's internal control state.";
CM_ SG_ 605 APP_tcControlSource "The input data source for the traffic control object";
CM_ SG_ 605 APP_tcControlType "The specific type of traffic control, note not all are control worthy.";
CM_ SG_ 605 APP_tcControlDistance "The distance to the nearest critical traffic control object; raw 255 = signal not available (SNA)";
CM_ SG_ 605 APP_tcControlLightState "Driver assistance computer (primary): tc control light state";
CM_ SG_ 605 APP_tcContinuationReason "The reason the traffic control state machine entered the continue state.";
CM_ SG_ 605 APP_tcConfirmationType "The mechanism of how the driver confirmed the traffic control.";
CM_ SG_ 605 APP_tcWarningSuppressionReason "The suppression reason for the traffic control warning feature.";
CM_ SG_ 605 APP_tcUnavailableReason "The reason why the traffic control feature is currently unavailable.";
CM_ SG_ 605 APP_tcVisionLight "Whether or not the traffic light has a vision measurement.";
CM_ SG_ 605 APP_tcVisionSign "Whether or not the traffic sign has a vision measurement.";
CM_ SG_ 605 APP_tcVisionRoadMarking "Whether or not the road marking has a vision measurement.";
CM_ SG_ 605 APP_tcVisionLine "Whether or not the traffic control line has a vision measurement.";
CM_ BO_ 2045 "Driver assistance computer (primary) message: vision ocs status";
CM_ SG_ 2045 APP_visionOcsStatusChecksum "Driver assistance computer (primary): vision ocs status checksum";
CM_ SG_ 2045 APP_visionOcsStateRaw "Reports classification state raw signal for front passenger from interior camera.";
CM_ SG_ 2045 APP_visionOcsEmptyProbRaw "Driver assistance computer (primary): vision ocs empty prob raw; raw 255 = signal not available (SNA)";
CM_ SG_ 2045 APP_visionOcsChildProbRaw "Driver assistance computer (primary): vision ocs child prob raw; raw 255 = signal not available (SNA)";
CM_ SG_ 2045 APP_visionOcsAdultProbRaw "Driver assistance computer (primary): vision ocs adult prob raw; raw 255 = signal not available (SNA)";
CM_ SG_ 2045 APP_visionOcsFrontPasClsVisionSt "Reports classification state of front passenger seat after Bayesian filter.";
CM_ SG_ 2045 APP_visionOcsStatusCounter "Driver assistance computer (primary): vision ocs status counter";
CM_ BO_ 809 "Driver assistance computer (primary) message: warning matrix0";
CM_ SG_ 809 APP_w001_DEPRECATED "Driver assistance computer (primary): w001 DEPRECATED";
CM_ SG_ 809 APP_w002_ldwDisabled "Driver assistance computer (primary): w002 ldw disabled";
CM_ SG_ 809 APP_w003_isaDisabled "Driver assistance computer (primary): w003 isa disabled";
CM_ SG_ 809 APP_w004_accDisabled "Driver assistance computer (primary): w004 acc disabled";
CM_ SG_ 809 APP_w005_fcwCancelled "Driver assistance computer (primary): w005 fcw cancelled";
CM_ SG_ 809 APP_w006_aebCancelled "Driver assistance computer (primary): w006 aeb cancelled";
CM_ SG_ 809 APP_w007_ahlbDisabled "Driver assistance computer (primary): w007 ahlb disabled";
CM_ SG_ 809 APP_w008_parkDisabled "Driver assistance computer (primary): w008 park disabled";
CM_ SG_ 809 APP_w009_aebFault "Driver assistance computer (primary): w009 aeb fault";
CM_ SG_ 809 APP_w010_radcCalibIssue "Driver assistance computer (primary): w010 radc calib issue";
CM_ SG_ 809 APP_w011_scaEvent "Driver assistance computer (primary): w011 sca event";
CM_ SG_ 809 APP_w012_Cam_BootFailure "Driver assistance computer (primary): w012 cam boot failure";
CM_ SG_ 809 APP_w013_Cam_Watchdog "Driver assistance computer (primary): w013 cam watchdog";
CM_ SG_ 809 APP_w014_swAssert "Driver assistance computer (primary): w014 sw assert";
CM_ SG_ 809 APP_w015_Camera_Failsafes "Driver assistance computer (primary): w015 camera failsafes";
CM_ SG_ 809 APP_w016_aeb_e_event "Driver assistance computer (primary): w016 aeb e event";
CM_ SG_ 809 APP_w017_Cam_Msg_MIA "Driver assistance computer (primary): w017 cam msg MIA";
CM_ SG_ 809 APP_w018_ECU_Power_Issue "Driver assistance computer (primary): w018 ECU power issue";
CM_ SG_ 809 APP_w019_ECU_Stack_Overflow "Driver assistance computer (primary): w019 ECU stack overflow";
CM_ SG_ 809 APP_w020_ECU_checkstopError "Driver assistance computer (primary): w020 ECU checkstop error";
CM_ SG_ 809 APP_w021_ECU_Temperature_Issue "Driver assistance computer (primary): w021 ECU temperature issue";
CM_ SG_ 809 APP_w022_ECU_EEPROM_Failure "Driver assistance computer (primary): w022 ECU EEPROM failure";
CM_ SG_ 809 APP_w023_ECU_Cam_Statemismatc "Driver assistance computer (primary): w023 ECU cam statemismatc";
CM_ SG_ 809 APP_w024_ECU_Watchdog_Reset "Driver assistance computer (primary): w024 ECU watchdog reset";
CM_ SG_ 809 APP_w025_LC_Steering_Override "Driver assistance computer (primary): w025 LC steering override";
CM_ SG_ 809 APP_w026_ECU_timingIssue "Driver assistance computer (primary): w026 ECU timing issue";
CM_ SG_ 809 APP_w027_ECU_Reset_Fault "Driver assistance computer (primary): w027 ECU reset fault";
CM_ SG_ 809 APP_w028_spi_rx_error "Driver assistance computer (primary): w028 spi rx error";
CM_ SG_ 809 APP_w029_spi_tx_error "Driver assistance computer (primary): w029 spi tx error";
CM_ SG_ 809 APP_w030_Heater_Issue "Driver assistance computer (primary): w030 heater issue";
CM_ SG_ 809 APP_w031_canRxError "Driver assistance computer (primary): w031 can rx error";
CM_ SG_ 809 APP_w032_canTxError "Driver assistance computer (primary): w032 can tx error";
CM_ SG_ 809 APP_w033_gtwMia "Driver assistance computer (primary): w033 gtw mia";
CM_ SG_ 809 APP_w034_sccmMia "Driver assistance computer (primary): w034 sccm mia";
CM_ SG_ 809 APP_w035_espMia "Driver assistance computer (primary): w035 esp mia";
CM_ SG_ 809 APP_w036_bdyMia "Driver assistance computer (primary): w036 bdy mia";
CM_ SG_ 809 APP_w037_camTacIssue "Driver assistance computer (primary): w037 cam tac issue";
CM_ SG_ 809 APP_w038_camFailure "Driver assistance computer (primary): w038 cam failure";
CM_ SG_ 809 APP_w039_sdm_rcm_Mia "Driver assistance computer (primary): w039 sdm rcm mia";
CM_ SG_ 809 APP_w040_autopilotAngleSaturated "Driver assistance computer (primary): w040 autopilot angle saturated";
CM_ SG_ 809 APP_w041_autopilotRateSaturated "Driver assistance computer (primary): w041 autopilot rate saturated";
CM_ SG_ 809 APP_w042_autopilotAborting "Driver assistance computer (primary): w042 autopilot aborting";
CM_ SG_ 809 APP_w043_camLongRunTime "Driver assistance computer (primary): w043 cam long run time";
CM_ SG_ 809 APP_w044_appMobileyeFailure "Driver assistance computer (primary): w044 app mobileye failure";
CM_ SG_ 809 APP_w045_radMia "Driver assistance computer (primary): w045 rad mia";
CM_ SG_ 809 APP_w046_eepromRecordAbsent "Driver assistance computer (primary): w046 eeprom record absent";
CM_ SG_ 809 APP_w047_edrEvent "Driver assistance computer (primary): w047 edr event";
CM_ SG_ 809 APP_w048_APP_Features_Disabled "Driver assistance computer (primary): w048 APP features disabled";
CM_ SG_ 809 APP_w049_eyeqVersionMismatch "Driver assistance computer (primary): w049 eyeq version mismatch";
CM_ SG_ 809 APP_w050_aeb_event "Driver assistance computer (primary): w050 aeb event";
CM_ SG_ 809 APP_w051_radcEcuIssue "Driver assistance computer (primary): w051 radc ecu issue";
CM_ SG_ 809 APP_w052_radcSensorIssue "Driver assistance computer (primary): w052 radc sensor issue";
CM_ SG_ 809 APP_w053_radcCommIssue "Driver assistance computer (primary): w053 radc comm issue";
CM_ SG_ 809 APP_w054_camAutofix "Driver assistance computer (primary): w054 cam autofix";
CM_ SG_ 809 APP_w055_radcVersionMismatch "Driver assistance computer (primary): w055 radc version mismatch";
CM_ SG_ 809 APP_w056_diMia "Driver assistance computer (primary): w056 di mia";
CM_ SG_ 809 APP_w057_mcuMia "Driver assistance computer (primary): w057 mcu mia";
CM_ SG_ 809 APP_w058_epbMia "Driver assistance computer (primary): w058 epb mia";
CM_ SG_ 809 APP_w059_parkMia "Driver assistance computer (primary): w059 park mia";
CM_ SG_ 809 APP_w060_fcw_event "Driver assistance computer (primary): w060 fcw event";
CM_ SG_ 809 APP_w061_airSuspensionMia "Driver assistance computer (primary): w061 air suspension mia";
CM_ SG_ 809 APP_w062_radcAlignment "Driver assistance computer (primary): w062 radc alignment";
CM_ SG_ 809 APP_w063_parkVersionMismatch "Driver assistance computer (primary): w063 park version mismatch";
CM_ SG_ 809 APP_w064_epasMia "Driver assistance computer (primary): w064 epas mia";
BA_DEF_ BO_ "GenMsgCycleTime" INT 0 3600000;
BA_DEF_ BO_ "GenMsgSendType" ENUM "Cyclic","NotUsed","NotUsed","NotUsed","NotUsed","NotUsed","NotUsed","IfActive","NoMsgSendType","NotUsed";
BA_DEF_ BO_ "VFrameFormat" ENUM "StandardCAN","ExtendedCAN","reserved","J1939PG","reserved","reserved","reserved","reserved","reserved","reserved","reserved","reserved","reserved","reserved","StandardCAN_FD","ExtendedCAN_FD";
BA_DEF_ BO_ "CANFD_BRS" ENUM "0","1";
BA_DEF_ SG_ "GenSigSNA" STRING;
BA_DEF_ SG_ "SystemSignalLongSymbol" STRING;
BA_DEF_ SG_ "Confidence" ENUM "validated","plausible","layout-only","contradicted";
BA_DEF_DEF_ "GenMsgCycleTime" 0;
BA_DEF_DEF_ "GenMsgSendType" "NoMsgSendType";
BA_DEF_DEF_ "VFrameFormat" "StandardCAN";
BA_DEF_DEF_ "CANFD_BRS" "1";
BA_DEF_DEF_ "GenSigSNA" "";
BA_DEF_DEF_ "SystemSignalLongSymbol" "";
BA_DEF_DEF_ "Confidence" "layout-only";
BA_ "GenMsgCycleTime" BO_ 1045 500;
BA_ "GenMsgSendType" BO_ 1045 0;
BA_ "GenMsgCycleTime" BO_ 1020 1000;
BA_ "GenMsgSendType" BO_ 1020 0;
BA_ "GenMsgCycleTime" BO_ 2046 1000;
BA_ "GenMsgSendType" BO_ 2046 0;
BA_ "GenMsgCycleTime" BO_ 1018 500;
BA_ "GenMsgSendType" BO_ 1018 0;
BA_ "GenMsgCycleTime" BO_ 1040 500;
BA_ "GenMsgSendType" BO_ 1040 0;
BA_ "GenMsgCycleTime" BO_ 1177 1000;
BA_ "GenMsgSendType" BO_ 1177 0;
BA_ "GenMsgCycleTime" BO_ 1043 500;
BA_ "GenMsgSendType" BO_ 1043 0;
BA_ "GenMsgCycleTime" BO_ 603 1000;
BA_ "GenMsgSendType" BO_ 603 0;
BA_ "GenMsgCycleTime" BO_ 1061 1000;
BA_ "GenMsgSendType" BO_ 1061 0;
BA_ "GenMsgCycleTime" BO_ 843 100;
BA_ "GenMsgSendType" BO_ 843 0;
BA_ "GenMsgCycleTime" BO_ 1353 1000;
BA_ "GenMsgSendType" BO_ 1353 0;
BA_ "GenMsgCycleTime" BO_ 907 100;
BA_ "GenMsgSendType" BO_ 907 0;
BA_ "GenMsgCycleTime" BO_ 601 100;
BA_ "GenMsgSendType" BO_ 601 0;
BA_ "GenMsgCycleTime" BO_ 605 500;
BA_ "GenMsgSendType" BO_ 605 0;
BA_ "GenMsgCycleTime" BO_ 2045 100;
BA_ "GenMsgSendType" BO_ 2045 0;
BA_ "GenMsgCycleTime" BO_ 809 1000;
BA_ "GenMsgSendType" BO_ 809 0;
BA_ "Confidence" SG_ 1513 APP_sw188_minTemperature 1;
BA_ "GenSigSNA" SG_ 1513 APP_sw188_minTemperature "255";
BA_ "Confidence" SG_ 1513 APP_sw188_maxTemperature 1;
BA_ "GenSigSNA" SG_ 1513 APP_sw188_maxTemperature "255";
BA_ "Confidence" SG_ 1513 APP_sw189_exitStatus 1;
BA_ "Confidence" SG_ 1513 APP_sw189_tempMonitorFailure 1;
BA_ "Confidence" SG_ 1513 APP_sw189_imagerHeartbeat 1;
BA_ "GenSigSNA" SG_ 1513 APP_sw189_imagerHeartbeat "3";
BA_ "Confidence" SG_ 1513 APP_sw189_serializerCrcErrCount 1;
BA_ "GenSigSNA" SG_ 1513 APP_sw189_serializerCrcErrCount "255";
BA_ "Confidence" SG_ 1513 APP_sw189_currentTemperature 1;
BA_ "GenSigSNA" SG_ 1513 APP_sw189_currentTemperature "255";
BA_ "Confidence" SG_ 1513 APP_sw189_minTemperature 1;
BA_ "GenSigSNA" SG_ 1513 APP_sw189_minTemperature "255";
BA_ "Confidence" SG_ 1513 APP_sw189_maxTemperature 1;
BA_ "GenSigSNA" SG_ 1513 APP_sw189_maxTemperature "255";
BA_ "Confidence" SG_ 1513 APP_sw190_exitStatus 1;
BA_ "Confidence" SG_ 1513 APP_sw190_tempMonitorFailure 1;
BA_ "Confidence" SG_ 1513 APP_sw190_imagerHeartbeat 1;
BA_ "GenSigSNA" SG_ 1513 APP_sw190_imagerHeartbeat "3";
BA_ "Confidence" SG_ 1513 APP_sw190_serializerCrcErrCount 1;
BA_ "GenSigSNA" SG_ 1513 APP_sw190_serializerCrcErrCount "255";
BA_ "Confidence" SG_ 1513 APP_sw190_currentTemperature 1;
BA_ "GenSigSNA" SG_ 1513 APP_sw190_currentTemperature "255";
BA_ "Confidence" SG_ 1513 APP_sw190_minTemperature 1;
BA_ "GenSigSNA" SG_ 1513 APP_sw190_minTemperature "255";
BA_ "Confidence" SG_ 1513 APP_sw190_maxTemperature 1;
BA_ "GenSigSNA" SG_ 1513 APP_sw190_maxTemperature "255";
BA_ "Confidence" SG_ 1513 APP_sw191_abortReason 1;
BA_ "Confidence" SG_ 1513 APP_sw191_handsOnState 1;
BA_ "GenSigSNA" SG_ 1513 APP_sw191_handsOnState "15";
BA_ "Confidence" SG_ 1513 APP_sw191_cruiseState 1;
BA_ "Confidence" SG_ 1513 APP_sw191_epasErrorCode 1;
BA_ "GenSigSNA" SG_ 1513 APP_sw191_epasErrorCode "15";
BA_ "Confidence" SG_ 1513 APP_sw191_viewRange 1;
BA_ "Confidence" SG_ 1513 APP_sw191_roadClass 1;
BA_ "GenSigSNA" SG_ 1513 APP_sw191_roadClass "0";
BA_ "Confidence" SG_ 1513 APP_sw191_referenceHealth 1;
BA_ "Confidence" SG_ 1513 APP_sw191_solverHealth 1;
BA_ "Confidence" SG_ 1513 APP_sw191_roadEstHealth 1;
BA_ "Confidence" SG_ 1513 APP_sw191_roadEstMode 1;
BA_ "Confidence" SG_ 1513 APP_sw191_radarFault 1;
BA_ "Confidence" SG_ 1513 APP_sw191_radarBlind 1;
BA_ "Confidence" SG_ 1513 APP_sw191_cameraFailsafes 1;
BA_ "Confidence" SG_ 1513 APP_sw192_speakerFailureType 1;
BA_ "Confidence" SG_ 1513 APP_sw192_chassisType 1;
BA_ "Confidence" SG_ 1513 APP_sw192_hardwareType 1;
BA_ "Confidence" SG_ 1513 APP_sw194_leadAx 1;
BA_ "Confidence" SG_ 1513 APP_sw194_leadDx 1;
BA_ "Confidence" SG_ 1513 APP_sw194_leadVx 1;
BA_ "Confidence" SG_ 1513 APP_sw194_reasonForHold 1;
BA_ "GenSigSNA" SG_ 1513 APP_sw194_reasonForHold "15";
BA_ "Confidence" SG_ 1513 APP_sw195_vehicleSpeed 1;
BA_ "Confidence" SG_ 1513 APP_sw199_abortCodeDas 1;
BA_ "Confidence" SG_ 1513 APP_sw199_abortCodePARK 1;
BA_ "GenSigSNA" SG_ 1513 APP_sw199_abortCodePARK "31";
BA_ "Confidence" SG_ 1513 APP_sw199_currentSTW 1;
BA_ "Confidence" SG_ 1513 APP_sw199_currentSpeed 1;
BA_ "Confidence" SG_ 1513 APP_sw199_maxSpeed 1;
BA_ "Confidence" SG_ 1513 APP_sw203_controlType 1;
BA_ "GenSigSNA" SG_ 1513 APP_sw203_controlType "15";
BA_ "Confidence" SG_ 1513 APP_sw203_slotSizeX 1;
BA_ "Confidence" SG_ 1513 APP_sw203_slotSizeY 1;
BA_ "Confidence" SG_ 1513 APP_sw203_startDistance 1;
BA_ "Confidence" SG_ 1513 APP_sw203_vehicleSkew 1;
BA_ "Confidence" SG_ 1513 APP_sw204_frLeft 1;
BA_ "Confidence" SG_ 1513 APP_sw204_frLeftMiddle 1;
BA_ "Confidence" SG_ 1513 APP_sw204_frMiddle 1;
BA_ "Confidence" SG_ 1513 APP_sw204_frRight 1;
BA_ "Confidence" SG_ 1513 APP_sw204_frRightMiddle 1;
BA_ "Confidence" SG_ 1513 APP_sw204_maxSpeed 1;
BA_ "Confidence" SG_ 1513 APP_sw205_oocDistance 1;
BA_ "Confidence" SG_ 1513 APP_sw205_rrLeft 1;
BA_ "Confidence" SG_ 1513 APP_sw205_rrLeftMiddle 1;
BA_ "Confidence" SG_ 1513 APP_sw205_rrMiddle 1;
BA_ "Confidence" SG_ 1513 APP_sw205_rrRight 1;
BA_ "Confidence" SG_ 1513 APP_sw205_rrRightMiddle 1;
BA_ "Confidence" SG_ 1513 APP_sw207_lcUnavailableReason 1;
BA_ "Confidence" SG_ 1513 APP_sw213_autopilotIntState 1;
BA_ "Confidence" SG_ 1513 APP_sw213_endSpeed 1;
BA_ "Confidence" SG_ 1513 APP_sw213_startSpeed 1;
BA_ "Confidence" SG_ 1513 APP_sw213_apIntStateAtTrigger 1;
BA_ "Confidence" SG_ 1513 APP_sw213_takeoverDuration 1;
BA_ "Confidence" SG_ 1513 APP_sw218_cipvDist 1;
BA_ "Confidence" SG_ 1513 APP_sw218_pedalPosition 1;
BA_ "Confidence" SG_ 1513 APP_sw219_vehicleSpeed 1;
BA_ "Confidence" SG_ 1513 APP_sw260_target_dx 1;
BA_ "Confidence" SG_ 1513 APP_sw260_target_vx 1;
BA_ "Confidence" SG_ 1513 APP_sw260_target_ax 1;
BA_ "Confidence" SG_ 1513 APP_sw260_ego_speed 1;
BA_ "Confidence" SG_ 1513 APP_sw260_driver_reaction_time 1;
BA_ "Confidence" SG_ 1513 APP_sw260_driver_reqd_accel 1;
BA_ "Confidence" SG_ 1513 APP_sw260_user_sensitivity 1;
BA_ "GenSigSNA" SG_ 1513 APP_sw260_user_sensitivity "3";
BA_ "Confidence" SG_ 1513 APP_sw263_markerType 1;
BA_ "Confidence" SG_ 1513 APP_sw263_side 1;
BA_ "Confidence" SG_ 1513 APP_sw263_speed 1;
BA_ "Confidence" SG_ 1513 APP_sw263_laneWidth 1;
BA_ "Confidence" SG_ 1513 APP_sw263_lssAbortReason 1;
BA_ "Confidence" SG_ 1513 APP_sw264_faultReason 1;
BA_ "Confidence" SG_ 1513 APP_sw265_surroundCameraStatus 1;
BA_ "Confidence" SG_ 1513 APP_sw265_unavailableReason 1;
BA_ "Confidence" SG_ 1513 APP_sw266_lPillarStreamStatus 1;
BA_ "Confidence" SG_ 1513 APP_sw266_rPillarStreamStatus 1;
BA_ "Confidence" SG_ 1513 APP_sw266_lRepeaterStreamStatus 1;
BA_ "Confidence" SG_ 1513 APP_sw266_rRepeaterStreamStatus 1;
BA_ "Confidence" SG_ 1513 APP_sw266_backupStreamStatus 1;
BA_ "Confidence" SG_ 1513 APP_sw269_emergencyLaneKeep 1;
BA_ "GenSigSNA" SG_ 1513 APP_sw269_emergencyLaneKeep "31";
BA_ "Confidence" SG_ 1513 APP_sw269_laneKeepAssist 1;
BA_ "GenSigSNA" SG_ 1513 APP_sw269_laneKeepAssist "31";
BA_ "Confidence" SG_ 1513 APP_sw269_blindspot 1;
BA_ "GenSigSNA" SG_ 1513 APP_sw269_blindspot "31";
BA_ "Confidence" SG_ 1513 APP_sw269_laneDepartureWarning 1;
BA_ "GenSigSNA" SG_ 1513 APP_sw269_laneDepartureWarning "31";
BA_ "Confidence" SG_ 1513 APP_sw270_emergencyLaneKeep 1;
BA_ "GenSigSNA" SG_ 1513 APP_sw270_emergencyLaneKeep "31";
BA_ "Confidence" SG_ 1513 APP_sw270_laneKeepAssist 1;
BA_ "GenSigSNA" SG_ 1513 APP_sw270_laneKeepAssist "31";
BA_ "Confidence" SG_ 1513 APP_sw270_blindspot 1;
BA_ "GenSigSNA" SG_ 1513 APP_sw270_blindspot "31";
BA_ "Confidence" SG_ 1513 APP_sw270_laneDepartureWarning 1;
BA_ "GenSigSNA" SG_ 1513 APP_sw270_laneDepartureWarning "31";
BA_ "Confidence" SG_ 1513 APP_sw271_abortReason 1;
BA_ "Confidence" SG_ 1513 APP_sw271_direction 1;
BA_ "Confidence" SG_ 1513 APP_sw271_progress 1;
BA_ "Confidence" SG_ 1513 APP_sw271_egoSpeed 1;
BA_ "Confidence" SG_ 1513 APP_sw272_unavailableReason 1;
BA_ "Confidence" SG_ 1513 APP_sw273_eventType 1;
BA_ "Confidence" SG_ 1513 APP_sw273_collisionType 1;
BA_ "Confidence" SG_ 1513 APP_sw273_side 1;
BA_ "Confidence" SG_ 1513 APP_sw273_timeToCollision 1;
BA_ "Confidence" SG_ 1513 APP_sw273_lngDistanceToVehicle 1;
BA_ "Confidence" SG_ 1513 APP_sw273_latDistanceToVehicle 1;
BA_ "Confidence" SG_ 1513 APP_sw273_timeToLaneExit 1;
BA_ "Confidence" SG_ 1513 APP_sw273_distanceToLaneExit 1;
BA_ "Confidence" SG_ 1513 APP_sw283_appAbortReason 1;
BA_ "Confidence" SG_ 1513 APP_sw283_apsAbortReason 1;
BA_ "Confidence" SG_ 1513 APP_sw283_distanceTravelled 1;
BA_ "Confidence" SG_ 1513 APP_sw283_phoneDistance 1;
BA_ "Confidence" SG_ 1513 APP_sw283_goalDistance 1;
BA_ "Confidence" SG_ 1513 APP_sw283_mainCam 1;
BA_ "Confidence" SG_ 1513 APP_sw283_narrowCam 1;
BA_ "Confidence" SG_ 1513 APP_sw283_fisheyeCam 1;
BA_ "Confidence" SG_ 1513 APP_sw283_leftRepeaterCam 1;
BA_ "Confidence" SG_ 1513 APP_sw283_rightRepeaterCam 1;
BA_ "Confidence" SG_ 1513 APP_sw283_leftPillarCam 1;
BA_ "Confidence" SG_ 1513 APP_sw283_rightPillarCam 1;
BA_ "Confidence" SG_ 1513 APP_sw283_bucCam 1;
BA_ "Confidence" SG_ 1513 APP_sw288_dist_to_stop 1;
BA_ "Confidence" SG_ 1513 APP_sw288_ego_speed 1;
BA_ "Confidence" SG_ 1513 APP_sw288_ego_acceleration 1;
BA_ "Confidence" SG_ 1513 APP_sw291_dist_to_stop 1;
BA_ "Confidence" SG_ 1513 APP_sw291_ego_speed 1;
BA_ "Confidence" SG_ 1513 APP_sw291_ego_acceleration 1;
BA_ "Confidence" SG_ 1513 APP_sw293_clockFrequencyDrift 1;
BA_ "Confidence" SG_ 1513 APP_sw294_clockFrequencyDrift 1;
BA_ "Confidence" SG_ 1513 APP_sw295_clockFrequencyDrift 1;
BA_ "Confidence" SG_ 1513 APP_sw296_clockFrequencyDrift 1;
BA_ "Confidence" SG_ 1513 APP_sw297_clockFrequencyDrift 1;
BA_ "Confidence" SG_ 1513 APP_sw298_clockFrequencyDrift 1;
BA_ "Confidence" SG_ 1513 APP_sw299_clockFrequencyDrift 1;
BA_ "Confidence" SG_ 1513 APP_sw300_clockFrequencyDrift 1;
BA_ "Confidence" SG_ 1513 APP_sw301_clockFrequencyDrift 1;
BA_ "Confidence" SG_ 1513 APP_sw323_confidence 1;
BA_ "Confidence" SG_ 1513 APP_sw323_distance 1;
BA_ "Confidence" SG_ 1513 APP_sw323_ttc 1;
BA_ "Confidence" SG_ 1513 APP_sw325_taskId 1;
BA_ "Confidence" SG_ 1513 APP_sw325_issue 1;
BA_ "Confidence" SG_ 1513 APP_sw329_cipvSysReqAccel 1;
BA_ "Confidence" SG_ 1513 APP_sw329_leftLaneReqAccel 1;
BA_ "Confidence" SG_ 1513 APP_sw329_rightLaneReqAccel 1;
BA_ "Confidence" SG_ 1513 APP_sw329_leftLaneChngBehStatus 1;
BA_ "Confidence" SG_ 1513 APP_sw329_rightLaneChngBehStatus 1;
BA_ "Confidence" SG_ 1513 APP_sw355_quad1FailureRate 1;
BA_ "Confidence" SG_ 1513 APP_sw355_quad2FailureRate 1;
BA_ "Confidence" SG_ 1513 APP_sw355_quad3FailureRate 1;
BA_ "SystemSignalLongSymbol" SG_ 1513 APP_sw357_cabinCameraFailsafeAct "APP_sw357_cabinCameraFailsafeActive";
BA_ "SystemSignalLongSymbol" SG_ 1513 APP_sw357_invalidDrowsinessPredi "APP_sw357_invalidDrowsinessPredictions";
BA_ "SystemSignalLongSymbol" SG_ 1513 APP_sw357_invalidSccmSteeringAng "APP_sw357_invalidSccmSteeringAngle";
BA_ "SystemSignalLongSymbol" SG_ 1513 APP_sw357_invalidSccmSteeri_0001 "APP_sw357_invalidSccmSteeringAngleRate";
BA_ "SystemSignalLongSymbol" SG_ 1513 APP_sw357_poorFrontCameraVisibil "APP_sw357_poorFrontCameraVisibility";
BA_ "SystemSignalLongSymbol" SG_ 1513 APP_sw357_electricalFaultForMain "APP_sw357_electricalFaultForMainCam";
BA_ "SystemSignalLongSymbol" SG_ 1513 APP_sw357_electricalFaultForCabi "APP_sw357_electricalFaultForCabinCam";
BA_ "SystemSignalLongSymbol" SG_ 1513 APP_sw357_mainCameraFailsafeActi "APP_sw357_mainCameraFailsafeActive";
BA_ "SystemSignalLongSymbol" SG_ 1513 APP_sw357_electricalFaultForFish "APP_sw357_electricalFaultForFisheyeCam";
BA_ "SystemSignalLongSymbol" SG_ 1513 APP_sw357_fisheyeCameraFailsafeA "APP_sw357_fisheyeCameraFailsafeActive";
BA_ "SystemSignalLongSymbol" SG_ 1513 APP_sw358_mainCameraStreamUnavai "APP_sw358_mainCameraStreamUnavailable";
BA_ "SystemSignalLongSymbol" SG_ 1513 APP_sw358_fisheyeCameraStreamUna "APP_sw358_fisheyeCameraStreamUnavailable";
BA_ "Confidence" SG_ 1513 APP_sw362_fasciaCamDeserFault 1;
BA_ "Confidence" SG_ 1513 APP_sw362_fasciaCamSensorFault 1;
BA_ "Confidence" SG_ 1513 APP_sw362_fasciaCamSerFault 1;
BA_ "Confidence" SG_ 1513 APP_sw363_exitStatus 1;
BA_ "Confidence" SG_ 1513 APP_sw363_tempMonitorFailure 1;
BA_ "Confidence" SG_ 1513 APP_sw363_imagerHeartbeat 1;
BA_ "GenSigSNA" SG_ 1513 APP_sw363_imagerHeartbeat "3";
BA_ "Confidence" SG_ 1513 APP_sw363_serializerCrcErrCount 1;
BA_ "GenSigSNA" SG_ 1513 APP_sw363_serializerCrcErrCount "255";
BA_ "Confidence" SG_ 1513 APP_sw363_currentTemperature 1;
BA_ "GenSigSNA" SG_ 1513 APP_sw363_currentTemperature "255";
BA_ "Confidence" SG_ 1513 APP_sw363_minTemperature 1;
BA_ "GenSigSNA" SG_ 1513 APP_sw363_minTemperature "255";
BA_ "Confidence" SG_ 1513 APP_sw363_maxTemperature 1;
BA_ "GenSigSNA" SG_ 1513 APP_sw363_maxTemperature "255";
BA_ "Confidence" SG_ 1513 APP_sw364_detectedColorFilter 1;
BA_ "Confidence" SG_ 1513 APP_sw364_expectedColorFilter 1;
BA_ "Confidence" SG_ 1513 APP_sw364_detectedPosition 1;
BA_ "Confidence" SG_ 1513 APP_sw366_clockFrequencyDrift 1;
BA_ "Confidence" SG_ 1045 APP_backupDashCamFeedGood 1;
BA_ "Confidence" SG_ 1045 APP_backupDashCamFrameRate 1;
BA_ "Confidence" SG_ 1020 APP_decisionTemperature 1;
BA_ "Confidence" SG_ 1020 APP_pascalTemperature 1;
BA_ "Confidence" SG_ 1020 APP_parkerATemperature 1;
BA_ "Confidence" SG_ 1020 APP_parkerBTemperature 1;
BA_ "Confidence" SG_ 1020 APP_pascalExtTemperature 1;
BA_ "Confidence" SG_ 1020 APP_parkerExtTemperature 1;
BA_ "Confidence" SG_ 1020 APP_pascalHeaterDecision 1;
BA_ "Confidence" SG_ 2046 APP_cameraPosition 1;
BA_ "Confidence" SG_ 2046 APP_mainCamExtPitchCal 1;
BA_ "GenSigSNA" SG_ 2046 APP_mainCamExtPitchCal "511";
BA_ "Confidence" SG_ 2046 APP_mainCamExtYawCal 1;
BA_ "GenSigSNA" SG_ 2046 APP_mainCamExtYawCal "511";
BA_ "Confidence" SG_ 2046 APP_mainCalibTime 1;
BA_ "GenSigSNA" SG_ 2046 APP_mainCalibTime "127";
BA_ "Confidence" SG_ 2046 APP_mainCalibProgress 1;
BA_ "GenSigSNA" SG_ 2046 APP_mainCalibProgress "127";
BA_ "Confidence" SG_ 2046 APP_mainCalibrated 1;
BA_ "Confidence" SG_ 2046 APP_narrowCamExtPitchCal 1;
BA_ "GenSigSNA" SG_ 2046 APP_narrowCamExtPitchCal "511";
BA_ "Confidence" SG_ 2046 APP_narrowCamExtYawCal 1;
BA_ "GenSigSNA" SG_ 2046 APP_narrowCamExtYawCal "511";
BA_ "Confidence" SG_ 2046 APP_narrowCalibTime 1;
BA_ "GenSigSNA" SG_ 2046 APP_narrowCalibTime "127";
BA_ "Confidence" SG_ 2046 APP_narrowCalibProgress 1;
BA_ "GenSigSNA" SG_ 2046 APP_narrowCalibProgress "127";
BA_ "Confidence" SG_ 2046 APP_narrowCalibrated 1;
BA_ "Confidence" SG_ 2046 APP_fisheyeCamExtPitchCal 1;
BA_ "GenSigSNA" SG_ 2046 APP_fisheyeCamExtPitchCal "511";
BA_ "Confidence" SG_ 2046 APP_fisheyeCamExtYawCal 1;
BA_ "GenSigSNA" SG_ 2046 APP_fisheyeCamExtYawCal "511";
BA_ "Confidence" SG_ 2046 APP_fisheyeCalibTime 1;
BA_ "GenSigSNA" SG_ 2046 APP_fisheyeCalibTime "127";
BA_ "Confidence" SG_ 2046 APP_fisheyeCalibProgress 1;
BA_ "GenSigSNA" SG_ 2046 APP_fisheyeCalibProgress "127";
BA_ "Confidence" SG_ 2046 APP_fisheyeCalibrated 1;
BA_ "Confidence" SG_ 2046 APP_lPillarCamExtPitchCal 1;
BA_ "GenSigSNA" SG_ 2046 APP_lPillarCamExtPitchCal "511";
BA_ "Confidence" SG_ 2046 APP_lPillarCamExtYawCal 1;
BA_ "GenSigSNA" SG_ 2046 APP_lPillarCamExtYawCal "511";
BA_ "Confidence" SG_ 2046 APP_lPillarCalibTime 1;
BA_ "GenSigSNA" SG_ 2046 APP_lPillarCalibTime "127";
BA_ "Confidence" SG_ 2046 APP_lPillarCalibProgress 1;
BA_ "GenSigSNA" SG_ 2046 APP_lPillarCalibProgress "127";
BA_ "Confidence" SG_ 2046 APP_lPillarCalibrated 1;
BA_ "Confidence" SG_ 2046 APP_rPillarCamExtPitchCal 1;
BA_ "GenSigSNA" SG_ 2046 APP_rPillarCamExtPitchCal "511";
BA_ "Confidence" SG_ 2046 APP_rPillarCamExtYawCal 1;
BA_ "GenSigSNA" SG_ 2046 APP_rPillarCamExtYawCal "511";
BA_ "Confidence" SG_ 2046 APP_rPillarCalibTime 1;
BA_ "GenSigSNA" SG_ 2046 APP_rPillarCalibTime "127";
BA_ "Confidence" SG_ 2046 APP_rPillarCalibProgress 1;
BA_ "GenSigSNA" SG_ 2046 APP_rPillarCalibProgress "127";
BA_ "Confidence" SG_ 2046 APP_rPillarCalibrated 1;
BA_ "Confidence" SG_ 2046 APP_lRepeatCamExtPitchCal 1;
BA_ "GenSigSNA" SG_ 2046 APP_lRepeatCamExtPitchCal "511";
BA_ "Confidence" SG_ 2046 APP_lRepeatCamExtYawCal 1;
BA_ "GenSigSNA" SG_ 2046 APP_lRepeatCamExtYawCal "511";
BA_ "Confidence" SG_ 2046 APP_lRepeatCalibTime 1;
BA_ "GenSigSNA" SG_ 2046 APP_lRepeatCalibTime "127";
BA_ "Confidence" SG_ 2046 APP_lRepeatCalibProgress 1;
BA_ "GenSigSNA" SG_ 2046 APP_lRepeatCalibProgress "127";
BA_ "Confidence" SG_ 2046 APP_lRepeatCalibrated 1;
BA_ "Confidence" SG_ 2046 APP_rRepeatCamExtPitchCal 1;
BA_ "GenSigSNA" SG_ 2046 APP_rRepeatCamExtPitchCal "511";
BA_ "Confidence" SG_ 2046 APP_rRepeatCamExtYawCal 1;
BA_ "GenSigSNA" SG_ 2046 APP_rRepeatCamExtYawCal "511";
BA_ "Confidence" SG_ 2046 APP_rRepeatCalibTime 1;
BA_ "GenSigSNA" SG_ 2046 APP_rRepeatCalibTime "127";
BA_ "Confidence" SG_ 2046 APP_rRepeatCalibProgress 1;
BA_ "GenSigSNA" SG_ 2046 APP_rRepeatCalibProgress "127";
BA_ "Confidence" SG_ 2046 APP_rRepeatCalibrated 1;
BA_ "Confidence" SG_ 2046 APP_backupCamExtPitchCal 1;
BA_ "GenSigSNA" SG_ 2046 APP_backupCamExtPitchCal "511";
BA_ "Confidence" SG_ 2046 APP_backupCamExtYawCal 1;
BA_ "GenSigSNA" SG_ 2046 APP_backupCamExtYawCal "511";
BA_ "Confidence" SG_ 2046 APP_backupCalibTime 1;
BA_ "GenSigSNA" SG_ 2046 APP_backupCalibTime "127";
BA_ "Confidence" SG_ 2046 APP_backupCalibProgress 1;
BA_ "GenSigSNA" SG_ 2046 APP_backupCalibProgress "127";
BA_ "Confidence" SG_ 2046 APP_backupCalibrated 1;
BA_ "Confidence" SG_ 1018 APP_mainCameraLUX 1;
BA_ "GenSigSNA" SG_ 1018 APP_mainCameraLUX "255";
BA_ "Confidence" SG_ 1018 APP_narrowCameraLUX 1;
BA_ "GenSigSNA" SG_ 1018 APP_narrowCameraLUX "255";
BA_ "Confidence" SG_ 1018 APP_fisheyeCameraLUX 1;
BA_ "GenSigSNA" SG_ 1018 APP_fisheyeCameraLUX "255";
BA_ "Confidence" SG_ 1018 APP_lRepeatCameraLUX 1;
BA_ "GenSigSNA" SG_ 1018 APP_lRepeatCameraLUX "255";
BA_ "Confidence" SG_ 1018 APP_rRepeatCameraLUX 1;
BA_ "GenSigSNA" SG_ 1018 APP_rRepeatCameraLUX "255";
BA_ "Confidence" SG_ 1018 APP_lPillarCameraLUX 1;
BA_ "GenSigSNA" SG_ 1018 APP_lPillarCameraLUX "255";
BA_ "Confidence" SG_ 1018 APP_rPillarCameraLUX 1;
BA_ "GenSigSNA" SG_ 1018 APP_rPillarCameraLUX "255";
BA_ "Confidence" SG_ 1018 APP_backupCameraLUX 1;
BA_ "GenSigSNA" SG_ 1018 APP_backupCameraLUX "255";
BA_ "Confidence" SG_ 1040 APP_backupCameraFeedGood 1;
BA_ "Confidence" SG_ 1040 APP_backupCameraFrameRate 1;
BA_ "Confidence" SG_ 1040 APP_cameraBlockedFrontMain 1;
BA_ "Confidence" SG_ 1040 APP_cameraBlockedFrontFisheye 1;
BA_ "Confidence" SG_ 1040 APP_cameraBlockedFrontNarrow 1;
BA_ "Confidence" SG_ 1040 APP_cameraBlockedLeftPillar 1;
BA_ "Confidence" SG_ 1040 APP_cameraBlockedLeftRepeater 1;
BA_ "Confidence" SG_ 1040 APP_cameraBlockedRightPillar 1;
BA_ "Confidence" SG_ 1040 APP_cameraBlockedRightRepeater 1;
BA_ "Confidence" SG_ 1040 APP_cameraBlockedBackup 1;
BA_ "Confidence" SG_ 1177 APP_rRepeaterCameraTemperature 1;
BA_ "Confidence" SG_ 1177 APP_lRepeaterCameraTemperature 1;
BA_ "Confidence" SG_ 1043 APP_mainDashCamFeedGood 1;
BA_ "Confidence" SG_ 1043 APP_mainDashCamFrameRate 1;
BA_ "Confidence" SG_ 1043 APP_lRepeatDashCamFeedGood 1;
BA_ "Confidence" SG_ 1043 APP_lRepeatDashCamFrameRate 1;
BA_ "Confidence" SG_ 1043 APP_rRepeatDashCamFeedGood 1;
BA_ "Confidence" SG_ 1043 APP_rRepeatDashCamFrameRate 1;
BA_ "Confidence" SG_ 1061 APP_factoryGoalLatitude 1;
BA_ "Confidence" SG_ 1061 APP_factoryGoalLongitude 1;
BA_ "Confidence" SG_ 1061 APP_factoryGoalSpeed 1;
BA_ "Confidence" SG_ 843 APP_frontLeftParkAssist 1;
BA_ "GenSigSNA" SG_ 843 APP_frontLeftParkAssist "255";
BA_ "Confidence" SG_ 843 APP_frontLeftMiddleParkAssist 1;
BA_ "GenSigSNA" SG_ 843 APP_frontLeftMiddleParkAssist "255";
BA_ "Confidence" SG_ 843 APP_frontMiddleParkAssist 1;
BA_ "GenSigSNA" SG_ 843 APP_frontMiddleParkAssist "255";
BA_ "Confidence" SG_ 843 APP_frontRightMiddleParkAssist 1;
BA_ "GenSigSNA" SG_ 843 APP_frontRightMiddleParkAssist "255";
BA_ "Confidence" SG_ 843 APP_frontRightParkAssist 1;
BA_ "GenSigSNA" SG_ 843 APP_frontRightParkAssist "255";
BA_ "Confidence" SG_ 843 APP_parkAssistStatus 1;
BA_ "GenSigSNA" SG_ 843 APP_parkAssistStatus "3";
BA_ "Confidence" SG_ 1353 APP_infoIndex 1;
BA_ "Confidence" SG_ 1353 APP_buildType 1;
BA_ "Confidence" SG_ 907 APP_rearLeftParkAssist 1;
BA_ "GenSigSNA" SG_ 907 APP_rearLeftParkAssist "255";
BA_ "Confidence" SG_ 907 APP_rearLeftMiddleParkAssist 1;
BA_ "GenSigSNA" SG_ 907 APP_rearLeftMiddleParkAssist "255";
BA_ "Confidence" SG_ 907 APP_rearMiddleParkAssist 1;
BA_ "GenSigSNA" SG_ 907 APP_rearMiddleParkAssist "255";
BA_ "Confidence" SG_ 907 APP_rearRightMiddleParkAssist 1;
BA_ "GenSigSNA" SG_ 907 APP_rearRightMiddleParkAssist "255";
BA_ "Confidence" SG_ 907 APP_rearRightParkAssist 1;
BA_ "GenSigSNA" SG_ 907 APP_rearRightParkAssist "255";
BA_ "Confidence" SG_ 601 APP_watchdogState 1;
BA_ "GenSigSNA" SG_ 601 APP_watchdogState "7";
BA_ "Confidence" SG_ 601 APP_fusedState 1;
BA_ "GenSigSNA" SG_ 601 APP_fusedState "3";
BA_ "Confidence" SG_ 601 APP_cameraHeaterRequest 1;
BA_ "Confidence" SG_ 601 APP_factorySummonStatus 1;
BA_ "GenSigSNA" SG_ 601 APP_factorySummonStatus "0";
BA_ "Confidence" SG_ 601 APP_clipRecordingStatus 1;
BA_ "Confidence" SG_ 601 APP_allowApActivationWithBrake 1;
BA_ "Confidence" SG_ 601 APP_summonUnavailableReason 1;
BA_ "Confidence" SG_ 601 APP_fsdSuspendState 1;
BA_ "GenSigSNA" SG_ 601 APP_fsdSuspendState "3";
BA_ "Confidence" SG_ 601 APP_fsdRevokeStrikeoutCount 1;
BA_ "GenSigSNA" SG_ 601 APP_fsdRevokeStrikeoutCount "7";
BA_ "Confidence" SG_ 601 APP_teslaVisionSupported 1;
BA_ "GenSigSNA" SG_ 601 APP_teslaVisionSupported "3";
BA_ "Confidence" SG_ 601 APP_teslaVisionUnsupportedReason 1;
BA_ "Confidence" SG_ 601 APP_fsdRevokeCount 1;
BA_ "GenSigSNA" SG_ 601 APP_fsdRevokeCount "7";
BA_ "Confidence" SG_ 601 APP_excessiveAccelPedalWarning 1;
BA_ "Confidence" SG_ 601 APP_unifiedObjectStackSupported 1;
BA_ "GenSigSNA" SG_ 601 APP_unifiedObjectStackSupported "3";
BA_ "Confidence" SG_ 601 APP_unifiedObjsUnsupportedReason 1;
BA_ "Confidence" SG_ 601 APP_DDAWSystemStatus 1;
BA_ "GenSigSNA" SG_ 601 APP_DDAWSystemStatus "4";
BA_ "Confidence" SG_ 601 APP_socOperatingMode 1;
BA_ "Confidence" SG_ 601 APP_summonVersionIdentifier 1;
BA_ "Confidence" SG_ 601 APP_sentryState 1;
BA_ "GenSigSNA" SG_ 601 APP_sentryState "6";
BA_ "Confidence" SG_ 601 APP_autoparkVersionIdentifier 1;
BA_ "Confidence" SG_ 601 APP_setSpeedMode 1;
BA_ "Confidence" SG_ 605 APP_tcFeatureState 1;
BA_ "Confidence" SG_ 605 APP_tcStateMachine 1;
BA_ "Confidence" SG_ 605 APP_tcControlSource 1;
BA_ "Confidence" SG_ 605 APP_tcControlType 1;
BA_ "Confidence" SG_ 605 APP_tcControlDistance 1;
BA_ "GenSigSNA" SG_ 605 APP_tcControlDistance "255";
BA_ "Confidence" SG_ 605 APP_tcControlLightState 1;
BA_ "Confidence" SG_ 605 APP_tcContinuationReason 1;
BA_ "Confidence" SG_ 605 APP_tcConfirmationType 1;
BA_ "Confidence" SG_ 605 APP_tcWarningSuppressionReason 1;
BA_ "Confidence" SG_ 605 APP_tcUnavailableReason 1;
BA_ "Confidence" SG_ 605 APP_tcVisionLight 1;
BA_ "Confidence" SG_ 605 APP_tcVisionSign 1;
BA_ "Confidence" SG_ 605 APP_tcVisionRoadMarking 1;
BA_ "Confidence" SG_ 605 APP_tcVisionLine 1;
BA_ "Confidence" SG_ 2045 APP_visionOcsStateRaw 1;
BA_ "Confidence" SG_ 2045 APP_visionOcsEmptyProbRaw 1;
BA_ "GenSigSNA" SG_ 2045 APP_visionOcsEmptyProbRaw "255";
BA_ "Confidence" SG_ 2045 APP_visionOcsChildProbRaw 1;
BA_ "GenSigSNA" SG_ 2045 APP_visionOcsChildProbRaw "255";
BA_ "Confidence" SG_ 2045 APP_visionOcsAdultProbRaw 1;
BA_ "GenSigSNA" SG_ 2045 APP_visionOcsAdultProbRaw "255";
BA_ "Confidence" SG_ 2045 APP_visionOcsFrontPasClsVisionSt 1;
BA_ "SystemSignalLongSymbol" SG_ 2045 APP_visionOcsFrontPasClsVisionSt "APP_visionOcsFrontPasClsVisionStateFlt";
VAL_ 1513 APP_sw188_minTemperature 255 "SNA" ;
VAL_ 1513 APP_sw188_maxTemperature 255 "SNA" ;
VAL_ 1513 APP_sw189_exitStatus 1 "FAULT" 0 "NOMINAL" ;
VAL_ 1513 APP_sw189_tempMonitorFailure 2 "MONITOR_OTHER_FAILURE" 1 "OUT_OF_SPEC" 0 "MONITOR_NO_FAILURE" ;
VAL_ 1513 APP_sw189_imagerHeartbeat 3 "SNA" 1 "STATIC" 0 "NOMINAL" ;
VAL_ 1513 APP_sw189_serializerCrcErrCount 255 "SNA" ;
VAL_ 1513 APP_sw189_currentTemperature 255 "SNA" ;
VAL_ 1513 APP_sw189_minTemperature 255 "SNA" ;
VAL_ 1513 APP_sw189_maxTemperature 255 "SNA" ;
VAL_ 1513 APP_sw190_exitStatus 1 "FAULT" 0 "NOMINAL" ;
VAL_ 1513 APP_sw190_tempMonitorFailure 2 "MONITOR_OTHER_FAILURE" 1 "OUT_OF_SPEC" 0 "MONITOR_NO_FAILURE" ;
VAL_ 1513 APP_sw190_imagerHeartbeat 3 "SNA" 1 "STATIC" 0 "NOMINAL" ;
VAL_ 1513 APP_sw190_serializerCrcErrCount 255 "SNA" ;
VAL_ 1513 APP_sw190_currentTemperature 255 "SNA" ;
VAL_ 1513 APP_sw190_minTemperature 255 "SNA" ;
VAL_ 1513 APP_sw190_maxTemperature 255 "SNA" ;
VAL_ 1513 APP_sw191_abortReason 255 "REASON_MAX" 68 "DOOR_OPEN" 67 "FRUNK_OPEN" 66 "TRUNK_OPEN" 65 "CABIN_CAM_ISSUE" 64 "TASK_FLOW_TRACE_TIMEOUT" 63 "SEALED_MERGE_CROSSING" 62 "FSD_GEOFENCE_DISABLED" 61 "EXTENDED_COMPUTE_INACTIVE_PCIE_LINK_HEALTH" 60 "EXTENDED_COMPUTE_INACTIVE_ETHERNET_LINK_HEALTH" 59 "EXTENDED_COMPUTE_INACTIVE_OTHER_SOC_HEALTH_CRITICAL" 58 "EXTENDED_COMPUTE_INACTIVE_OTHER_SOC_HEALTH_UNKNOWN" 57 "CABIN_CAM_BLIND" 56 "AHB_MANUAL_OVERRIDE" 55 "DRIVER_NOT_PRESENT" 54 "PERCEPTION_HEALTH_STALE" 53 "PERCEPTION_HEALTH_POST_PROCESSING" 52 "EXTENDED_COMPUTE_INACTIVE" 51 "CITY_STREETS_REF_TOO_SHORT" 50 "INVALID_BEHAVIOR" 49 "ONCOMING_LANE" 48 "HEADLIGHT_OFF_AT_NIGHT" 47 "IBOOSTER_MIA" 46 "INTEGRATOR_HEALTH_CRITICAL" 45 "USER_OVERRIDE_STRIKEOUT" 44 "SEATBELT_UNBUCKLED" 43 "PERCEPTION_HEALTH_VISION" 42 "INVALID_VEHICLE_SPEED" 41 "INVALID_DI_PEDAL_POS" 40 "W048_FEATURES_DISABLED" 39 "EPAS_STEERING_ANGLE_INVALID" 38 "STEERING_SATURATED_LANE_DEPARTURE" 37 "REACHED_END_OF_NAV_STOP" 36 "GORE_INCURSION" 35 "MISSION_PLANNER_NO_VISION_LANES_FOUND" 34 "CONTROLLER_REF_TOO_SHORT" 33 "AEB" 32 "CONTROLLER_BAD_REF_UPDATE" 31 "CONTROLLER_STALE_LOCALIZATION" 30 "CONTROLLER_STALE_REFERENCE" 29 "MAP_HEALTH" 28 "THERMAL_ISSUE" 27 "CONTROLLER_NOT_ALLOWED" 26 "CONTROLLER_SOLVER" 25 "CONTROLLER_REFERENCE" 24 "ROAD_ESTIMATOR_HEALTH" 23 "ACC_FAULT" 22 "ACC_CANCEL_SILENT" 21 "ACC_CANCEL_GENERIC" 20 "RADAR_FAULT" 19 "RADAR_BLIND" 18 "CAMERA_CALIBRATION" 17 "CAMERA_FAILSAFES" 16 "EPAS_EAC_ERROR" 15 "EPAS_EAC_NOT_ACTIVE" 14 "VEHICLE_SPEED_ABOVE_MAX" 13 "TRAILER_MODE_ACTIVE" 12 "USER_DISABLED" 11 "CRUISE_NOT_ACTIVE" 10 "CRUISE_FAULT" 9 "VCRIGHT_MIA" 8 "VCFRONT_MIA" 7 "RADAR_MIA" 6 "SCCM_MIA" 5 "GTW_MIA" 4 "EPAS_MIA" 3 "ESP_MIA" 2 "DI_MIA" 1 "WATCHDOG_HEALTH" 0 "NONE" ;
VAL_ 1513 APP_sw191_handsOnState 15 "SNA" 10 "REQD_ESCALATED_CHIME_2" 9 "REQD_ESCALATED_CHIME_1" 8 "SUSPENDED" 7 "REQD_STRUCK_OUT" 6 "REQD_SLOWING" 5 "REQD_CHIME_2" 4 "REQD_CHIME_1" 3 "REQD_VISUAL" 2 "REQD_NOT_DETECTED" 1 "REQD_DETECTED" 0 "NOT_REQD" ;
VAL_ 1513 APP_sw191_cruiseState 7 "PRE_CANCEL" 6 "PRE_FAULT" 5 "FAULT" 4 "OVERRIDE" 3 "STANDSTILL" 2 "ENABLED" 1 "STANDBY" 0 "UNAVAILABLE" ;
VAL_ 1513 APP_sw191_epasErrorCode 15 "SNA" 14 "EAC_EXTERNAL_MONITOR_INHIBIT" 13 "EAC_ERROR_PINION_VEL_DIFF" 12 "EAC_ERROR_LOW_ASSIST" 11 "EAC_ERROR_HIGH_TORSION_SAFETY" 10 "EAC_ERROR_HIGH_MMOT_SAFETY" 9 "EAC_ERROR_HIGH_ANGLE_RATE_SAFETY" 8 "EAC_ERROR_HIGH_ANGLE_SAFETY" 7 "EAC_ERROR_HIGH_ANGLE_RATE_REQ" 6 "EAC_ERROR_HIGH_ANGLE_REQ" 5 "EAR_ERROR_MAX_STEER_DELTA" 4 "EAC_ERROR_TMP_FAULT" 3 "EAC_ERROR_HANDS_ON" 2 "EAC_ERROR_MAX_SPEED" 1 "EAC_ERROR_MIN_SPEED" 0 "EAC_ERROR_IDLE" ;
VAL_ 1513 APP_sw191_roadClass 6 "CLASS_6_MINOR" 5 "CLASS_5" 4 "CLASS_4" 3 "CLASS_3" 2 "CLASS_2" 1 "CLASS_1_MAJOR" 0 "UNKNOWN_INVALID_SNA" ;
VAL_ 1513 APP_sw191_referenceHealth 2 "INDETERMINATE" 1 "UNHEALTHY" 0 "HEALTHY" ;
VAL_ 1513 APP_sw191_solverHealth 3 "FAILURE" 2 "CRITICAL" 1 "DEGRADED" 0 "HEALTHY" ;
VAL_ 1513 APP_sw191_roadEstHealth 3 "CRITICAL" 2 "DEGRADED" 1 "UNSTABLE_MEASUREMENTS" 0 "HEALTHY" ;
VAL_ 1513 APP_sw191_roadEstMode 2 "FULL" 1 "VL" 0 "MAP" ;
VAL_ 1513 APP_sw191_radarFault 1 "TRUE" 0 "FALSE" ;
VAL_ 1513 APP_sw191_radarBlind 1 "TRUE" 0 "FALSE" ;
VAL_ 1513 APP_sw191_cameraFailsafes 7 "MAX_CAM_FAILSAFES" 0 "NONE" ;
VAL_ 1513 APP_sw192_speakerFailureType 3 "WAKEUP_ERROR" 2 "SETUP_ERROR" 1 "INIT_ERROR" 0 "INIT_WAITING" ;
VAL_ 1513 APP_sw192_chassisType 4 "CYBERTRUCK" 3 "MODEL3" 2 "MODELX" 1 "MODELS" 0 "UNKNOWN" ;
VAL_ 1513 APP_sw192_hardwareType 3 "3" 2 "25" 1 "2" 0 "UNKNOWN" ;
VAL_ 1513 APP_sw194_reasonForHold 15 "SNA" 12 "STOPS_BUTTON_TOGGLE" 11 "MISSION_PLANNER_SLOWDOWN_REQUEST" 10 "STANDSTILL_STEERING_OVERRIDE" 9 "CAM_ONLY_CONTROL" 8 "MCP_CONTROL" 7 "DRIVER_SEATBELT" 6 "TRAFFIC_LIGHT" 5 "STOP_SIGN" 4 "CAM_STOP_AND_GO" 3 "TARGET_LOSS" 2 "ULTRASONIC_OBSTACLE" 1 "CAM_PEDESTRIAN" 0 "TIMEOUT" ;
VAL_ 1513 APP_sw199_abortCodeDas 47 "CLOSURE_OPEN" 46 "COLLISION_RISK" 45 "CONTROLLER_HEALTH" 44 "PLANNER_HEALTH" 43 "SPEED_TOO_HIGH" 42 "SEATBELT_UNBUCKLED" 41 "GEAR_SHIFT_TIMEOUT" 40 "CONTROL_INTEGRATOR" 39 "GRADE_TOO_HIGH" 38 "UI_DISPLAY_NOT_OK" 37 "EXTENDED_COMPUTE_NOT_ACTIVE" 36 "REQUIRED_CAMERA_NOT_READY" 35 "FORWARD_CAMERAS_BLINDED" 34 "REPEATER_CAMERA_BLINDED" 33 "BACKUP_CAMERA_BLINDED" 32 "EXTERIOR_LIGHTS_OFF" 31 "DRIVER_NOT_DETECTED" 30 "UNAUTHORIZED_REQUEST" 29 "DRIVABLE_SPACE_STALE" 28 "TOO_MANY_GEAR_CHANGES" 27 "TRAILER_MODE" 26 "PARKER_HEARTBEAT_MISSING" 25 "HEARTBEAT_MISSING" 24 "APP_MIA" 23 "PAUSE_CYCLES" 22 "EPAS_INHIBITED" 21 "USER_KEYFOB" 20 "SC_MIA" 19 "SENSOR_FAILURE" 18 "PRECRUISE_TIMEOUT" 17 "UI_REQUEST" 16 "LOST_DI_CONTROL" 15 "PARK_GEAR" 14 "RESTART_TIMEOUT" 13 "PAUSE_USER_TIMEOUT" 12 "PAUSE_OBSTACLE_TIMEOUT" 11 "ESP_MIA" 10 "SCCM_MIA" 9 "MCU_MIA" 8 "DI_MIA" 7 "EPAS_MIA" 6 "PARK_MIA" 5 "PREGUIDANCE_TIMEOUT" 4 "INVALID_SPACE" 3 "MCU_REQUEST_MISMATCH" 2 "PARK_GUIDANCE_ENDED" 1 "LOST_ANGLE_CONTROL" 0 "NONE" ;
VAL_ 1513 APP_sw199_abortCodePARK 31 "SNA" 25 "PSC_MOVEMENT_AT_ACTIVATION" 24 "PSC_MAX_WAY_BEHIND_HINT" 23 "PSC_PARK_STC_FAILED" 22 "PSC_PARK_PONR_NOT_REACHED" 21 "PSC_VCTL_GENERAL_ABORT" 20 "PSC_HIGH_TORQUE" 19 "PSC_ASYNC_CTRL_SYSTEM" 18 "ERROR" 17 "SYSTEM_SERVICE" 16 "SYSTEM_FAULT" 15 "ECU_INTERNAL_FAULT" 14 "DAS_ABORT" 13 "EPAS_FAULT" 12 "VEHICLE_DYNAMICS_INTERVENTION" 11 "HANDS_ON_DETECTED" 10 "FULL_WARNING_ON_BOTH_SIDES" 9 "PARK_SPACE_TOO_SMALL" 8 "OBSTACLE_ON_PATH" 7 "MAX_YAW_ANGLE_REACHED" 6 "MAX_SWA_DEV_EXCEEDED" 5 "OFF_TRACK" 4 "UNCONTROLLED_TRAVEL_DIST_REACHED" 3 "NO_VALID_PATH" 2 "MAX_NUM_OF_MOVES" 1 "VELOCITY_TOO_HIGH" 0 "NONE" ;
VAL_ 1513 APP_sw203_controlType 15 "SNA" 14 "SUMMON" 10 "PAUSE" 9 "SEARCH" 8 "COMPLETE" 7 "ABORT" 6 "PARALLEL_PULL_OUT_TO_RIGHT" 5 "PARALLEL_PULL_OUT_TO_LEFT" 4 "PARK_RIGHT_CROSS" 3 "PARK_RIGHT_PARALLEL" 2 "PARK_LEFT_CROSS" 1 "PARK_LEFT_PARALLEL" 0 "NONE" ;
VAL_ 1513 APP_sw207_lcUnavailableReason 255 "LC_UNAVAILABLE_UNKNOWN" 120 "RR_UNAVAILABLE_SEATBELT_UNBUCKLED" 119 "RR_UNAVAILABLE_DOOR_OPEN" 118 "RR_UNAVAILABLE_FRUNK_OPEN" 117 "RR_UNAVAILABLE_TRUNK_OPEN" 116 "RR_UNAVAILABLE_OFF_ROAD_MODE_ACTIVE" 115 "RR_UNAVAILABLE_SUPPRESS_FOR_RECENT_SCROLL_WHEEL_INTERACTION" 114 "RR_UNAVAILABLE_SUPPRESS_FOR_RECENT_AUTOPARK_ACTIVATION" 113 "RR_UNAVAILABLE_CRUISE_STACK_MISMATCH" 112 "RR_UNAVAILABLE_CRUISE_REQUEST_TIMEOUT" 111 "RR_UNAVAILABLE_CRUISE_UNAVAILABLE" 110 "RR_UNAVAILABLE_USER_SETTINGS_NOT_SUPPORTED" 109 "RR_UNAVAILABLE_AUTOSTEER_INACTIVE_FOR_SINGLE_CLICK" 108 "RR_UNAVAILABLE_CABIN_CAM_ISSUE" 107 "RR_UNAVAILABLE_AUTOSTEER_AVAILABILITY_HYSTERESIS" 106 "RR_UNAVAILABLE_TASK_FLOW_TRACE_TIMEOUT_SLAM" 105 "RR_UNAVAILABLE_TASK_FLOW_TRACE_TIMEOUT_LOCALIZATION" 104 "RR_UNAVAILABLE_TASK_FLOW_TRACE_TIMEOUT_STATIC_WORLD" 103 "RR_UNAVAILABLE_TASK_FLOW_TRACE_TIMEOUT_DYNAMIC_WORLD" 102 "RR_UNAVAILABLE_TASK_FLOW_TRACE_TIMEOUT_UNKNOWN" 101 "RR_UNAVAILABLE_FSD_FAILSAFE_ACTIVE" 100 "RR_UNAVAILABLE_RESTRICTED_SPACE" 99 "RR_UNAVAILABLE_SEALED_MERGE_CROSSING" 98 "RR_UNAVAILABLE_FSD_GEOFENCE_DISABLED" 97 "RR_UNAVAILABLE_EXTENDED_COMPUTE_INACTIVE_PCIE_LINK_HEALTH" 96 "RR_UNAVAILABLE_EXTENDED_COMPUTE_INACTIVE_ETHERNET_LINK_HEALTH" 95 "RR_UNAVAILABLE_EXTENDED_COMPUTE_INACTIVE_OTHER_SOC_HEALTH_CRITICAL" 94 "RR_UNAVAILABLE_EXTENDED_COMPUTE_INACTIVE_OTHER_SOC_HEALTH_UNKNOWN" 93 "RR_UNAVAILABLE_CABIN_CAM_BLIND" 92 "RR_UNAVAILABLE_AHB_MANUAL_OVERRIDE" 91 "RR_UNAVAILABLE_DRIVER_NOT_PRESENT" 90 "RR_UNAVAILABLE_LOW_ODOMETRY" 89 "RR_UNAVAILABLE_ROAD_CLASS" 88 "RR_UNAVAILABLE_PERCEPTION_HEALTH_STALE" 87 "RR_UNAVAILABLE_PERCEPTION_HEALTH_POST_PROCESSING" 86 "RR_UNAVAILABLE_RECENT_USER_CANCELLATION" 85 "RR_UNAVAILABLE_HEADLIGHT_FAILSAFE" 84 "RR_UNAVAILABLE_EXTENDED_COMPUTE_INACTIVE" 83 "RR_UNAVAILABLE_CITY_STREETS_REF_TOO_SHORT" 82 "RR_UNAVAILABLE_INVALID_BEHAVIOR" 81 "RR_UNAVAILABLE_RECENT_GEAR_SHIFT" 80 "RR_UNAVAILABLE_SYSTEM_HEALTH_CRITICAL" 79 "RR_UNAVAILABLE_PERCEPTION_HEALTH_RADAR" 78 "RR_UNAVAILABLE_PERCEPTION_HEALTH_VISION" 77 "RR_UNAVAILABLE_RADAR_BLIND" 76 "RR_UNAVAILABLE_RADAR_FAULT" 75 "RR_UNAVAILABLE_RADAR_MIA" 74 "RR_UNAVAILABLE_ECU_THERMAL_ISSUE" 73 "RR_UNAVAILABLE_AEB_ACTIVE" 72 "RR_UNAVAILABLE_AUTOPARK_STATE" 71 "RR_UNAVAILABLE_STEERING_WHEEL_ANGLE" 70 "RR_UNAVAILABLE_FAILED_AUTOSTEER_ACTIVATION" 69 "RR_UNAVAILABLE_INVALID_DI_PEDAL_POS" 68 "RR_UNAVAILABLE_INVALID_VEHICLE_SPEED" 67 "RR_UNAVAILABLE_AP_NOT_CONFIGURED" 66 "RR_UNAVAILABLE_INTEGRATOR_HEALTH_CRITICAL" 65 "RR_UNAVAILABLE_RADAR_VERSION_MISMATCH" 64 "RR_UNAVAILABLE_TRACKED_OBSTACLE_DETECTED" 63 "RR_UNAVAILABLE_SONIC_OBSTACLE_DETECTED" 62 "RR_UNAVAILABLE_PEDESTRIAN_PRESENT_OR_NO_VEHICLE" 61 "RR_UNAVAILABLE_AVAILABILITY_CHECK_HYSTERESIS" 60 "RR_UNAVAILABLE_CAMERA_BLOCKED" 59 "RR_UNAVAILABLE_CAMERA_PITCH" 58 "RR_UNAVAILABLE_CAMERA_CALIBRATION" 57 "RR_UNAVAILABLE_DI_MIA" 56 "RR_UNAVAILABLE_GTW_MIA" 55 "RR_UNAVAILABLE_EPAS_MIA" 54 "RR_UNAVAILABLE_ESP_MIA" 53 "RR_UNAVAILABLE_DI_PARTY_MIA" 52 "RR_UNAVAILABLE_EPAS_PARTY_MIA" 51 "RR_UNAVAILABLE_ESP_PARTY_MIA" 50 "RR_UNAVAILABLE_CONTROL_REFERENCE_UNHEALTHY" 49 "RR_UNAVAILABLE_CONTROL_STALE_REFERENCE" 48 "RR_UNAVAILABLE_CONTROL_STALE_LOCALIZATION" 47 "RR_UNAVAILABLE_CONTROL_BAD_UPDATE" 46 "RR_UNAVAILABLE_CONTROL_REFERENCE_TOO_SHORT" 45 "RR_UNAVAILABLE_CONTROL_INDETERMINATE" 44 "RR_UNAVAILABLE_BELOW_MIN_SPEED" 43 "LC_UNAVAILABLE_SEATBELT_UNBUCKLED" 42 "RR_UNAVAILABLE_EPAS_STEERING_ANGLE_INVALID" 41 "RR_UNAVAILABLE_SYNTHESIZED_ACC_LANES_ACTIVE" 40 "RR_UNAVAILABLE_MCU_LATERAL_CONTROL_DISABLED" 39 "RR_UNAVAILABLE_INVALID_LANE_LINE_TYPE" 38 "RR_UNAVAILABLE_ROAD_ESTIMATOR_NOT_ALLOWED" 37 "RR_UNAVAILABLE_VEHICLE_SPEED_ABOVE_MAX_HYST" 36 "RR_UNAVAILABLE_SPEED_LIMIT_EXCEEDED" 35 "RR_UNAVAILABLE_CONTROL_SOLVER_UNHEALTHY" 34 "RR_UNAVAILABLE_CONTROL_PATH_UNHEALTHY" 33 "RR_UNAVAILABLE_CONTROL_OUTSIDE_LIMITS" 32 "RR_UNAVAILABLE_USER_STRIKEOUT" 31 "RR_UNAVAILABLE_EAC_REQUEST_TIMEOUT" 30 "RR_UNAVAILABLE_HK_TW_RESTRICTED" 29 "RR_UNAVAILABLE_TRAILER_MODE_ACTIVE" 28 "RR_UNAVAILABLE_CAMERA_FAILSAFES" 27 "RR_UNAVAILABLE_STEERING_LIMITS_EXCEEDED" 26 "RR_UNAVAILABLE_VEHICLE_SPEED_ABOVE_MAX" 25 "RR_UNAVAILABLE_VEHICLE_NOT_IN_DRIVE" 24 "RR_UNAVAILABLE_CRUISE_FAULT" 23 "RR_UNAVAILABLE_COMPONENT_NOT_READY" 22 "RR_UNAVAILABLE_COMPONENT_MIA" 21 "RR_UNAVAILABLE_EPAS_EAC_DENIED" 20 "RR_UNAVAILABLE_NONE" 19 "LC_UNAVAILABLE_VEHICLE_SPEED_ABOVE_MAX_HYST" 18 "LC_UNAVAILABLE_NOT_ON_HIGHWAY" 17 "LC_UNAVAILABLE_SPEED_LIMIT_EXCEEDED" 16 "LC_UNAVAILABLE_APP_ME_STATE_NOT_VISION" 15 "LC_UNAVAILABLE_ME_MAIN_STATE_NOT_VISION" 14 "LC_UNAVAILABLE_USER_STRIKEOUT" 13 "LC_UNAVAILABLE_EAC_REQUEST_TIMEOUT" 12 "LC_UNAVAILABLE_CAM_MSG_MIA" 11 "LC_UNAVAILABLE_HK_TW_RESTRICTED" 10 "LC_UNAVAILABLE_CAM_WATCHDOG" 9 "LC_UNAVAILABLE_TRAILER_MODE_ACTIVE" 8 "LC_UNAVAILABLE_CAMERA_FAILSAFES" 7 "LC_UNAVAILABLE_STEERING_LIMITS_EXCEEDED" 6 "LC_UNAVAILABLE_VEHICLE_SPEED_ABOVE_MAX" 5 "LC_UNAVAILABLE_VEHICLE_NOT_IN_DRIVE" 4 "LC_UNAVAILABLE_CRUISE_FAULT" 3 "LC_UNAVAILABLE_COMPONENT_NOT_READY" 2 "LC_UNAVAILABLE_COMPONENT_MIA" 1 "LC_UNAVAILABLE_EPAS_EAC_DENIED" 0 "LC_UNAVAILABLE_NONE" ;
VAL_ 1513 APP_sw213_autopilotIntState 15 "PARKED_FSD_AVAILABLE" 14 "PARKING" 13 "FULL_ABORTED" 12 "FULL_ABORTING" 11 "AUTOSTEER_ABORTED" 10 "AUTOSTEER_ABORTING" 9 "AUTOSTEER_CANCELING" 8 "AUTOSTEER_ACTIVE" 7 "AUTOSTEER_PREACTIVE" 6 "ACC_ACTIVE_AUTOSTEER_AVAILABLE" 5 "ACC_ACTIVE_AUTOSTEER_UNAVAILABLE" 4 "AUTOSTEER_AVAILABLE" 3 "ACC_AVAILABLE" 2 "UNAVAILABLE" 1 "DISABLED" 0 "FAULT" ;
VAL_ 1513 APP_sw213_apIntStateAtTrigger 15 "PARKED_FSD_AVAILABLE" 14 "PARKING" 13 "FULL_ABORTED" 12 "FULL_ABORTING" 11 "AUTOSTEER_ABORTED" 10 "AUTOSTEER_ABORTING" 9 "AUTOSTEER_CANCELING" 8 "AUTOSTEER_ACTIVE" 7 "AUTOSTEER_PREACTIVE" 6 "ACC_ACTIVE_AUTOSTEER_AVAILABLE" 5 "ACC_ACTIVE_AUTOSTEER_UNAVAILABLE" 4 "AUTOSTEER_AVAILABLE" 3 "ACC_AVAILABLE" 2 "UNAVAILABLE" 1 "DISABLED" 0 "FAULT" ;
VAL_ 1513 APP_sw260_user_sensitivity 3 "SNA" 2 "AEB_SENSITIVITY_LATE" 1 "AEB_SENSITIVITY_AVERAGE" 0 "AEB_SENSITIVITY_EARLY" ;
VAL_ 1513 APP_sw263_markerType 7 "DOTTED" 6 "DASHED" 5 "DOUBLE_SOLID" 4 "SOLID" 3 "UNMARKED" 2 "EDGE" 1 "INVALID" 0 "UNKNOWN" ;
VAL_ 1513 APP_sw263_side 1 "LEFT" 0 "RIGHT" ;
VAL_ 1513 APP_sw263_lssAbortReason 16 "STEERING_ANGLE_OUT_OF_BOUNDS" 15 "STEERING_ANGLE_DELTA_TOO_LARGE" 14 "LANE_CHANGE" 13 "VEHICLE_MU_LOW" 12 "TURN_INDICATOR_ON" 11 "FRONT_OBSTACLE_AVOIDANCE" 10 "SIDE_OBSTACLE_AVOIDANCE" 9 "LANE_TOO_NARROW" 8 "HILLCREST" 7 "SNOWY_ROAD" 6 "CONSTRUCTION" 5 "VDC_ACTIVE" 4 "TIMER_EXPIRED" 3 "EAC_STATUS" 2 "STEERING_WHEEL_TORSION" 1 "UNAVAILABLE" 0 "NO_ABORT" ;
VAL_ 1513 APP_sw264_faultReason 31 "INVALID" 16 "ELK_LIMITED" 15 "SCCM_MIA" 14 "FISHEYE_CALIBRATION_FAULT" 13 "NARROW_CALIBRATION_FAULT" 12 "MAIN_CALIBRATION_FAULT" 11 "ACTIVATION_COUNT" 10 "ELK_ACTIVATIONS" 9 "LKA_ACTIVATIONS" 8 "VDC_FAULT" 7 "EPAS_FAULT" 6 "CAMERA_FISHEYE" 5 "CAMERA_NARROW" 4 "CAMERA_MAIN" 3 "EPAS_MIA" 2 "EPAS_UNRESPONSIVE" 1 "EAC_INHIBIT" 0 "NO_FAULT" ;
VAL_ 1513 APP_sw265_surroundCameraStatus 2 "PERMANENT_UNAVAILABLE" 1 "TEMPORARY_UNAVAILABLE" 0 "AVAILABLE" ;
VAL_ 1513 APP_sw265_unavailableReason 25 "BLINKER_FAULTED" 24 "UNAVAILABLE_AUDIO" 23 "SCENE_TAG_SUN_GLARE" 22 "SCENE_TAG_SEVERE_WEATHER" 21 "SCENE_TAG_LENS_FLARE" 20 "SCENE_TAG_FULLY_BLOCKED" 19 "SCENE_TAG_FOG" 18 "SCENE_TAG_BLURRY" 17 "SCENE_TAG_BAD_CAMERA" 16 "NAV_ROUTE_NOT_ACTIVE" 15 "FEATURE_NOT_ENABLED" 14 "AUTOPILOT_UNAVAILABLE" 13 "INCOMPATIBLE_WAY" 12 "HIGH_CURVATURE" 11 "TOLLBOOTH_DETECTED" 10 "CONSTRUCTION_DETECTED" 9 "AUTO_WIPER_ACTIVE" 8 "IMPLAUSIBLE_MAP_DATA" 7 "GPS_DEGRADED" 6 "ULTRASONICS_INVALID" 5 "EDGE_LOCALIZATION_FAILED" 4 "ROUTE_DOWNLOAD_FAILED" 3 "UNAVAILABLE_CAMERA_BLOCKED" 2 "CAMERA_UNAVAILABLE" 1 "INVALID_NAV_GOAL" 0 "UNAVAILABLE_NONE" ;
VAL_ 1513 APP_sw266_lPillarStreamStatus 7 "FINISHED" 6 "FAILED" 5 "RECOVERING" 4 "ACTIVE" 3 "INIT_DEFERRED" 2 "INIT_FAILED" 1 "INITIALIZING" 0 "NOT_ACTIVE" ;
VAL_ 1513 APP_sw266_rPillarStreamStatus 7 "FINISHED" 6 "FAILED" 5 "RECOVERING" 4 "ACTIVE" 3 "INIT_DEFERRED" 2 "INIT_FAILED" 1 "INITIALIZING" 0 "NOT_ACTIVE" ;
VAL_ 1513 APP_sw266_lRepeaterStreamStatus 7 "FINISHED" 6 "FAILED" 5 "RECOVERING" 4 "ACTIVE" 3 "INIT_DEFERRED" 2 "INIT_FAILED" 1 "INITIALIZING" 0 "NOT_ACTIVE" ;
VAL_ 1513 APP_sw266_rRepeaterStreamStatus 7 "FINISHED" 6 "FAILED" 5 "RECOVERING" 4 "ACTIVE" 3 "INIT_DEFERRED" 2 "INIT_FAILED" 1 "INITIALIZING" 0 "NOT_ACTIVE" ;
VAL_ 1513 APP_sw266_backupStreamStatus 7 "FINISHED" 6 "FAILED" 5 "RECOVERING" 4 "ACTIVE" 3 "INIT_DEFERRED" 2 "INIT_FAILED" 1 "INITIALIZING" 0 "NOT_ACTIVE" ;
VAL_ 1513 APP_sw269_emergencyLaneKeep 31 "LIMITED_SNA" 17 "LIMITED_VEHICLE_SPEED_INVALID" 16 "LIMITED_CAMERAS_NOT_CALIBRATED" 15 "LIMITED_OFF_ROAD_MODE" 14 "LIMITED_TRACK_MODE" 13 "LIMITED_ULTRASONICS_BLOCKED" 12 "LIMITED_ABOVE_MAX_SPEED" 11 "LIMITED_WEATHER" 10 "LIMITED_CONSTRUCTION" 9 "LIMITED_TURN_INDICATOR_FAULT" 8 "LIMITED_FISHEYE_CAMERA" 7 "LIMITED_NARROW_CAMERA" 6 "LIMITED_MAIN_CAMERA" 5 "LIMITED_BACKUP_CAMERA" 4 "LIMITED_RIGHT_REPEATER_CAMERA" 3 "LIMITED_LEFT_REPEATER_CAMERA" 2 "LIMITED_RIGHT_PILLAR_CAMERA" 1 "LIMITED_LEFT_PILLAR_CAMERA" 0 "NOMINAL" ;
VAL_ 1513 APP_sw269_laneKeepAssist 31 "LIMITED_SNA" 17 "LIMITED_VEHICLE_SPEED_INVALID" 16 "LIMITED_CAMERAS_NOT_CALIBRATED" 15 "LIMITED_OFF_ROAD_MODE" 14 "LIMITED_TRACK_MODE" 13 "LIMITED_ULTRASONICS_BLOCKED" 12 "LIMITED_ABOVE_MAX_SPEED" 11 "LIMITED_WEATHER" 10 "LIMITED_CONSTRUCTION" 9 "LIMITED_TURN_INDICATOR_FAULT" 8 "LIMITED_FISHEYE_CAMERA" 7 "LIMITED_NARROW_CAMERA" 6 "LIMITED_MAIN_CAMERA" 5 "LIMITED_BACKUP_CAMERA" 4 "LIMITED_RIGHT_REPEATER_CAMERA" 3 "LIMITED_LEFT_REPEATER_CAMERA" 2 "LIMITED_RIGHT_PILLAR_CAMERA" 1 "LIMITED_LEFT_PILLAR_CAMERA" 0 "NOMINAL" ;
VAL_ 1513 APP_sw269_blindspot 31 "LIMITED_SNA" 17 "LIMITED_VEHICLE_SPEED_INVALID" 16 "LIMITED_CAMERAS_NOT_CALIBRATED" 15 "LIMITED_OFF_ROAD_MODE" 14 "LIMITED_TRACK_MODE" 13 "LIMITED_ULTRASONICS_BLOCKED" 12 "LIMITED_ABOVE_MAX_SPEED" 11 "LIMITED_WEATHER" 10 "LIMITED_CONSTRUCTION" 9 "LIMITED_TURN_INDICATOR_FAULT" 8 "LIMITED_FISHEYE_CAMERA" 7 "LIMITED_NARROW_CAMERA" 6 "LIMITED_MAIN_CAMERA" 5 "LIMITED_BACKUP_CAMERA" 4 "LIMITED_RIGHT_REPEATER_CAMERA" 3 "LIMITED_LEFT_REPEATER_CAMERA" 2 "LIMITED_RIGHT_PILLAR_CAMERA" 1 "LIMITED_LEFT_PILLAR_CAMERA" 0 "NOMINAL" ;
VAL_ 1513 APP_sw269_laneDepartureWarning 31 "LIMITED_SNA" 17 "LIMITED_VEHICLE_SPEED_INVALID" 16 "LIMITED_CAMERAS_NOT_CALIBRATED" 15 "LIMITED_OFF_ROAD_MODE" 14 "LIMITED_TRACK_MODE" 13 "LIMITED_ULTRASONICS_BLOCKED" 12 "LIMITED_ABOVE_MAX_SPEED" 11 "LIMITED_WEATHER" 10 "LIMITED_CONSTRUCTION" 9 "LIMITED_TURN_INDICATOR_FAULT" 8 "LIMITED_FISHEYE_CAMERA" 7 "LIMITED_NARROW_CAMERA" 6 "LIMITED_MAIN_CAMERA" 5 "LIMITED_BACKUP_CAMERA" 4 "LIMITED_RIGHT_REPEATER_CAMERA" 3 "LIMITED_LEFT_REPEATER_CAMERA" 2 "LIMITED_RIGHT_PILLAR_CAMERA" 1 "LIMITED_LEFT_PILLAR_CAMERA" 0 "NOMINAL" ;
VAL_ 1513 APP_sw270_emergencyLaneKeep 31 "LIMITED_SNA" 17 "LIMITED_VEHICLE_SPEED_INVALID" 16 "LIMITED_CAMERAS_NOT_CALIBRATED" 15 "LIMITED_OFF_ROAD_MODE" 14 "LIMITED_TRACK_MODE" 13 "LIMITED_ULTRASONICS_BLOCKED" 12 "LIMITED_ABOVE_MAX_SPEED" 11 "LIMITED_WEATHER" 10 "LIMITED_CONSTRUCTION" 9 "LIMITED_TURN_INDICATOR_FAULT" 8 "LIMITED_FISHEYE_CAMERA" 7 "LIMITED_NARROW_CAMERA" 6 "LIMITED_MAIN_CAMERA" 5 "LIMITED_BACKUP_CAMERA" 4 "LIMITED_RIGHT_REPEATER_CAMERA" 3 "LIMITED_LEFT_REPEATER_CAMERA" 2 "LIMITED_RIGHT_PILLAR_CAMERA" 1 "LIMITED_LEFT_PILLAR_CAMERA" 0 "NOMINAL" ;
VAL_ 1513 APP_sw270_laneKeepAssist 31 "LIMITED_SNA" 17 "LIMITED_VEHICLE_SPEED_INVALID" 16 "LIMITED_CAMERAS_NOT_CALIBRATED" 15 "LIMITED_OFF_ROAD_MODE" 14 "LIMITED_TRACK_MODE" 13 "LIMITED_ULTRASONICS_BLOCKED" 12 "LIMITED_ABOVE_MAX_SPEED" 11 "LIMITED_WEATHER" 10 "LIMITED_CONSTRUCTION" 9 "LIMITED_TURN_INDICATOR_FAULT" 8 "LIMITED_FISHEYE_CAMERA" 7 "LIMITED_NARROW_CAMERA" 6 "LIMITED_MAIN_CAMERA" 5 "LIMITED_BACKUP_CAMERA" 4 "LIMITED_RIGHT_REPEATER_CAMERA" 3 "LIMITED_LEFT_REPEATER_CAMERA" 2 "LIMITED_RIGHT_PILLAR_CAMERA" 1 "LIMITED_LEFT_PILLAR_CAMERA" 0 "NOMINAL" ;
VAL_ 1513 APP_sw270_blindspot 31 "LIMITED_SNA" 17 "LIMITED_VEHICLE_SPEED_INVALID" 16 "LIMITED_CAMERAS_NOT_CALIBRATED" 15 "LIMITED_OFF_ROAD_MODE" 14 "LIMITED_TRACK_MODE" 13 "LIMITED_ULTRASONICS_BLOCKED" 12 "LIMITED_ABOVE_MAX_SPEED" 11 "LIMITED_WEATHER" 10 "LIMITED_CONSTRUCTION" 9 "LIMITED_TURN_INDICATOR_FAULT" 8 "LIMITED_FISHEYE_CAMERA" 7 "LIMITED_NARROW_CAMERA" 6 "LIMITED_MAIN_CAMERA" 5 "LIMITED_BACKUP_CAMERA" 4 "LIMITED_RIGHT_REPEATER_CAMERA" 3 "LIMITED_LEFT_REPEATER_CAMERA" 2 "LIMITED_RIGHT_PILLAR_CAMERA" 1 "LIMITED_LEFT_PILLAR_CAMERA" 0 "NOMINAL" ;
VAL_ 1513 APP_sw270_laneDepartureWarning 31 "LIMITED_SNA" 17 "LIMITED_VEHICLE_SPEED_INVALID" 16 "LIMITED_CAMERAS_NOT_CALIBRATED" 15 "LIMITED_OFF_ROAD_MODE" 14 "LIMITED_TRACK_MODE" 13 "LIMITED_ULTRASONICS_BLOCKED" 12 "LIMITED_ABOVE_MAX_SPEED" 11 "LIMITED_WEATHER" 10 "LIMITED_CONSTRUCTION" 9 "LIMITED_TURN_INDICATOR_FAULT" 8 "LIMITED_FISHEYE_CAMERA" 7 "LIMITED_NARROW_CAMERA" 6 "LIMITED_MAIN_CAMERA" 5 "LIMITED_BACKUP_CAMERA" 4 "LIMITED_RIGHT_REPEATER_CAMERA" 3 "LIMITED_LEFT_REPEATER_CAMERA" 2 "LIMITED_RIGHT_PILLAR_CAMERA" 1 "LIMITED_LEFT_PILLAR_CAMERA" 0 "NOMINAL" ;
VAL_ 1513 APP_sw271_abortReason 23 "DESTINATION_LANE_UNSTABLE" 22 "ULC_SNOOZED" 21 "SOURCE_AND_TARGET_LANES_MERGED" 20 "NO_HANDS_ON" 19 "TOLL_BOOTH_DETECTED" 18 "CONSTRUCTION_DETECTED" 17 "GORE_POINT" 16 "ALC_REQUEST_BEFORE_ULC_CONFIRM" 15 "ULC_CONFIRMATION_TIMEOUT" 14 "HIGH_ALC_PROGRESS_ERROR" 13 "ULC_BLINKER_TIMEOUT" 12 "REQUESTED_BEHAVIOR_CHANGED" 11 "BELOW_MIN_SPEED" 10 "INVALID_BEHAVIOR" 9 "AUTOSTEER_ACTIVATED" 8 "LOST_VISION_POSE" 7 "INVALID_MODE" 6 "FORK_AVAILABLE" 5 "LINE_TYPE" 4 "BLIND_SPOT_OCCUPIED_TIMEOUT" 3 "BLINKER_CHANGE" 2 "ALC_TIMEOUT" 1 "CONTROL_INACTIVE" 0 "NONE" ;
VAL_ 1513 APP_sw271_direction 1 "LEFT" 0 "RIGHT" ;
VAL_ 1513 APP_sw272_unavailableReason 12 "BLINKER_FAULTED" 11 "AUTOPILOT_ABORTING" 10 "BLINKER_UNLATCHED" 9 "NO_REAR_OBJECT_DETECTED" 8 "CRITICAL_SITUATION" 7 "BLINDSPOT_RESTRICTED" 6 "ULTRASONICS_NOT_READY" 5 "FORK_MODE" 4 "NO_LANES" 3 "SPEED" 2 "ROAD_NOT_APPROPRIATE" 1 "NOT_ENABLED" 0 "NONE" ;
VAL_ 1513 APP_sw273_eventType 1 "ELK" 0 "LKA" ;
VAL_ 1513 APP_sw273_collisionType 4 "ROAD_EDGE" 3 "ONCOMING" 2 "ADJACENT" 1 "OVERTAKING" 0 "NONE" ;
VAL_ 1513 APP_sw273_side 1 "LEFT" 0 "RIGHT" ;
VAL_ 1513 APP_sw283_appAbortReason 26 "OUTSIDE_GEOFENCE" 25 "PARK_REQUEST_TIMEOUT" 24 "ACCEL_PEDAL_PRESSED" 23 "BRAKE_PEDAL_PRESSED" 22 "REMOTE_ABORT_REQUESTED" 21 "CLOSURE_OPEN" 20 "LOW_TIRE_PRESSURE" 19 "HIGH_GRADE" 18 "COLLISION_MITIGATION" 17 "PUBLIC_ROAD_BOUNDARIES_NOT_VALID" 16 "ULTRASONIC_STALE" 15 "VISION_HEALTH_CRITICAL" 14 "RADAR_HEALTH_CRITICAL" 13 "PUBLIC_ROAD" 12 "END_OF_LEASH" 11 "MAX_ALLOWED_DISTANCE" 10 "MAX_ALLOWED_TIME" 9 "AURIX_NOT_ACTIVE" 8 "PHONE_IS_TOO_FAR" 7 "EGO_GPS_UNAVAILABLE" 6 "PHONE_GPS_UNAVAILABLE" 5 "NO_VALID_PATH" 4 "ULTRASONIC_FAULT" 3 "ULTRASONIC_BLOCKED" 2 "CAMERA_BLOCKED" 1 "CAMERA_STREAM" 0 "NONE" ;
VAL_ 1513 APP_sw283_apsAbortReason 43 "CLOSURE_OPEN" 42 "COLLISION_RISK" 41 "CONTROLLER_HEALTH" 40 "SEATBELT_UNBUCKLED" 39 "SPEED_TOO_HIGH" 38 "GEAR_SHIFT_TIMEOUT" 37 "CONTROL_INTEGRATOR" 36 "GRADE_TOO_HIGH" 35 "EXTENDED_COMPUTE_NOT_ACTIVE" 34 "FORWARD_CAMERAS_BLINDED" 33 "BACKUP_CAMERA_BLINDED" 32 "EXTERIOR_LIGHTS_OFF" 31 "DRIVER_NOT_DETECTED" 30 "UNAUTHORIZED_REQUEST" 29 "DRIVABLE_SPACE_STALE" 28 "TOO_MANY_GEAR_CHANGES" 27 "TRAILER_MODE" 26 "PARKER_HEARTBEAT_MISSING" 25 "HEARTBEAT_MISSING" 24 "APP_MIA" 23 "PAUSE_CYCLES" 22 "EPAS_INHIBITED" 21 "USER_KEYFOB" 20 "SC_MIA" 19 "SENSOR_FAILURE" 18 "PRECRUISE_TIMEOUT" 17 "UI_REQUEST" 16 "LOST_DI_CONTROL" 15 "PARK_GEAR" 14 "RESTART_TIMEOUT" 13 "PAUSE_USER_TIMEOUT" 12 "PAUSE_OBSTACLE_TIMEOUT" 11 "ESP_MIA" 10 "SCCM_MIA" 9 "MCU_MIA" 8 "DI_MIA" 7 "EPAS_MIA" 6 "PARK_MIA" 5 "PREGUIDANCE_TIMEOUT" 4 "INVALID_SPACE" 3 "MCU_REQUEST_MISMATCH" 2 "PARK_GUIDANCE_ENDED" 1 "LOST_ANGLE_CONTROL" 0 "NONE" ;
VAL_ 1513 APP_sw283_mainCam 1 "HEALTHY" 0 "FAULTED" ;
VAL_ 1513 APP_sw283_narrowCam 1 "HEALTHY" 0 "FAULTED" ;
VAL_ 1513 APP_sw283_fisheyeCam 1 "HEALTHY" 0 "FAULTED" ;
VAL_ 1513 APP_sw283_leftRepeaterCam 1 "HEALTHY" 0 "FAULTED" ;
VAL_ 1513 APP_sw283_rightRepeaterCam 1 "HEALTHY" 0 "FAULTED" ;
VAL_ 1513 APP_sw283_leftPillarCam 1 "HEALTHY" 0 "FAULTED" ;
VAL_ 1513 APP_sw283_rightPillarCam 1 "HEALTHY" 0 "FAULTED" ;
VAL_ 1513 APP_sw283_bucCam 1 "HEALTHY" 0 "FAULTED" ;
VAL_ 1513 APP_sw325_taskId 93 "CAMERA_HEALTH_FAILED" 92 "POSITIONING_ENGINE_FAILED" 91 "AUDIO_FAILED" 90 "IMU_CALIBRATION_FAILED" 89 "RADAR_EXTENDED_FAILED" 88 "TILE_PROVIDER_FAILED" 87 "RADAR_RECEIVER_FAILED" 86 "TELEMETRY_COMPLIANCE_FAILED" 85 "GEO_REGION_FAILED" 84 "FLEET_CONFIG_FAILED" 83 "X1_CLIENT_FAILED" 82 "SYNC_PIPELINE_FAILED" 81 "RADAR_FAILED" 80 "ULTRASONICS_FAILED" 79 "BEV_GRAPH_FAILED" 78 "CITY_STREETS_BEHAVIOR_FAILED" 77 "BRIDGE_FAILED" 76 "SCHEDULER_FAILED" 75 "DRIVABLE_SPACE_TRACKER_FAILED" 74 "CLIP_LOGGER_FAILED" 73 "HW_MONITOR_FAILED" 72 "PARKING_BEHAVIOR_FAILED" 71 "FIELD_CALIBRATION_FAILED" 70 "DYNAMICS_FAILED" 69 "UI_SERVER_FAILED" 68 "ACTIVE_SAFETY_FAILED" 67 "CAMERA_FAILED" 66 "MAP_MANAGER_FAILED" 65 "DRIVER_MONITOR_FAILED" 63 "LANE_CHANGE_BEHAVIOR_FAILED" 62 "UBX_LOG_FAILED" 61 "IMU_FAILED" 60 "RAIN_LIGHT_SENSING_FAILED" 59 "SNAPSHOT_TRIGGER_CLIENT_FAILED" 58 "STAY_IN_LANE_BEHAVIOR_FAILED" 57 "ATLAS_FAILED" 56 "ROAD_ESTIMATOR_FAILED" 55 "PERCEPTION_FAILED" 54 "MISSION_PLANNER_FAILED" 53 "LOCALIZER_FAILED" 52 "CONTROLLER_FAILED" 51 "AP_STATE_MACHINE_FAILED" 50 "ARBITER_FAILED" 49 "GPS_FAILED" 48 "INERTIATOR_FAILED" 47 "TEMPERATURE_MONITOR_FAILED" 46 "CAN_TX_FAILED" 45 "CAN_RX_FAILED" 44 "WATCHDOG_FAILED" 43 "LEGACY_FAILED" 42 "VISION_FAILED" 41 "SNAPSHOT_FAILED" 40 "TELEMETRY_FAILED" 39 "TELEMETRY_PACKAGER_FAILED" 30 "UNKNOWN_TASK_FAILED" 0 "NO_TASK_FAILED" ;
VAL_ 1513 APP_sw325_issue 30 "NEURAL_NETWORK_DECRYPTION_FAILED" 29 "CAMERA_STREAMS_OUT_OF_SYNC" 28 "TASK_FLOW_TRACE_TIMEOUT" 27 "CANRX_MESSAGE_DROPS" 26 "VEHICLE_CONFIG_MISMATCH" 25 "SYNCHRONOUS_PIPELINE_FLUSH_TOO_LONG" 24 "AVAILABLE_MEMORY_TOO_LOW" 23 "CRITICAL_CAMERA_STREAM_FAILED" 22 "CRITICAL_CAMERA_STREAM_INIT_FAILED" 21 "WATCHDOG_MONITOR_FAILED" 20 "WATCHDOG_PRE_MONITOR_FAILED" 19 "HW_WATCHDOG_DEACTIVATE_FAILED" 18 "HW_WATCHDOG_RUN_FAILED" 17 "HW_WATCHDOG_ACTIVATE_FAILED" 16 "SYNCHRONOUS_PIPELINE_TOO_SLOW" 15 "TASK_TOO_SLOW" 14 "TASK_RESTARTED" 13 "TASK_STATUS_UPDATE_FAILED" 12 "TASK_UNEXPECTED_EXIT" 11 "TASK_CRASHED_EXIT" 10 "TASK_CRASHED_RESUMING" 9 "TASK_CRASHED_SUSPENDING" 8 "TASK_CRASHED_RUN" 7 "TASK_CRASHED_INIT" 6 "TASK_TIMEOUT_STOP_RUNNING" 5 "TASK_TIMEOUT_EXIT" 4 "TASK_TIMEOUT_RESUMING" 3 "TASK_TIMEOUT_SUSPENDING" 2 "TASK_TIMEOUT_RUN" 1 "TASK_TIMEOUT_INIT" 0 "WATCHDOG_TOO_SLOW" ;
VAL_ 1513 APP_sw329_leftLaneChngBehStatus 22 "INVALID_PLAN" 21 "BLOCKED_BY_SLOW_TARGET_R" 20 "BLOCKED_BY_SLOW_TARGET_L" 19 "BAD_ORIGIN_UPDATE" 18 "OUT_OF_DATE" 17 "ROAD_NOT_APPROPRIATE" 16 "BLOCKED_BY_LANE_TYPE_R" 15 "BLOCKED_BY_ULTRASOUND_AND_CAMERA_R" 14 "BLOCKED_BY_BLINDSPOT_CAMERA_INVALID_R" 13 "BLOCKED_BY_BLINDSPOT_CAMERA_R" 12 "BLOCKED_BY_ULTRASOUND_R" 11 "BLOCKED_BY_LANE_TYPE_L" 10 "BLOCKED_BY_ULTRASOUND_AND_CAMERA_L" 9 "BLOCKED_BY_BLINDSPOT_CAMERA_INVALID_L" 8 "BLOCKED_BY_BLINDSPOT_CAMERA_L" 7 "BLOCKED_BY_ULTRASOUND_L" 6 "BUILD_ARGUMENT_FAIL" 5 "NO_TARGET_LANE_ON_MAP" 4 "NO_SOURCE_LANE_ON_MAP" 3 "MAP_NOT_INITIALIZED" 2 "NO_DEST_POLYLANE" 1 "NO_SRC_POLYLANE" 0 "VALID" ;
VAL_ 1513 APP_sw329_rightLaneChngBehStatus 22 "INVALID_PLAN" 21 "BLOCKED_BY_SLOW_TARGET_R" 20 "BLOCKED_BY_SLOW_TARGET_L" 19 "BAD_ORIGIN_UPDATE" 18 "OUT_OF_DATE" 17 "ROAD_NOT_APPROPRIATE" 16 "BLOCKED_BY_LANE_TYPE_R" 15 "BLOCKED_BY_ULTRASOUND_AND_CAMERA_R" 14 "BLOCKED_BY_BLINDSPOT_CAMERA_INVALID_R" 13 "BLOCKED_BY_BLINDSPOT_CAMERA_R" 12 "BLOCKED_BY_ULTRASOUND_R" 11 "BLOCKED_BY_LANE_TYPE_L" 10 "BLOCKED_BY_ULTRASOUND_AND_CAMERA_L" 9 "BLOCKED_BY_BLINDSPOT_CAMERA_INVALID_L" 8 "BLOCKED_BY_BLINDSPOT_CAMERA_L" 7 "BLOCKED_BY_ULTRASOUND_L" 6 "BUILD_ARGUMENT_FAIL" 5 "NO_TARGET_LANE_ON_MAP" 4 "NO_SOURCE_LANE_ON_MAP" 3 "MAP_NOT_INITIALIZED" 2 "NO_DEST_POLYLANE" 1 "NO_SRC_POLYLANE" 0 "VALID" ;
VAL_ 1513 APP_sw362_fasciaCamDeserFault 4 "I2C_UNKNOWN_IOCTL_ERR" 3 "I2C_DATA_NACK" 2 "I2C_SLAVE_ADDR_NACK" 1 "I2C_BUS_FAULT" 0 "NO_I2C_FAULT" ;
VAL_ 1513 APP_sw362_fasciaCamSensorFault 4 "I2C_UNKNOWN_IOCTL_ERR" 3 "I2C_DATA_NACK" 2 "I2C_SLAVE_ADDR_NACK" 1 "I2C_BUS_FAULT" 0 "NO_I2C_FAULT" ;
VAL_ 1513 APP_sw362_fasciaCamSerFault 4 "I2C_UNKNOWN_IOCTL_ERR" 3 "I2C_DATA_NACK" 2 "I2C_SLAVE_ADDR_NACK" 1 "I2C_BUS_FAULT" 0 "NO_I2C_FAULT" ;
VAL_ 1513 APP_sw363_exitStatus 1 "FAULT" 0 "NOMINAL" ;
VAL_ 1513 APP_sw363_tempMonitorFailure 2 "MONITOR_OTHER_FAILURE" 1 "OUT_OF_SPEC" 0 "MONITOR_NO_FAILURE" ;
VAL_ 1513 APP_sw363_imagerHeartbeat 3 "SNA" 1 "STATIC" 0 "NOMINAL" ;
VAL_ 1513 APP_sw363_serializerCrcErrCount 255 "SNA" ;
VAL_ 1513 APP_sw363_currentTemperature 255 "SNA" ;
VAL_ 1513 APP_sw363_minTemperature 255 "SNA" ;
VAL_ 1513 APP_sw363_maxTemperature 255 "SNA" ;
VAL_ 1513 APP_sw364_detectedColorFilter 3 "UNKNOWN" 2 "RGGB" 1 "RCCB" 0 "RCCC" ;
VAL_ 1513 APP_sw364_expectedColorFilter 3 "UNKNOWN" 2 "RGGB" 1 "RCCB" 0 "RCCC" ;
VAL_ 1513 APP_sw364_detectedPosition 10 "FASCIA" 9 "SELFIE" 8 "BACKUP" 7 "R_REPEATER" 6 "L_REPEATER" 5 "R_PILLAR" 4 "L_PILLAR" 3 "FISHEYE" 2 "NARROW" 1 "MAIN" 0 "INVALID" ;
VAL_ 1020 APP_decisionTemperature 0 "UNKNOWN" ;
VAL_ 1020 APP_pascalTemperature 0 "UNKNOWN" ;
VAL_ 1020 APP_parkerATemperature 0 "UNKNOWN" ;
VAL_ 1020 APP_parkerBTemperature 0 "UNKNOWN" ;
VAL_ 1020 APP_pascalExtTemperature 0 "UNKNOWN" ;
VAL_ 1020 APP_parkerExtTemperature 0 "UNKNOWN" ;
VAL_ 1020 APP_pascalHeaterDecision 1 "ON" 0 "OFF" ;
VAL_ 2046 APP_cameraPosition 10 "FASCIA" 9 "SELFIE" 8 "BACKUP" 7 "R_REPEATER" 6 "L_REPEATER" 5 "R_PILLAR" 4 "L_PILLAR" 3 "FISHEYE" 2 "NARROW" 1 "MAIN" 0 "INVALID" ;
VAL_ 2046 APP_mainCamExtPitchCal 511 "SNA" ;
VAL_ 2046 APP_mainCamExtYawCal 511 "SNA" ;
VAL_ 2046 APP_mainCalibTime 127 "SNA" ;
VAL_ 2046 APP_mainCalibProgress 127 "SNA" ;
VAL_ 2046 APP_narrowCamExtPitchCal 511 "SNA" ;
VAL_ 2046 APP_narrowCamExtYawCal 511 "SNA" ;
VAL_ 2046 APP_narrowCalibTime 127 "SNA" ;
VAL_ 2046 APP_narrowCalibProgress 127 "SNA" ;
VAL_ 2046 APP_fisheyeCamExtPitchCal 511 "SNA" ;
VAL_ 2046 APP_fisheyeCamExtYawCal 511 "SNA" ;
VAL_ 2046 APP_fisheyeCalibTime 127 "SNA" ;
VAL_ 2046 APP_fisheyeCalibProgress 127 "SNA" ;
VAL_ 2046 APP_lPillarCamExtPitchCal 511 "SNA" ;
VAL_ 2046 APP_lPillarCamExtYawCal 511 "SNA" ;
VAL_ 2046 APP_lPillarCalibTime 127 "SNA" ;
VAL_ 2046 APP_lPillarCalibProgress 127 "SNA" ;
VAL_ 2046 APP_rPillarCamExtPitchCal 511 "SNA" ;
VAL_ 2046 APP_rPillarCamExtYawCal 511 "SNA" ;
VAL_ 2046 APP_rPillarCalibTime 127 "SNA" ;
VAL_ 2046 APP_rPillarCalibProgress 127 "SNA" ;
VAL_ 2046 APP_lRepeatCamExtPitchCal 511 "SNA" ;
VAL_ 2046 APP_lRepeatCamExtYawCal 511 "SNA" ;
VAL_ 2046 APP_lRepeatCalibTime 127 "SNA" ;
VAL_ 2046 APP_lRepeatCalibProgress 127 "SNA" ;
VAL_ 2046 APP_rRepeatCamExtPitchCal 511 "SNA" ;
VAL_ 2046 APP_rRepeatCamExtYawCal 511 "SNA" ;
VAL_ 2046 APP_rRepeatCalibTime 127 "SNA" ;
VAL_ 2046 APP_rRepeatCalibProgress 127 "SNA" ;
VAL_ 2046 APP_backupCamExtPitchCal 511 "SNA" ;
VAL_ 2046 APP_backupCamExtYawCal 511 "SNA" ;
VAL_ 2046 APP_backupCalibTime 127 "SNA" ;
VAL_ 2046 APP_backupCalibProgress 127 "SNA" ;
VAL_ 1018 APP_mainCameraLUX 255 "SNA" 254 "SATURATED" ;
VAL_ 1018 APP_narrowCameraLUX 255 "SNA" 254 "SATURATED" ;
VAL_ 1018 APP_fisheyeCameraLUX 255 "SNA" 254 "SATURATED" ;
VAL_ 1018 APP_lRepeatCameraLUX 255 "SNA" 254 "SATURATED" ;
VAL_ 1018 APP_rRepeatCameraLUX 255 "SNA" 254 "SATURATED" ;
VAL_ 1018 APP_lPillarCameraLUX 255 "SNA" 254 "SATURATED" ;
VAL_ 1018 APP_rPillarCameraLUX 255 "SNA" 254 "SATURATED" ;
VAL_ 1018 APP_backupCameraLUX 255 "SNA" 254 "SATURATED" ;
VAL_ 1177 APP_rRepeaterCameraTemperature 255 "SNA" ;
VAL_ 1177 APP_lRepeaterCameraTemperature 255 "SNA" ;
VAL_ 843 APP_frontLeftParkAssist 255 "SNA" ;
VAL_ 843 APP_frontLeftMiddleParkAssist 255 "SNA" ;
VAL_ 843 APP_frontMiddleParkAssist 255 "SNA" ;
VAL_ 843 APP_frontRightMiddleParkAssist 255 "SNA" ;
VAL_ 843 APP_frontRightParkAssist 255 "SNA" ;
VAL_ 843 APP_parkAssistStatus 3 "SNA" 2 "TEMPORARY_FAILURE" 1 "ENABLED" 0 "DISABLED" ;
VAL_ 1353 APP_infoIndex 3 "AP_BOOT_COUNT" 2 "AP_GITHASH" 1 "FW_GITHASH" 0 "AP_BUILD_TYPE" ;
VAL_ 1353 APP_buildType 3 "AP_BUILDTYPE_REPO" 1 "AP_BUILDTYPE_LOCAL" 0 "AP_BUILDTYPE_SIGNED" ;
VAL_ 907 APP_rearLeftParkAssist 255 "SNA" ;
VAL_ 907 APP_rearLeftMiddleParkAssist 255 "SNA" ;
VAL_ 907 APP_rearMiddleParkAssist 255 "SNA" ;
VAL_ 907 APP_rearRightMiddleParkAssist 255 "SNA" ;
VAL_ 907 APP_rearRightParkAssist 255 "SNA" ;
VAL_ 601 APP_watchdogState 7 "AP_WDOG_STATE_SNA" 4 "AP_WDOG_STATE_SHUTTING_DOWN" 3 "AP_WDOG_STATE_HEALTHY" 2 "AP_WDOG_STATE_CRITICAL" 1 "AP_WDOG_STATE_DEGRADED" 0 "AP_WDOG_STATE_UNKNOWN" ;
VAL_ 601 APP_fusedState 3 "APP_FUSE_SNA" 2 "APP_FUSE_FUSED" 1 "APP_FUSE_UNFUSED" 0 "APP_FUSE_UNKNOWN" ;
VAL_ 601 APP_factorySummonStatus 8 "FACTORY_SUMMON_END_OF_ROUTE" 7 "FACTORY_SUMMON_UNAVAILABLE_HEADING_NOT_INITIALIZED" 6 "FACTORY_SUMMON_UNAVAILABLE_VEHICLE_SPEED_INVALID" 5 "FACTORY_SUMMON_UNAVAILABLE_NO_GPS" 4 "FACTORY_SUMMON_UNAVAILABLE_GOAL_TOO_FAR" 3 "FACTORY_SUMMON_UNAVAILABLE_NO_QR_INSTRUCTION" 2 "FACTORY_SUMMON_AVAILABLE" 1 "FACTORY_SUMMON_ACTIVE" 0 "FACTORY_SUMMON_SNA" ;
VAL_ 601 APP_clipRecordingStatus 4 "APP_CLIP_FAULTED" 3 "APP_CLIP_TRIGGERED" 2 "APP_CLIP_RECORDING" 1 "APP_CLIP_IDLE" 0 "APP_CLIP_NO_DRIVE" ;
VAL_ 601 APP_summonUnavailableReason 28 "SMART_SUMMON_UNAVAILABLE_OUTSIDE_GEOFENCE" 27 "SMART_SUMMON_UNAVAILABLE_ACCEL_PEDAL_PRESSED" 26 "SMART_SUMMON_UNAVAILABLE_BRAKE_PEDAL_PRESSED" 25 "SMART_SUMMON_UNAVAILABLE_REMOTE_STOP_OR_ABORT_REQUEST_ACTIVE" 24 "SMART_SUMMON_UNAVAILABLE_CLOSURE_OPEN" 23 "SMART_SUMMON_UNAVAILABLE_LOW_TIRE_PRESSURE" 22 "SMART_SUMMON_UNAVAILABLE_EXTENDED_COMPUTE_INACTIVE" 21 "SMART_SUMMON_UNAVAILABLE_HIGH_GRADE" 20 "SMART_SUMMON_UNAVAILABLE_NO_CONTEXT" 19 "SMART_SUMMON_UNAVAILABLE_PUBLIC_ROAD_BOUNDARIES_NOT_VALID" 18 "SMART_SUMMON_UNAVAILABLE_ALL_SENSORS_OCCLUDED" 17 "SMART_SUMMON_UNAVAILABLE_ULTRASONIC_STALE" 16 "SMART_SUMMON_UNAVAILABLE_VISION_HEALTH_CRITICAL" 15 "SMART_SUMMON_UNAVAILABLE_CAMERA_NOT_CALIBRATED" 14 "SMART_SUMMON_UNAVAILABLE_END_OF_LEASH" 13 "SMART_SUMMON_UNAVAILABLE_PHONE_IS_TOO_FAR" 12 "SMART_SUMMON_UNAVAILABLE_EGO_GPS_UNAVAILABLE" 11 "SMART_SUMMON_UNAVAILABLE_PHONE_GPS_UNAVAILABLE" 10 "SMART_SUMMON_UNAVAILABLE_POOR_CONNECTION" 9 "SMART_SUMMON_UNAVAILABLE_PUBLIC_ROAD" 8 "SMART_SUMMON_UNAVAILABLE_EAC_UNAVAILABLE" 7 "SMART_SUMMON_UNAVAILABLE_CRUISE_UNAVAILABLE" 6 "SMART_SUMMON_UNAVAILABLE_ULTRASONIC_FAULT" 5 "SMART_SUMMON_UNAVAILABLE_ULTRASONIC_BLOCKED" 4 "SMART_SUMMON_UNAVAILABLE_CAMERA_BLOCKED" 3 "SMART_SUMMON_UNAVAILABLE_CAMERA_STREAM" 2 "SMART_SUMMON_UNAVAILABLE_NOT_IN_PARK" 1 "SMART_SUMMON_UNAVAILABLE_NONE" 0 "SMART_SUMMON_UNAVAILABLE_UNKNOWN" ;
VAL_ 601 APP_fsdSuspendState 3 "SNA" 1 "SUSPENDED" 0 "NOT_SUSPENDED" ;
VAL_ 601 APP_fsdRevokeStrikeoutCount 7 "SNA" ;
VAL_ 601 APP_teslaVisionSupported 3 "SNA" 1 "SUPPORTED" 0 "NOT_SUPPORTED" ;
VAL_ 601 APP_teslaVisionUnsupportedReason 4 "VEHICLE_LOCATION" 3 "UNSUPPORTED_CAMERA" 2 "AP_HARDWARE" 1 "NONE" 0 "UNKNOWN" ;
VAL_ 601 APP_fsdRevokeCount 7 "SNA" ;
VAL_ 601 APP_unifiedObjectStackSupported 3 "SNA" 1 "SUPPORTED" 0 "NOT_SUPPORTED" ;
VAL_ 601 APP_unifiedObjsUnsupportedReason 4 "VEHICLE_LOCATION" 3 "UNSUPPORTED_CAMERA" 2 "AP_HARDWARE" 1 "NONE" 0 "UNKNOWN" ;
VAL_ 601 APP_DDAWSystemStatus 4 "DDAW_SYSTEM_SNA" 3 "DDAW_SYSTEM_INVALID" 2 "DDAW_SYSTEM_FAILURE" 1 "DDAW_SYSTEM_DRIVER_DROWSY" 0 "DDAW_SYSTEM_NOMINAL" ;
VAL_ 601 APP_socOperatingMode 2 "AP_DUAL_SOC" 1 "AP_SINGLE_SOC" 0 "AP_UNKNOWN" ;
VAL_ 601 APP_summonVersionIdentifier 1 "ACTUALLY_SMART_SUMMON" 0 "LEGACY_SMART_SUMMON" ;
VAL_ 601 APP_sentryState 6 "SENTRY_SNA" 5 "SENTRY_QUIET" 4 "SENTRY_PANIC" 3 "SENTRY_AWARE" 2 "SENTRY_ARMED" 1 "SENTRY_IDLE" 0 "SENTRY_OFF" ;
VAL_ 601 APP_autoparkVersionIdentifier 2 "ACTUALLY_SMART_AUTOPARK" 1 "V3_VISION_AUTOPARK" 0 "LEGACY_AUTOPARK" ;
VAL_ 601 APP_setSpeedMode 2 "AUTO" 1 "MAX_SPEED" 0 "TARGET_SPEED" ;
VAL_ 605 APP_tcFeatureState 3 "TC_ACTIVE" 2 "TC_AVAILABLE" 1 "TC_UNAVAILABLE" 0 "TC_DISABLED" ;
VAL_ 605 APP_tcStateMachine 6 "TCSM_CONTINUING" 5 "TCSM_STOPPED" 4 "TCSM_STOPPING" 3 "TCSM_WARNING" 2 "TCSM_AWARE" 1 "TCSM_STANDBY" 0 "TCSM_DISABLED" ;
VAL_ 605 APP_tcControlSource 3 "TC_SOURCE_MAP_AND_VISION" 2 "TC_SOURCE_VISION" 1 "TC_SOURCE_MAP" 0 "TC_SOURCE_NONE" ;
VAL_ 605 APP_tcControlType 22 "TC_TYPE_T_ARM" 21 "TC_TYPE_BEV_JUNCTION" 20 "TC_TYPE_T_IMPLICIT_BY_GEOM" 19 "TC_TYPE_T_IMPLICIT_BY_NAME" 18 "TC_TYPE_T_IMPLICIT" 17 "TC_TYPE_NO_STOP" 16 "TC_TYPE_BIKE_MERGE_FROM_RIGHT" 15 "TC_TYPE_BIKE_MERGE_FROM_LEFT" 14 "TC_TYPE_ALL_WAY_STOP_SIGN" 13 "TC_TYPE_TRAFFIC_RULE" 12 "TC_TYPE_SPEED_HUMP" 11 "TC_TYPE_SPEED_BUMP" 10 "TC_TYPE_RAMP_METER" 9 "TC_TYPE_PEDESTRIAN_CROSSING" 8 "TC_TYPE_SUICIDE_LEFT" 7 "TC_TYPE_KEEP_CLEAR_EXIT" 6 "TC_TYPE_KEEP_CLEAR_ENTER" 5 "TC_TYPE_CROSSWALK" 4 "TC_TYPE_YIELD" 3 "TC_TYPE_TRAFFIC_LIGHT" 2 "TC_TYPE_STOP_SIGN" 1 "TC_TYPE_UNKNOWN" 0 "TC_TYPE_INVALID" ;
VAL_ 605 APP_tcControlDistance 255 "SNA" ;
VAL_ 605 APP_tcControlLightState 6 "TC_LIGHTSTATE_OTHER" 5 "TC_LIGHTSTAET_WHITE" 4 "TC_LIGHTSTATE_OFF" 3 "TC_LIGHTSTATE_YELLOW" 2 "TC_LIGHTSTATE_GREEN" 1 "TC_LIGHTSTATE_RED" 0 "TC_LIGHTSTATE_NONE" ;
VAL_ 605 APP_tcContinuationReason 13 "TC_CONTINUE_CONTROL_UNAVAILABLE" 12 "TC_CONTINUE_SUMMON_TIMEOUT" 11 "TC_CONTINUE_CLEAR_TO_GO" 10 "TC_CONTINUE_WARNING_TIMEOUT" 9 "TC_CONTINUE_INVALID_MAP_OR_VISION_CONTROL" 8 "TC_CONTINUE_PASSED_STOP" 7 "TC_CONTINUE_ASSUMED_DRIVER_STOPPED" 6 "TC_CONTINUE_AP_ACTIVATED_ON_HARD_STOP" 5 "TC_CONTINUE_VISION_SIGNALS" 4 "TC_CONTINUE_REQUIRED_DECEL_TOO_HIGH" 3 "TC_CONTINUE_USER_INPUT_ON_RED" 2 "TC_CONTINUE_USER_INPUT_ON_GREEN" 1 "TC_CONTINUE_GREEN_LIGHT_WITH_CIPV" 0 "TC_CONTINUE_NONE" ;
VAL_ 605 APP_tcConfirmationType 2 "TC_CONFIRM_PEDAL" 1 "TC_CONFIRM_STALK" 0 "TC_CONFIRM_NONE" ;
VAL_ 605 APP_tcWarningSuppressionReason 18 "TC_WARNING_SUPPRESS_TOO_FAR_FROM_PREDICTED_JUNCTION" 17 "TC_WARNING_SUPPRESS_NOT_SUPPORTED_BY_MEASUREMENTS" 16 "TC_WARNING_SUPPRESS_NO_ASSOCIATED_VISION_LINE" 15 "TC_WARNING_SUPPRESS_AMBIGUOUS_VISION_TYPE" 14 "TC_WARNING_SUPPRESS_CIPV_DID_NOT_STOP" 13 "TC_WARNING_SUPPRESS_STALE_SIGN_DETECTION" 12 "TC_WARNING_SUPPRESS_WRONG_MAP_TYPE" 11 "TC_WARNING_SUPPRESS_LIGHT_UNASSOCIATED" 10 "TC_WARNING_SUPPRESS_CIPV_CONTINUING" 9 "TC_WARNING_SUPPRESS_PEDAL_OVERRIDE" 8 "TC_WARNING_SUPPRESS_LOCALIZATION_DEGRADED" 7 "TC_WARNING_SUPPRESS_HARD_TURN" 6 "TC_WARNING_SUPPRESS_ASSUMED_YELLOW" 5 "TC_WARNING_SUPPRESS_DRIVER_SLOWING_DOWN" 4 "TC_WARNING_SUPPRESS_BELOW_MIN_SPEED" 3 "TC_WARNING_SUPPRESS_SLOWDOWN_PLANNED" 2 "TC_WARNING_SUPPRESS_INSUFFICIENT_DATA" 1 "TC_WARNING_SUPPRESS_FEATURE_DISABLED" 0 "TC_WARNING_SUPPRESS_NONE" ;
VAL_ 605 APP_tcUnavailableReason 9 "AP_UNAVAILBLE_SUN_GLARE_ON_ROAD_RESTRICTED" 8 "AP_UNAVAILBLE_CAMERA_BLINDED_ON_ROAD_RESTRICTED" 7 "AP_UNAVAILBLE_GPS_DEGRADED" 6 "AP_UNAVAILBLE_ROAD_ESTIMATOR_UNHEALTHY" 5 "AP_UNAVAILBLE_SUN_GLARE" 4 "AP_UNAVAILBLE_CAMERA_BLINDED" 3 "AP_UNAVAILBLE_ROAD_CLASS" 2 "AP_UNAVAILBLE_LOST_MAP_LOCALIZATION" 1 "AP_UNAVAILBLE_MCU_DISABLED" 0 "AP_UNAVAILBLE_NONE" ;
VAL_ 2045 APP_visionOcsStateRaw 3 "ADULT" 2 "CHILD" 1 "EMPTY" 0 "UNKNOWN" ;
VAL_ 2045 APP_visionOcsEmptyProbRaw 255 "SNA" ;
VAL_ 2045 APP_visionOcsChildProbRaw 255 "SNA" ;
VAL_ 2045 APP_visionOcsAdultProbRaw 255 "SNA" ;
VAL_ 2045 APP_visionOcsFrontPasClsVisionSt 3 "ADULT" 2 "CHILD" 1 "EMPTY" 0 "UNKNOWN" ;
